VERSION ""

NS_ :

BS_:

BU_: External_Tool ADAS RDR05 RDR_Fusion_Partner RDR_Gateway

BO_ 1600 RDR_TRACKER_OBJ_049: 64 RDR05
 SG_ OBJ_ALIVE_TIME_049 : 255|16@0+ (1,0) [0|65535] "ms"  ADAS
 SG_ OBJ_ACCELERATION_LONG_ERR_049 : 215|8@0+ (0.025,0) [0|6.375] "m/s^2"  ADAS
 SG_ OBJ_ACCELERATION_LAT_ERR_049 : 223|8@0+ (0.025,0) [0|6.375] "m/s^2"  ADAS
 SG_ OBJ_VELOCITY_LONG_ERR_049 : 143|8@0+ (0.05,0) [0|12.75] "m/s"  ADAS
 SG_ OBJ_VELOCITY_LAT_ERR_049 : 151|8@0+ (0.05,0) [0|12.75] "m/s"  ADAS
 SG_ OBJ_POS_LONG_ERR_049 : 95|8@0+ (0.025,0) [0|6.375] "m"  ADAS
 SG_ OBJ_POS_LAT_ERR_049 : 103|8@0+ (0.025,0) [0|6.375] "m"  ADAS
 SG_ OBJ_TRACK_MOTION_MODEL_049 : 9|2@0+ (1,0) [0|3] "NA"  ADAS
 SG_ OBJ_DIMENSION_WIDTH_049 : 17|10@0+ (0.01,0) [0|10.23] "m"  ADAS
 SG_ OBJ_DIMENSION_LENGTH_049 : 37|12@0+ (0.01,0) [0|40.95] "m"  ADAS
 SG_ OBJ_EXISTENCE_PROB_049 : 229|14@0+ (0.0001,0) [0|1] "NA"  ADAS
 SG_ OBJ_YAW_ANGLE_049 : 155|12@0+ (0.005,-10) [-10|10.475] "rad"  ADAS
 SG_ OBJ_YAW_ANGLE_ERR_049 : 175|7@0+ (0.01,0) [0|1.27] "rad"  ADAS
 SG_ OBJ_ID_049 : 7|8@0+ (1,0) [0|255] "NA"  ADAS
 SG_ OBJ_MOVEMENT_STATUS_049 : 196|3@0+ (1,0) [0|3] "NA"  ADAS
 SG_ OBJ_MEASUREMENT_STATUS_049 : 14|3@0+ (1,0) [0|7] "NA"  ADAS
 SG_ OBJ_POS_LONG_049 : 63|16@0+ (0.01,-327) [-327|327] "m"  ADAS
 SG_ OBJ_POS_LAT_049 : 79|16@0+ (0.01,-327) [-327|327] "m"  ADAS
 SG_ OBJ_VELOCITY_LONG_049 : 110|15@0+ (0.01,-163) [-163|163] "m/s"  ADAS
 SG_ OBJ_VELOCITY_LAT_049 : 126|15@0+ (0.01,-163) [-163|163] "m/s"  ADAS
 SG_ OBJ_ACCELERATION_LONG_049 : 193|10@0+ (0.05,-20) [-20|20] "m/s^2"  ADAS
 SG_ OBJ_ACCELERATION_LAT_049 : 177|10@0+ (0.05,-20) [-20|20] "m/s^2"  ADAS
 SG_ OBJ_VEH_TRACK_FLAG_049 : 10|1@0+ (1,0) [0|1] "NA"  ADAS
 SG_ OBJ_MH_CYCLE_COUNTER_049 : 487|8@0+ (1,0) [0|255] "NA"  ADAS
 SG_ OBJ_MH_CRC16_049 : 495|16@0+ (1,0) [0|65535] "NA"  ADAS
 SG_ OBJ_TIMESTAMP_OFFSET_049 : 247|8@0+ (1,-127) [-127|128] "ms"  ADAS
 SG_ OBJ_DIMENSION_WIDTH_ERR_049 : 23|6@0+ (0.01,0) [0|0.63] "m"  ADAS
 SG_ OBJ_DIMENSION_LENGTH_ERR_049 : 41|10@0+ (0.01,0) [0|10.23] "m"  ADAS
 SG_ OBJ_CLS_TYPE1_049 : 271|4@0+ (1,0) [0|15] "NA"  ADAS
 SG_ OBJ_CLS_TYPE1_PROB_049 : 303|8@0+ (0.004,0) [0|1] "NA"  ADAS
 SG_ OBJ_CLS_TYPE2_049 : 267|4@0+ (1,0) [0|15] "NA"  ADAS
 SG_ OBJ_CLS_TYPE2_PROB_049 : 311|8@0+ (0.004,0) [0|1] "NA"  ADAS
 SG_ OBJ_CLS_TYPE3_049 : 279|4@0+ (1,0) [0|15] "NA"  ADAS
 SG_ OBJ_CLS_TYPE3_PROB_049 : 319|8@0+ (0.004,0) [0|1] "NA"  ADAS
 SG_ OBJ_CLS_TYPE4_049 : 275|4@0+ (1,0) [0|15] "NA"  ADAS
 SG_ OBJ_CLS_TYPE4_PROB_049 : 327|8@0+ (0.004,0) [0|1] "NA"  ADAS
 SG_ OBJ_CLS_TYPE5_049 : 287|4@0+ (1,0) [0|15] "NA"  ADAS
 SG_ OBJ_CLS_TYPE5_PROB_049 : 335|8@0+ (0.004,0) [0|1] "NA"  ADAS
 SG_ OBJ_CLS_TYPE6_049 : 282|4@0+ (1,0) [0|15] "NA"  ADAS
 SG_ OBJ_CLS_TYPE6_PROB_049 : 343|8@0+ (0.004,0) [0|1] "NA"  ADAS
 SG_ OBJ_RCS_049 : 351|7@0+ (1,-64) [-64|63] "dBsm"  ADAS
 SG_ OBJ_REF_PT_LONG_OFFSET_049 : 357|14@0+ (0.0001,0) [0|1] "NA"  ADAS
 SG_ OBJ_REF_PT_LAT_OFFSET_049 : 370|14@0+ (0.0001,0) [0|1] "NA"  ADAS
 SG_ OBJ_YAW_RATE_049 : 399|10@0+ (0.005,-2.24) [-2.24|2.24] "rad/s"  ADAS
 SG_ OBJ_YAW_RATE_ERR_049 : 388|5@0+ (0.025,0) [0|0.775] "rad/s"  ADAS
 SG_ OBJ_GROUP_ID_049 : 405|6@0+ (1,0) [0|63] "NA"  ADAS
 SG_ OBJ_POS_ERR_CRR_COEF_049 : 415|8@0+ (0.01,-1.2) [-1.2|1] "NA"  ADAS
 SG_ OBJ_VELOCITY_ERR_CRR_COEF_049 : 423|8@0+ (0.01,-1.2) [-1.2|1] "NA"  ADAS
 SG_ OBJ_ACCEL_ERR_CRR_COEF_049 : 431|8@0+ (0.01,-1.2) [-1.2|1] "NA"  ADAS

BO_ 1601 RDR_TRACKER_OBJ_050: 64 RDR05
 SG_ OBJ_ALIVE_TIME_050 : 255|16@0+ (1,0) [0|65535] "ms"  ADAS
 SG_ OBJ_ACCELERATION_LONG_ERR_050 : 215|8@0+ (0.025,0) [0|6.375] "m/s^2"  ADAS
 SG_ OBJ_ACCELERATION_LAT_ERR_050 : 223|8@0+ (0.025,0) [0|6.375] "m/s^2"  ADAS
 SG_ OBJ_VELOCITY_LONG_ERR_050 : 143|8@0+ (0.05,0) [0|12.75] "m/s"  ADAS
 SG_ OBJ_VELOCITY_LAT_ERR_050 : 151|8@0+ (0.05,0) [0|12.75] "m/s"  ADAS
 SG_ OBJ_POS_LONG_ERR_050 : 95|8@0+ (0.025,0) [0|6.375] "m"  ADAS
 SG_ OBJ_POS_LAT_ERR_050 : 103|8@0+ (0.025,0) [0|6.375] "m"  ADAS
 SG_ OBJ_TRACK_MOTION_MODEL_050 : 9|2@0+ (1,0) [0|3] "NA"  ADAS
 SG_ OBJ_DIMENSION_WIDTH_050 : 17|10@0+ (0.01,0) [0|10.23] "m"  ADAS
 SG_ OBJ_DIMENSION_LENGTH_050 : 37|12@0+ (0.01,0) [0|40.95] "m"  ADAS
 SG_ OBJ_EXISTENCE_PROB_050 : 229|14@0+ (0.0001,0) [0|1] "NA"  ADAS
 SG_ OBJ_YAW_ANGLE_050 : 155|12@0+ (0.005,-10) [-10|10.475] "rad"  ADAS
 SG_ OBJ_YAW_ANGLE_ERR_050 : 175|7@0+ (0.01,0) [0|1.27] "rad"  ADAS
 SG_ OBJ_ID_050 : 7|8@0+ (1,0) [0|255] "NA"  ADAS
 SG_ OBJ_MOVEMENT_STATUS_050 : 196|3@0+ (1,0) [0|3] "NA"  ADAS
 SG_ OBJ_MEASUREMENT_STATUS_050 : 14|3@0+ (1,0) [0|7] "NA"  ADAS
 SG_ OBJ_POS_LONG_050 : 63|16@0+ (0.01,-327) [-327|327] "m"  ADAS
 SG_ OBJ_POS_LAT_050 : 79|16@0+ (0.01,-327) [-327|327] "m"  ADAS
 SG_ OBJ_VELOCITY_LONG_050 : 110|15@0+ (0.01,-163) [-163|163] "m/s"  ADAS
 SG_ OBJ_VELOCITY_LAT_050 : 126|15@0+ (0.01,-163) [-163|163] "m/s"  ADAS
 SG_ OBJ_ACCELERATION_LONG_050 : 193|10@0+ (0.05,-20) [-20|20] "m/s^2"  ADAS
 SG_ OBJ_ACCELERATION_LAT_050 : 177|10@0+ (0.05,-20) [-20|20] "m/s^2"  ADAS
 SG_ OBJ_VEH_TRACK_FLAG_050 : 10|1@0+ (1,0) [0|1] "NA"  ADAS
 SG_ OBJ_MH_CYCLE_COUNTER_050 : 487|8@0+ (1,0) [0|255] "NA"  ADAS
 SG_ OBJ_MH_CRC16_050 : 495|16@0+ (1,0) [0|65535] "NA"  ADAS
 SG_ OBJ_TIMESTAMP_OFFSET_050 : 247|8@0+ (1,-127) [-127|128] "ms"  ADAS
 SG_ OBJ_DIMENSION_WIDTH_ERR_050 : 23|6@0+ (0.01,0) [0|0.63] "m"  ADAS
 SG_ OBJ_DIMENSION_LENGTH_ERR_050 : 41|10@0+ (0.01,0) [0|10.23] "m"  ADAS
 SG_ OBJ_CLS_TYPE1_050 : 271|4@0+ (1,0) [0|15] "NA"  ADAS
 SG_ OBJ_CLS_TYPE1_PROB_050 : 303|8@0+ (0.004,0) [0|1] "NA"  ADAS
 SG_ OBJ_CLS_TYPE2_050 : 267|4@0+ (1,0) [0|15] "NA"  ADAS
 SG_ OBJ_CLS_TYPE2_PROB_050 : 311|8@0+ (0.004,0) [0|1] "NA"  ADAS
 SG_ OBJ_CLS_TYPE3_050 : 279|4@0+ (1,0) [0|15] "NA"  ADAS
 SG_ OBJ_CLS_TYPE3_PROB_050 : 319|8@0+ (0.004,0) [0|1] "NA"  ADAS
 SG_ OBJ_CLS_TYPE4_050 : 275|4@0+ (1,0) [0|15] "NA"  ADAS
 SG_ OBJ_CLS_TYPE4_PROB_050 : 327|8@0+ (0.004,0) [0|1] "NA"  ADAS
 SG_ OBJ_CLS_TYPE5_050 : 287|4@0+ (1,0) [0|15] "NA"  ADAS
 SG_ OBJ_CLS_TYPE5_PROB_050 : 335|8@0+ (0.004,0) [0|1] "NA"  ADAS
 SG_ OBJ_CLS_TYPE6_050 : 282|4@0+ (1,0) [0|15] "NA"  ADAS
 SG_ OBJ_CLS_TYPE6_PROB_050 : 343|8@0+ (0.004,0) [0|1] "NA"  ADAS
 SG_ OBJ_RCS_050 : 351|7@0+ (1,-64) [-64|63] "dBsm"  ADAS
 SG_ OBJ_REF_PT_LONG_OFFSET_050 : 357|14@0+ (0.0001,0) [0|1] "NA"  ADAS
 SG_ OBJ_REF_PT_LAT_OFFSET_050 : 370|14@0+ (0.0001,0) [0|1] "NA"  ADAS
 SG_ OBJ_YAW_RATE_050 : 399|10@0+ (0.005,-2.24) [-2.24|2.24] "rad/s"  ADAS
 SG_ OBJ_YAW_RATE_ERR_050 : 388|5@0+ (0.025,0) [0|0.775] "rad/s"  ADAS
 SG_ OBJ_GROUP_ID_050 : 405|6@0+ (1,0) [0|63] "NA"  ADAS
 SG_ OBJ_POS_ERR_CRR_COEF_050 : 415|8@0+ (0.01,-1.2) [-1.2|1] "NA"  ADAS
 SG_ OBJ_VELOCITY_ERR_CRR_COEF_050 : 423|8@0+ (0.01,-1.2) [-1.2|1] "NA"  ADAS
 SG_ OBJ_ACCEL_ERR_CRR_COEF_050 : 431|8@0+ (0.01,-1.2) [-1.2|1] "NA"  ADAS

BO_ 1602 RDR_TRACKER_OBJ_051: 64 RDR05
 SG_ OBJ_ALIVE_TIME_051 : 255|16@0+ (1,0) [0|65535] "ms"  ADAS
 SG_ OBJ_ACCELERATION_LONG_ERR_051 : 215|8@0+ (0.025,0) [0|6.375] "m/s^2"  ADAS
 SG_ OBJ_ACCELERATION_LAT_ERR_051 : 223|8@0+ (0.025,0) [0|6.375] "m/s^2"  ADAS
 SG_ OBJ_VELOCITY_LONG_ERR_051 : 143|8@0+ (0.05,0) [0|12.75] "m/s"  ADAS
 SG_ OBJ_VELOCITY_LAT_ERR_051 : 151|8@0+ (0.05,0) [0|12.75] "m/s"  ADAS
 SG_ OBJ_POS_LONG_ERR_051 : 95|8@0+ (0.025,0) [0|6.375] "m"  ADAS
 SG_ OBJ_POS_LAT_ERR_051 : 103|8@0+ (0.025,0) [0|6.375] "m"  ADAS
 SG_ OBJ_TRACK_MOTION_MODEL_051 : 9|2@0+ (1,0) [0|3] "NA"  ADAS
 SG_ OBJ_DIMENSION_WIDTH_051 : 17|10@0+ (0.01,0) [0|10.23] "m"  ADAS
 SG_ OBJ_DIMENSION_LENGTH_051 : 37|12@0+ (0.01,0) [0|40.95] "m"  ADAS
 SG_ OBJ_EXISTENCE_PROB_051 : 229|14@0+ (0.0001,0) [0|1] "NA"  ADAS
 SG_ OBJ_YAW_ANGLE_051 : 155|12@0+ (0.005,-10) [-10|10.475] "rad"  ADAS
 SG_ OBJ_YAW_ANGLE_ERR_051 : 175|7@0+ (0.01,0) [0|1.27] "rad"  ADAS
 SG_ OBJ_ID_051 : 7|8@0+ (1,0) [0|255] "NA"  ADAS
 SG_ OBJ_MOVEMENT_STATUS_051 : 196|3@0+ (1,0) [0|3] "NA"  ADAS
 SG_ OBJ_MEASUREMENT_STATUS_051 : 14|3@0+ (1,0) [0|7] "NA"  ADAS
 SG_ OBJ_POS_LONG_051 : 63|16@0+ (0.01,-327) [-327|327] "m"  ADAS
 SG_ OBJ_POS_LAT_051 : 79|16@0+ (0.01,-327) [-327|327] "m"  ADAS
 SG_ OBJ_VELOCITY_LONG_051 : 110|15@0+ (0.01,-163) [-163|163] "m/s"  ADAS
 SG_ OBJ_VELOCITY_LAT_051 : 126|15@0+ (0.01,-163) [-163|163] "m/s"  ADAS
 SG_ OBJ_ACCELERATION_LONG_051 : 193|10@0+ (0.05,-20) [-20|20] "m/s^2"  ADAS
 SG_ OBJ_ACCELERATION_LAT_051 : 177|10@0+ (0.05,-20) [-20|20] "m/s^2"  ADAS
 SG_ OBJ_VEH_TRACK_FLAG_051 : 10|1@0+ (1,0) [0|1] "NA"  ADAS
 SG_ OBJ_MH_CYCLE_COUNTER_051 : 487|8@0+ (1,0) [0|255] "NA"  ADAS
 SG_ OBJ_MH_CRC16_051 : 495|16@0+ (1,0) [0|65535] "NA"  ADAS
 SG_ OBJ_TIMESTAMP_OFFSET_051 : 247|8@0+ (1,-127) [-127|128] "ms"  ADAS
 SG_ OBJ_DIMENSION_WIDTH_ERR_051 : 23|6@0+ (0.01,0) [0|0.63] "m"  ADAS
 SG_ OBJ_DIMENSION_LENGTH_ERR_051 : 41|10@0+ (0.01,0) [0|10.23] "m"  ADAS
 SG_ OBJ_CLS_TYPE1_051 : 271|4@0+ (1,0) [0|15] "NA"  ADAS
 SG_ OBJ_CLS_TYPE1_PROB_051 : 303|8@0+ (0.004,0) [0|1] "NA"  ADAS
 SG_ OBJ_CLS_TYPE2_051 : 267|4@0+ (1,0) [0|15] "NA"  ADAS
 SG_ OBJ_CLS_TYPE2_PROB_051 : 311|8@0+ (0.004,0) [0|1] "NA"  ADAS
 SG_ OBJ_CLS_TYPE3_051 : 279|4@0+ (1,0) [0|15] "NA"  ADAS
 SG_ OBJ_CLS_TYPE3_PROB_051 : 319|8@0+ (0.004,0) [0|1] "NA"  ADAS
 SG_ OBJ_CLS_TYPE4_051 : 275|4@0+ (1,0) [0|15] "NA"  ADAS
 SG_ OBJ_CLS_TYPE4_PROB_051 : 327|8@0+ (0.004,0) [0|1] "NA"  ADAS
 SG_ OBJ_CLS_TYPE5_051 : 287|4@0+ (1,0) [0|15] "NA"  ADAS
 SG_ OBJ_CLS_TYPE5_PROB_051 : 335|8@0+ (0.004,0) [0|1] "NA"  ADAS
 SG_ OBJ_CLS_TYPE6_051 : 282|4@0+ (1,0) [0|15] "NA"  ADAS
 SG_ OBJ_CLS_TYPE6_PROB_051 : 343|8@0+ (0.004,0) [0|1] "NA"  ADAS
 SG_ OBJ_RCS_051 : 351|7@0+ (1,-64) [-64|63] "dBsm"  ADAS
 SG_ OBJ_REF_PT_LONG_OFFSET_051 : 357|14@0+ (0.0001,0) [0|1] "NA"  ADAS
 SG_ OBJ_REF_PT_LAT_OFFSET_051 : 370|14@0+ (0.0001,0) [0|1] "NA"  ADAS
 SG_ OBJ_YAW_RATE_051 : 399|10@0+ (0.005,-2.24) [-2.24|2.24] "rad/s"  ADAS
 SG_ OBJ_YAW_RATE_ERR_051 : 388|5@0+ (0.025,0) [0|0.775] "rad/s"  ADAS
 SG_ OBJ_GROUP_ID_051 : 405|6@0+ (1,0) [0|63] "NA"  ADAS
 SG_ OBJ_POS_ERR_CRR_COEF_051 : 415|8@0+ (0.01,-1.2) [-1.2|1] "NA"  ADAS
 SG_ OBJ_VELOCITY_ERR_CRR_COEF_051 : 423|8@0+ (0.01,-1.2) [-1.2|1] "NA"  ADAS
 SG_ OBJ_ACCEL_ERR_CRR_COEF_051 : 431|8@0+ (0.01,-1.2) [-1.2|1] "NA"  ADAS

BO_ 1603 RDR_TRACKER_OBJ_052: 64 RDR05
 SG_ OBJ_ALIVE_TIME_052 : 255|16@0+ (1,0) [0|65535] "ms"  ADAS
 SG_ OBJ_ACCELERATION_LONG_ERR_052 : 215|8@0+ (0.025,0) [0|6.375] "m/s^2"  ADAS
 SG_ OBJ_ACCELERATION_LAT_ERR_052 : 223|8@0+ (0.025,0) [0|6.375] "m/s^2"  ADAS
 SG_ OBJ_VELOCITY_LONG_ERR_052 : 143|8@0+ (0.05,0) [0|12.75] "m/s"  ADAS
 SG_ OBJ_VELOCITY_LAT_ERR_052 : 151|8@0+ (0.05,0) [0|12.75] "m/s"  ADAS
 SG_ OBJ_POS_LONG_ERR_052 : 95|8@0+ (0.025,0) [0|6.375] "m"  ADAS
 SG_ OBJ_POS_LAT_ERR_052 : 103|8@0+ (0.025,0) [0|6.375] "m"  ADAS
 SG_ OBJ_TRACK_MOTION_MODEL_052 : 9|2@0+ (1,0) [0|3] "NA"  ADAS
 SG_ OBJ_DIMENSION_WIDTH_052 : 17|10@0+ (0.01,0) [0|10.23] "m"  ADAS
 SG_ OBJ_DIMENSION_LENGTH_052 : 37|12@0+ (0.01,0) [0|40.95] "m"  ADAS
 SG_ OBJ_EXISTENCE_PROB_052 : 229|14@0+ (0.0001,0) [0|1] "NA"  ADAS
 SG_ OBJ_YAW_ANGLE_052 : 155|12@0+ (0.005,-10) [-10|10.475] "rad"  ADAS
 SG_ OBJ_YAW_ANGLE_ERR_052 : 175|7@0+ (0.01,0) [0|1.27] "rad"  ADAS
 SG_ OBJ_ID_052 : 7|8@0+ (1,0) [0|255] "NA"  ADAS
 SG_ OBJ_MOVEMENT_STATUS_052 : 196|3@0+ (1,0) [0|3] "NA"  ADAS
 SG_ OBJ_MEASUREMENT_STATUS_052 : 14|3@0+ (1,0) [0|7] "NA"  ADAS
 SG_ OBJ_POS_LONG_052 : 63|16@0+ (0.01,-327) [-327|327] "m"  ADAS
 SG_ OBJ_POS_LAT_052 : 79|16@0+ (0.01,-327) [-327|327] "m"  ADAS
 SG_ OBJ_VELOCITY_LONG_052 : 110|15@0+ (0.01,-163) [-163|163] "m/s"  ADAS
 SG_ OBJ_VELOCITY_LAT_052 : 126|15@0+ (0.01,-163) [-163|163] "m/s"  ADAS
 SG_ OBJ_ACCELERATION_LONG_052 : 193|10@0+ (0.05,-20) [-20|20] "m/s^2"  ADAS
 SG_ OBJ_ACCELERATION_LAT_052 : 177|10@0+ (0.05,-20) [-20|20] "m/s^2"  ADAS
 SG_ OBJ_VEH_TRACK_FLAG_052 : 10|1@0+ (1,0) [0|1] "NA"  ADAS
 SG_ OBJ_MH_CYCLE_COUNTER_052 : 487|8@0+ (1,0) [0|255] "NA"  ADAS
 SG_ OBJ_MH_CRC16_052 : 495|16@0+ (1,0) [0|65535] "NA"  ADAS
 SG_ OBJ_TIMESTAMP_OFFSET_052 : 247|8@0+ (1,-127) [-127|128] "ms"  ADAS
 SG_ OBJ_DIMENSION_WIDTH_ERR_052 : 23|6@0+ (0.01,0) [0|0.63] "m"  ADAS
 SG_ OBJ_DIMENSION_LENGTH_ERR_052 : 41|10@0+ (0.01,0) [0|10.23] "m"  ADAS
 SG_ OBJ_CLS_TYPE1_052 : 271|4@0+ (1,0) [0|15] "NA"  ADAS
 SG_ OBJ_CLS_TYPE1_PROB_052 : 303|8@0+ (0.004,0) [0|1] "NA"  ADAS
 SG_ OBJ_CLS_TYPE2_052 : 267|4@0+ (1,0) [0|15] "NA"  ADAS
 SG_ OBJ_CLS_TYPE2_PROB_052 : 311|8@0+ (0.004,0) [0|1] "NA"  ADAS
 SG_ OBJ_CLS_TYPE3_052 : 279|4@0+ (1,0) [0|15] "NA"  ADAS
 SG_ OBJ_CLS_TYPE3_PROB_052 : 319|8@0+ (0.004,0) [0|1] "NA"  ADAS
 SG_ OBJ_CLS_TYPE4_052 : 275|4@0+ (1,0) [0|15] "NA"  ADAS
 SG_ OBJ_CLS_TYPE4_PROB_052 : 327|8@0+ (0.004,0) [0|1] "NA"  ADAS
 SG_ OBJ_CLS_TYPE5_052 : 287|4@0+ (1,0) [0|15] "NA"  ADAS
 SG_ OBJ_CLS_TYPE5_PROB_052 : 335|8@0+ (0.004,0) [0|1] "NA"  ADAS
 SG_ OBJ_CLS_TYPE6_052 : 282|4@0+ (1,0) [0|15] "NA"  ADAS
 SG_ OBJ_CLS_TYPE6_PROB_052 : 343|8@0+ (0.004,0) [0|1] "NA"  ADAS
 SG_ OBJ_RCS_052 : 351|7@0+ (1,-64) [-64|63] "dBsm"  ADAS
 SG_ OBJ_REF_PT_LONG_OFFSET_052 : 357|14@0+ (0.0001,0) [0|1] "NA"  ADAS
 SG_ OBJ_REF_PT_LAT_OFFSET_052 : 370|14@0+ (0.0001,0) [0|1] "NA"  ADAS
 SG_ OBJ_YAW_RATE_052 : 399|10@0+ (0.005,-2.24) [-2.24|2.24] "rad/s"  ADAS
 SG_ OBJ_YAW_RATE_ERR_052 : 388|5@0+ (0.025,0) [0|0.775] "rad/s"  ADAS
 SG_ OBJ_GROUP_ID_052 : 405|6@0+ (1,0) [0|63] "NA"  ADAS
 SG_ OBJ_POS_ERR_CRR_COEF_052 : 415|8@0+ (0.01,-1.2) [-1.2|1] "NA"  ADAS
 SG_ OBJ_VELOCITY_ERR_CRR_COEF_052 : 423|8@0+ (0.01,-1.2) [-1.2|1] "NA"  ADAS
 SG_ OBJ_ACCEL_ERR_CRR_COEF_052 : 431|8@0+ (0.01,-1.2) [-1.2|1] "NA"  ADAS

BO_ 1604 RDR_TRACKER_OBJ_053: 64 RDR05
 SG_ OBJ_ALIVE_TIME_053 : 255|16@0+ (1,0) [0|65535] "ms"  ADAS
 SG_ OBJ_ACCELERATION_LONG_ERR_053 : 215|8@0+ (0.025,0) [0|6.375] "m/s^2"  ADAS
 SG_ OBJ_ACCELERATION_LAT_ERR_053 : 223|8@0+ (0.025,0) [0|6.375] "m/s^2"  ADAS
 SG_ OBJ_VELOCITY_LONG_ERR_053 : 143|8@0+ (0.05,0) [0|12.75] "m/s"  ADAS
 SG_ OBJ_VELOCITY_LAT_ERR_053 : 151|8@0+ (0.05,0) [0|12.75] "m/s"  ADAS
 SG_ OBJ_POS_LONG_ERR_053 : 95|8@0+ (0.025,0) [0|6.375] "m"  ADAS
 SG_ OBJ_POS_LAT_ERR_053 : 103|8@0+ (0.025,0) [0|6.375] "m"  ADAS
 SG_ OBJ_TRACK_MOTION_MODEL_053 : 9|2@0+ (1,0) [0|3] "NA"  ADAS
 SG_ OBJ_DIMENSION_WIDTH_053 : 17|10@0+ (0.01,0) [0|10.23] "m"  ADAS
 SG_ OBJ_DIMENSION_LENGTH_053 : 37|12@0+ (0.01,0) [0|40.95] "m"  ADAS
 SG_ OBJ_EXISTENCE_PROB_053 : 229|14@0+ (0.0001,0) [0|1] "NA"  ADAS
 SG_ OBJ_YAW_ANGLE_053 : 155|12@0+ (0.005,-10) [-10|10.475] "rad"  ADAS
 SG_ OBJ_YAW_ANGLE_ERR_053 : 175|7@0+ (0.01,0) [0|1.27] "rad"  ADAS
 SG_ OBJ_ID_053 : 7|8@0+ (1,0) [0|255] "NA"  ADAS
 SG_ OBJ_MOVEMENT_STATUS_053 : 196|3@0+ (1,0) [0|3] "NA"  ADAS
 SG_ OBJ_MEASUREMENT_STATUS_053 : 14|3@0+ (1,0) [0|7] "NA"  ADAS
 SG_ OBJ_POS_LONG_053 : 63|16@0+ (0.01,-327) [-327|327] "m"  ADAS
 SG_ OBJ_POS_LAT_053 : 79|16@0+ (0.01,-327) [-327|327] "m"  ADAS
 SG_ OBJ_VELOCITY_LONG_053 : 110|15@0+ (0.01,-163) [-163|163] "m/s"  ADAS
 SG_ OBJ_VELOCITY_LAT_053 : 126|15@0+ (0.01,-163) [-163|163] "m/s"  ADAS
 SG_ OBJ_ACCELERATION_LONG_053 : 193|10@0+ (0.05,-20) [-20|20] "m/s^2"  ADAS
 SG_ OBJ_ACCELERATION_LAT_053 : 177|10@0+ (0.05,-20) [-20|20] "m/s^2"  ADAS
 SG_ OBJ_VEH_TRACK_FLAG_053 : 10|1@0+ (1,0) [0|1] "NA"  ADAS
 SG_ OBJ_MH_CYCLE_COUNTER_053 : 487|8@0+ (1,0) [0|255] "NA"  ADAS
 SG_ OBJ_MH_CRC16_053 : 495|16@0+ (1,0) [0|65535] "NA"  ADAS
 SG_ OBJ_TIMESTAMP_OFFSET_053 : 247|8@0+ (1,-127) [-127|128] "ms"  ADAS
 SG_ OBJ_DIMENSION_WIDTH_ERR_053 : 23|6@0+ (0.01,0) [0|0.63] "m"  ADAS
 SG_ OBJ_DIMENSION_LENGTH_ERR_053 : 41|10@0+ (0.01,0) [0|10.23] "m"  ADAS
 SG_ OBJ_CLS_TYPE1_053 : 271|4@0+ (1,0) [0|15] "NA"  ADAS
 SG_ OBJ_CLS_TYPE1_PROB_053 : 303|8@0+ (0.004,0) [0|1] "NA"  ADAS
 SG_ OBJ_CLS_TYPE2_053 : 267|4@0+ (1,0) [0|15] "NA"  ADAS
 SG_ OBJ_CLS_TYPE2_PROB_053 : 311|8@0+ (0.004,0) [0|1] "NA"  ADAS
 SG_ OBJ_CLS_TYPE3_053 : 279|4@0+ (1,0) [0|15] "NA"  ADAS
 SG_ OBJ_CLS_TYPE3_PROB_053 : 319|8@0+ (0.004,0) [0|1] "NA"  ADAS
 SG_ OBJ_CLS_TYPE4_053 : 275|4@0+ (1,0) [0|15] "NA"  ADAS
 SG_ OBJ_CLS_TYPE4_PROB_053 : 327|8@0+ (0.004,0) [0|1] "NA"  ADAS
 SG_ OBJ_CLS_TYPE5_053 : 287|4@0+ (1,0) [0|15] "NA"  ADAS
 SG_ OBJ_CLS_TYPE5_PROB_053 : 335|8@0+ (0.004,0) [0|1] "NA"  ADAS
 SG_ OBJ_CLS_TYPE6_053 : 282|4@0+ (1,0) [0|15] "NA"  ADAS
 SG_ OBJ_CLS_TYPE6_PROB_053 : 343|8@0+ (0.004,0) [0|1] "NA"  ADAS
 SG_ OBJ_RCS_053 : 351|7@0+ (1,-64) [-64|63] "dBsm"  ADAS
 SG_ OBJ_REF_PT_LONG_OFFSET_053 : 357|14@0+ (0.0001,0) [0|1] "NA"  ADAS
 SG_ OBJ_REF_PT_LAT_OFFSET_053 : 370|14@0+ (0.0001,0) [0|1] "NA"  ADAS
 SG_ OBJ_YAW_RATE_053 : 399|10@0+ (0.005,-2.24) [-2.24|2.24] "rad/s"  ADAS
 SG_ OBJ_YAW_RATE_ERR_053 : 388|5@0+ (0.025,0) [0|0.775] "rad/s"  ADAS
 SG_ OBJ_GROUP_ID_053 : 405|6@0+ (1,0) [0|63] "NA"  ADAS
 SG_ OBJ_POS_ERR_CRR_COEF_053 : 415|8@0+ (0.01,-1.2) [-1.2|1] "NA"  ADAS
 SG_ OBJ_VELOCITY_ERR_CRR_COEF_053 : 423|8@0+ (0.01,-1.2) [-1.2|1] "NA"  ADAS
 SG_ OBJ_ACCEL_ERR_CRR_COEF_053 : 431|8@0+ (0.01,-1.2) [-1.2|1] "NA"  ADAS

BO_ 1605 RDR_TRACKER_OBJ_054: 64 RDR05
 SG_ OBJ_ALIVE_TIME_054 : 255|16@0+ (1,0) [0|65535] "ms"  ADAS
 SG_ OBJ_ACCELERATION_LONG_ERR_054 : 215|8@0+ (0.025,0) [0|6.375] "m/s^2"  ADAS
 SG_ OBJ_ACCELERATION_LAT_ERR_054 : 223|8@0+ (0.025,0) [0|6.375] "m/s^2"  ADAS
 SG_ OBJ_VELOCITY_LONG_ERR_054 : 143|8@0+ (0.05,0) [0|12.75] "m/s"  ADAS
 SG_ OBJ_VELOCITY_LAT_ERR_054 : 151|8@0+ (0.05,0) [0|12.75] "m/s"  ADAS
 SG_ OBJ_POS_LONG_ERR_054 : 95|8@0+ (0.025,0) [0|6.375] "m"  ADAS
 SG_ OBJ_POS_LAT_ERR_054 : 103|8@0+ (0.025,0) [0|6.375] "m"  ADAS
 SG_ OBJ_TRACK_MOTION_MODEL_054 : 9|2@0+ (1,0) [0|3] "NA"  ADAS
 SG_ OBJ_DIMENSION_WIDTH_054 : 17|10@0+ (0.01,0) [0|10.23] "m"  ADAS
 SG_ OBJ_DIMENSION_LENGTH_054 : 37|12@0+ (0.01,0) [0|40.95] "m"  ADAS
 SG_ OBJ_EXISTENCE_PROB_054 : 229|14@0+ (0.0001,0) [0|1] "NA"  ADAS
 SG_ OBJ_YAW_ANGLE_054 : 155|12@0+ (0.005,-10) [-10|10.475] "rad"  ADAS
 SG_ OBJ_YAW_ANGLE_ERR_054 : 175|7@0+ (0.01,0) [0|1.27] "rad"  ADAS
 SG_ OBJ_ID_054 : 7|8@0+ (1,0) [0|255] "NA"  ADAS
 SG_ OBJ_MOVEMENT_STATUS_054 : 196|3@0+ (1,0) [0|3] "NA"  ADAS
 SG_ OBJ_MEASUREMENT_STATUS_054 : 14|3@0+ (1,0) [0|7] "NA"  ADAS
 SG_ OBJ_POS_LONG_054 : 63|16@0+ (0.01,-327) [-327|327] "m"  ADAS
 SG_ OBJ_POS_LAT_054 : 79|16@0+ (0.01,-327) [-327|327] "m"  ADAS
 SG_ OBJ_VELOCITY_LONG_054 : 110|15@0+ (0.01,-163) [-163|163] "m/s"  ADAS
 SG_ OBJ_VELOCITY_LAT_054 : 126|15@0+ (0.01,-163) [-163|163] "m/s"  ADAS
 SG_ OBJ_ACCELERATION_LONG_054 : 193|10@0+ (0.05,-20) [-20|20] "m/s^2"  ADAS
 SG_ OBJ_ACCELERATION_LAT_054 : 177|10@0+ (0.05,-20) [-20|20] "m/s^2"  ADAS
 SG_ OBJ_VEH_TRACK_FLAG_054 : 10|1@0+ (1,0) [0|1] "NA"  ADAS
 SG_ OBJ_MH_CYCLE_COUNTER_054 : 487|8@0+ (1,0) [0|255] "NA"  ADAS
 SG_ OBJ_MH_CRC16_054 : 495|16@0+ (1,0) [0|65535] "NA"  ADAS
 SG_ OBJ_TIMESTAMP_OFFSET_054 : 247|8@0+ (1,-127) [-127|128] "ms"  ADAS
 SG_ OBJ_DIMENSION_WIDTH_ERR_054 : 23|6@0+ (0.01,0) [0|0.63] "m"  ADAS
 SG_ OBJ_DIMENSION_LENGTH_ERR_054 : 41|10@0+ (0.01,0) [0|10.23] "m"  ADAS
 SG_ OBJ_CLS_TYPE1_054 : 271|4@0+ (1,0) [0|15] "NA"  ADAS
 SG_ OBJ_CLS_TYPE1_PROB_054 : 303|8@0+ (0.004,0) [0|1] "NA"  ADAS
 SG_ OBJ_CLS_TYPE2_054 : 267|4@0+ (1,0) [0|15] "NA"  ADAS
 SG_ OBJ_CLS_TYPE2_PROB_054 : 311|8@0+ (0.004,0) [0|1] "NA"  ADAS
 SG_ OBJ_CLS_TYPE3_054 : 279|4@0+ (1,0) [0|15] "NA"  ADAS
 SG_ OBJ_CLS_TYPE3_PROB_054 : 319|8@0+ (0.004,0) [0|1] "NA"  ADAS
 SG_ OBJ_CLS_TYPE4_054 : 275|4@0+ (1,0) [0|15] "NA"  ADAS
 SG_ OBJ_CLS_TYPE4_PROB_054 : 327|8@0+ (0.004,0) [0|1] "NA"  ADAS
 SG_ OBJ_CLS_TYPE5_054 : 287|4@0+ (1,0) [0|15] "NA"  ADAS
 SG_ OBJ_CLS_TYPE5_PROB_054 : 335|8@0+ (0.004,0) [0|1] "NA"  ADAS
 SG_ OBJ_CLS_TYPE6_054 : 282|4@0+ (1,0) [0|15] "NA"  ADAS
 SG_ OBJ_CLS_TYPE6_PROB_054 : 343|8@0+ (0.004,0) [0|1] "NA"  ADAS
 SG_ OBJ_RCS_054 : 351|7@0+ (1,-64) [-64|63] "dBsm"  ADAS
 SG_ OBJ_REF_PT_LONG_OFFSET_054 : 357|14@0+ (0.0001,0) [0|1] "NA"  ADAS
 SG_ OBJ_REF_PT_LAT_OFFSET_054 : 370|14@0+ (0.0001,0) [0|1] "NA"  ADAS
 SG_ OBJ_YAW_RATE_054 : 399|10@0+ (0.005,-2.24) [-2.24|2.24] "rad/s"  ADAS
 SG_ OBJ_YAW_RATE_ERR_054 : 388|5@0+ (0.025,0) [0|0.775] "rad/s"  ADAS
 SG_ OBJ_GROUP_ID_054 : 405|6@0+ (1,0) [0|63] "NA"  ADAS
 SG_ OBJ_POS_ERR_CRR_COEF_054 : 415|8@0+ (0.01,-1.2) [-1.2|1] "NA"  ADAS
 SG_ OBJ_VELOCITY_ERR_CRR_COEF_054 : 423|8@0+ (0.01,-1.2) [-1.2|1] "NA"  ADAS
 SG_ OBJ_ACCEL_ERR_CRR_COEF_054 : 431|8@0+ (0.01,-1.2) [-1.2|1] "NA"  ADAS

BO_ 1606 RDR_TRACKER_OBJ_055: 64 RDR05
 SG_ OBJ_ALIVE_TIME_055 : 255|16@0+ (1,0) [0|65535] "ms"  ADAS
 SG_ OBJ_ACCELERATION_LONG_ERR_055 : 215|8@0+ (0.025,0) [0|6.375] "m/s^2"  ADAS
 SG_ OBJ_ACCELERATION_LAT_ERR_055 : 223|8@0+ (0.025,0) [0|6.375] "m/s^2"  ADAS
 SG_ OBJ_VELOCITY_LONG_ERR_055 : 143|8@0+ (0.05,0) [0|12.75] "m/s"  ADAS
 SG_ OBJ_VELOCITY_LAT_ERR_055 : 151|8@0+ (0.05,0) [0|12.75] "m/s"  ADAS
 SG_ OBJ_POS_LONG_ERR_055 : 95|8@0+ (0.025,0) [0|6.375] "m"  ADAS
 SG_ OBJ_POS_LAT_ERR_055 : 103|8@0+ (0.025,0) [0|6.375] "m"  ADAS
 SG_ OBJ_TRACK_MOTION_MODEL_055 : 9|2@0+ (1,0) [0|3] "NA"  ADAS
 SG_ OBJ_DIMENSION_WIDTH_055 : 17|10@0+ (0.01,0) [0|10.23] "m"  ADAS
 SG_ OBJ_DIMENSION_LENGTH_055 : 37|12@0+ (0.01,0) [0|40.95] "m"  ADAS
 SG_ OBJ_EXISTENCE_PROB_055 : 229|14@0+ (0.0001,0) [0|1] "NA"  ADAS
 SG_ OBJ_YAW_ANGLE_055 : 155|12@0+ (0.005,-10) [-10|10.475] "rad"  ADAS
 SG_ OBJ_YAW_ANGLE_ERR_055 : 175|7@0+ (0.01,0) [0|1.27] "rad"  ADAS
 SG_ OBJ_ID_055 : 7|8@0+ (1,0) [0|255] "NA"  ADAS
 SG_ OBJ_MOVEMENT_STATUS_055 : 196|3@0+ (1,0) [0|3] "NA"  ADAS
 SG_ OBJ_MEASUREMENT_STATUS_055 : 14|3@0+ (1,0) [0|7] "NA"  ADAS
 SG_ OBJ_POS_LONG_055 : 63|16@0+ (0.01,-327) [-327|327] "m"  ADAS
 SG_ OBJ_POS_LAT_055 : 79|16@0+ (0.01,-327) [-327|327] "m"  ADAS
 SG_ OBJ_VELOCITY_LONG_055 : 110|15@0+ (0.01,-163) [-163|163] "m/s"  ADAS
 SG_ OBJ_VELOCITY_LAT_055 : 126|15@0+ (0.01,-163) [-163|163] "m/s"  ADAS
 SG_ OBJ_ACCELERATION_LONG_055 : 193|10@0+ (0.05,-20) [-20|20] "m/s^2"  ADAS
 SG_ OBJ_ACCELERATION_LAT_055 : 177|10@0+ (0.05,-20) [-20|20] "m/s^2"  ADAS
 SG_ OBJ_VEH_TRACK_FLAG_055 : 10|1@0+ (1,0) [0|1] "NA"  ADAS
 SG_ OBJ_MH_CYCLE_COUNTER_055 : 487|8@0+ (1,0) [0|255] "NA"  ADAS
 SG_ OBJ_MH_CRC16_055 : 495|16@0+ (1,0) [0|65535] "NA"  ADAS
 SG_ OBJ_TIMESTAMP_OFFSET_055 : 247|8@0+ (1,-127) [-127|128] "ms"  ADAS
 SG_ OBJ_DIMENSION_WIDTH_ERR_055 : 23|6@0+ (0.01,0) [0|0.63] "m"  ADAS
 SG_ OBJ_DIMENSION_LENGTH_ERR_055 : 41|10@0+ (0.01,0) [0|10.23] "m"  ADAS
 SG_ OBJ_CLS_TYPE1_055 : 271|4@0+ (1,0) [0|15] "NA"  ADAS
 SG_ OBJ_CLS_TYPE1_PROB_055 : 303|8@0+ (0.004,0) [0|1] "NA"  ADAS
 SG_ OBJ_CLS_TYPE2_055 : 267|4@0+ (1,0) [0|15] "NA"  ADAS
 SG_ OBJ_CLS_TYPE2_PROB_055 : 311|8@0+ (0.004,0) [0|1] "NA"  ADAS
 SG_ OBJ_CLS_TYPE3_055 : 279|4@0+ (1,0) [0|15] "NA"  ADAS
 SG_ OBJ_CLS_TYPE3_PROB_055 : 319|8@0+ (0.004,0) [0|1] "NA"  ADAS
 SG_ OBJ_CLS_TYPE4_055 : 275|4@0+ (1,0) [0|15] "NA"  ADAS
 SG_ OBJ_CLS_TYPE4_PROB_055 : 327|8@0+ (0.004,0) [0|1] "NA"  ADAS
 SG_ OBJ_CLS_TYPE5_055 : 287|4@0+ (1,0) [0|15] "NA"  ADAS
 SG_ OBJ_CLS_TYPE5_PROB_055 : 335|8@0+ (0.004,0) [0|1] "NA"  ADAS
 SG_ OBJ_CLS_TYPE6_055 : 282|4@0+ (1,0) [0|15] "NA"  ADAS
 SG_ OBJ_CLS_TYPE6_PROB_055 : 343|8@0+ (0.004,0) [0|1] "NA"  ADAS
 SG_ OBJ_RCS_055 : 351|7@0+ (1,-64) [-64|63] "dBsm"  ADAS
 SG_ OBJ_REF_PT_LONG_OFFSET_055 : 357|14@0+ (0.0001,0) [0|1] "NA"  ADAS
 SG_ OBJ_REF_PT_LAT_OFFSET_055 : 370|14@0+ (0.0001,0) [0|1] "NA"  ADAS
 SG_ OBJ_YAW_RATE_055 : 399|10@0+ (0.005,-2.24) [-2.24|2.24] "rad/s"  ADAS
 SG_ OBJ_YAW_RATE_ERR_055 : 388|5@0+ (0.025,0) [0|0.775] "rad/s"  ADAS
 SG_ OBJ_GROUP_ID_055 : 405|6@0+ (1,0) [0|63] "NA"  ADAS
 SG_ OBJ_POS_ERR_CRR_COEF_055 : 415|8@0+ (0.01,-1.2) [-1.2|1] "NA"  ADAS
 SG_ OBJ_VELOCITY_ERR_CRR_COEF_055 : 423|8@0+ (0.01,-1.2) [-1.2|1] "NA"  ADAS
 SG_ OBJ_ACCEL_ERR_CRR_COEF_055 : 431|8@0+ (0.01,-1.2) [-1.2|1] "NA"  ADAS

BO_ 1607 RDR_TRACKER_OBJ_056: 64 RDR05
 SG_ OBJ_ALIVE_TIME_056 : 255|16@0+ (1,0) [0|65535] "ms"  ADAS
 SG_ OBJ_ACCELERATION_LONG_ERR_056 : 215|8@0+ (0.025,0) [0|6.375] "m/s^2"  ADAS
 SG_ OBJ_ACCELERATION_LAT_ERR_056 : 223|8@0+ (0.025,0) [0|6.375] "m/s^2"  ADAS
 SG_ OBJ_VELOCITY_LONG_ERR_056 : 143|8@0+ (0.05,0) [0|12.75] "m/s"  ADAS
 SG_ OBJ_VELOCITY_LAT_ERR_056 : 151|8@0+ (0.05,0) [0|12.75] "m/s"  ADAS
 SG_ OBJ_POS_LONG_ERR_056 : 95|8@0+ (0.025,0) [0|6.375] "m"  ADAS
 SG_ OBJ_POS_LAT_ERR_056 : 103|8@0+ (0.025,0) [0|6.375] "m"  ADAS
 SG_ OBJ_TRACK_MOTION_MODEL_056 : 9|2@0+ (1,0) [0|3] "NA"  ADAS
 SG_ OBJ_DIMENSION_WIDTH_056 : 17|10@0+ (0.01,0) [0|10.23] "m"  ADAS
 SG_ OBJ_DIMENSION_LENGTH_056 : 37|12@0+ (0.01,0) [0|40.95] "m"  ADAS
 SG_ OBJ_EXISTENCE_PROB_056 : 229|14@0+ (0.0001,0) [0|1] "NA"  ADAS
 SG_ OBJ_YAW_ANGLE_056 : 155|12@0+ (0.005,-10) [-10|10.475] "rad"  ADAS
 SG_ OBJ_YAW_ANGLE_ERR_056 : 175|7@0+ (0.01,0) [0|1.27] "rad"  ADAS
 SG_ OBJ_ID_056 : 7|8@0+ (1,0) [0|255] "NA"  ADAS
 SG_ OBJ_MOVEMENT_STATUS_056 : 196|3@0+ (1,0) [0|3] "NA"  ADAS
 SG_ OBJ_MEASUREMENT_STATUS_056 : 14|3@0+ (1,0) [0|7] "NA"  ADAS
 SG_ OBJ_POS_LONG_056 : 63|16@0+ (0.01,-327) [-327|327] "m"  ADAS
 SG_ OBJ_POS_LAT_056 : 79|16@0+ (0.01,-327) [-327|327] "m"  ADAS
 SG_ OBJ_VELOCITY_LONG_056 : 110|15@0+ (0.01,-163) [-163|163] "m/s"  ADAS
 SG_ OBJ_VELOCITY_LAT_056 : 126|15@0+ (0.01,-163) [-163|163] "m/s"  ADAS
 SG_ OBJ_ACCELERATION_LONG_056 : 193|10@0+ (0.05,-20) [-20|20] "m/s^2"  ADAS
 SG_ OBJ_ACCELERATION_LAT_056 : 177|10@0+ (0.05,-20) [-20|20] "m/s^2"  ADAS
 SG_ OBJ_VEH_TRACK_FLAG_056 : 10|1@0+ (1,0) [0|1] "NA"  ADAS
 SG_ OBJ_MH_CYCLE_COUNTER_056 : 487|8@0+ (1,0) [0|255] "NA"  ADAS
 SG_ OBJ_MH_CRC16_056 : 495|16@0+ (1,0) [0|65535] "NA"  ADAS
 SG_ OBJ_TIMESTAMP_OFFSET_056 : 247|8@0+ (1,-127) [-127|128] "ms"  ADAS
 SG_ OBJ_DIMENSION_WIDTH_ERR_056 : 23|6@0+ (0.01,0) [0|0.63] "m"  ADAS
 SG_ OBJ_DIMENSION_LENGTH_ERR_056 : 41|10@0+ (0.01,0) [0|10.23] "m"  ADAS
 SG_ OBJ_CLS_TYPE1_056 : 271|4@0+ (1,0) [0|15] "NA"  ADAS
 SG_ OBJ_CLS_TYPE1_PROB_056 : 303|8@0+ (0.004,0) [0|1] "NA"  ADAS
 SG_ OBJ_CLS_TYPE2_056 : 267|4@0+ (1,0) [0|15] "NA"  ADAS
 SG_ OBJ_CLS_TYPE2_PROB_056 : 311|8@0+ (0.004,0) [0|1] "NA"  ADAS
 SG_ OBJ_CLS_TYPE3_056 : 279|4@0+ (1,0) [0|15] "NA"  ADAS
 SG_ OBJ_CLS_TYPE3_PROB_056 : 319|8@0+ (0.004,0) [0|1] "NA"  ADAS
 SG_ OBJ_CLS_TYPE4_056 : 275|4@0+ (1,0) [0|15] "NA"  ADAS
 SG_ OBJ_CLS_TYPE4_PROB_056 : 327|8@0+ (0.004,0) [0|1] "NA"  ADAS
 SG_ OBJ_CLS_TYPE5_056 : 287|4@0+ (1,0) [0|15] "NA"  ADAS
 SG_ OBJ_CLS_TYPE5_PROB_056 : 335|8@0+ (0.004,0) [0|1] "NA"  ADAS
 SG_ OBJ_CLS_TYPE6_056 : 282|4@0+ (1,0) [0|15] "NA"  ADAS
 SG_ OBJ_CLS_TYPE6_PROB_056 : 343|8@0+ (0.004,0) [0|1] "NA"  ADAS
 SG_ OBJ_RCS_056 : 351|7@0+ (1,-64) [-64|63] "dBsm"  ADAS
 SG_ OBJ_REF_PT_LONG_OFFSET_056 : 357|14@0+ (0.0001,0) [0|1] "NA"  ADAS
 SG_ OBJ_REF_PT_LAT_OFFSET_056 : 370|14@0+ (0.0001,0) [0|1] "NA"  ADAS
 SG_ OBJ_YAW_RATE_056 : 399|10@0+ (0.005,-2.24) [-2.24|2.24] "rad/s"  ADAS
 SG_ OBJ_YAW_RATE_ERR_056 : 388|5@0+ (0.025,0) [0|0.775] "rad/s"  ADAS
 SG_ OBJ_GROUP_ID_056 : 405|6@0+ (1,0) [0|63] "NA"  ADAS
 SG_ OBJ_POS_ERR_CRR_COEF_056 : 415|8@0+ (0.01,-1.2) [-1.2|1] "NA"  ADAS
 SG_ OBJ_VELOCITY_ERR_CRR_COEF_056 : 423|8@0+ (0.01,-1.2) [-1.2|1] "NA"  ADAS
 SG_ OBJ_ACCEL_ERR_CRR_COEF_056 : 431|8@0+ (0.01,-1.2) [-1.2|1] "NA"  ADAS

BO_ 1608 RDR_TRACKER_OBJ_057: 64 RDR05
 SG_ OBJ_ALIVE_TIME_057 : 255|16@0+ (1,0) [0|65535] "ms"  ADAS
 SG_ OBJ_ACCELERATION_LONG_ERR_057 : 215|8@0+ (0.025,0) [0|6.375] "m/s^2"  ADAS
 SG_ OBJ_ACCELERATION_LAT_ERR_057 : 223|8@0+ (0.025,0) [0|6.375] "m/s^2"  ADAS
 SG_ OBJ_VELOCITY_LONG_ERR_057 : 143|8@0+ (0.05,0) [0|12.75] "m/s"  ADAS
 SG_ OBJ_VELOCITY_LAT_ERR_057 : 151|8@0+ (0.05,0) [0|12.75] "m/s"  ADAS
 SG_ OBJ_POS_LONG_ERR_057 : 95|8@0+ (0.025,0) [0|6.375] "m"  ADAS
 SG_ OBJ_POS_LAT_ERR_057 : 103|8@0+ (0.025,0) [0|6.375] "m"  ADAS
 SG_ OBJ_TRACK_MOTION_MODEL_057 : 9|2@0+ (1,0) [0|3] "NA"  ADAS
 SG_ OBJ_DIMENSION_WIDTH_057 : 17|10@0+ (0.01,0) [0|10.23] "m"  ADAS
 SG_ OBJ_DIMENSION_LENGTH_057 : 37|12@0+ (0.01,0) [0|40.95] "m"  ADAS
 SG_ OBJ_EXISTENCE_PROB_057 : 229|14@0+ (0.0001,0) [0|1] "NA"  ADAS
 SG_ OBJ_YAW_ANGLE_057 : 155|12@0+ (0.005,-10) [-10|10.475] "rad"  ADAS
 SG_ OBJ_YAW_ANGLE_ERR_057 : 175|7@0+ (0.01,0) [0|1.27] "rad"  ADAS
 SG_ OBJ_ID_057 : 7|8@0+ (1,0) [0|255] "NA"  ADAS
 SG_ OBJ_MOVEMENT_STATUS_057 : 196|3@0+ (1,0) [0|3] "NA"  ADAS
 SG_ OBJ_MEASUREMENT_STATUS_057 : 14|3@0+ (1,0) [0|7] "NA"  ADAS
 SG_ OBJ_POS_LONG_057 : 63|16@0+ (0.01,-327) [-327|327] "m"  ADAS
 SG_ OBJ_POS_LAT_057 : 79|16@0+ (0.01,-327) [-327|327] "m"  ADAS
 SG_ OBJ_VELOCITY_LONG_057 : 110|15@0+ (0.01,-163) [-163|163] "m/s"  ADAS
 SG_ OBJ_VELOCITY_LAT_057 : 126|15@0+ (0.01,-163) [-163|163] "m/s"  ADAS
 SG_ OBJ_ACCELERATION_LONG_057 : 193|10@0+ (0.05,-20) [-20|20] "m/s^2"  ADAS
 SG_ OBJ_ACCELERATION_LAT_057 : 177|10@0+ (0.05,-20) [-20|20] "m/s^2"  ADAS
 SG_ OBJ_VEH_TRACK_FLAG_057 : 10|1@0+ (1,0) [0|1] "NA"  ADAS
 SG_ OBJ_MH_CYCLE_COUNTER_057 : 487|8@0+ (1,0) [0|255] "NA"  ADAS
 SG_ OBJ_MH_CRC16_057 : 495|16@0+ (1,0) [0|65535] "NA"  ADAS
 SG_ OBJ_TIMESTAMP_OFFSET_057 : 247|8@0+ (1,-127) [-127|128] "ms"  ADAS
 SG_ OBJ_DIMENSION_WIDTH_ERR_057 : 23|6@0+ (0.01,0) [0|0.63] "m"  ADAS
 SG_ OBJ_DIMENSION_LENGTH_ERR_057 : 41|10@0+ (0.01,0) [0|10.23] "m"  ADAS
 SG_ OBJ_CLS_TYPE1_057 : 271|4@0+ (1,0) [0|15] "NA"  ADAS
 SG_ OBJ_CLS_TYPE1_PROB_057 : 303|8@0+ (0.004,0) [0|1] "NA"  ADAS
 SG_ OBJ_CLS_TYPE2_057 : 267|4@0+ (1,0) [0|15] "NA"  ADAS
 SG_ OBJ_CLS_TYPE2_PROB_057 : 311|8@0+ (0.004,0) [0|1] "NA"  ADAS
 SG_ OBJ_CLS_TYPE3_057 : 279|4@0+ (1,0) [0|15] "NA"  ADAS
 SG_ OBJ_CLS_TYPE3_PROB_057 : 319|8@0+ (0.004,0) [0|1] "NA"  ADAS
 SG_ OBJ_CLS_TYPE4_057 : 275|4@0+ (1,0) [0|15] "NA"  ADAS
 SG_ OBJ_CLS_TYPE4_PROB_057 : 327|8@0+ (0.004,0) [0|1] "NA"  ADAS
 SG_ OBJ_CLS_TYPE5_057 : 287|4@0+ (1,0) [0|15] "NA"  ADAS
 SG_ OBJ_CLS_TYPE5_PROB_057 : 335|8@0+ (0.004,0) [0|1] "NA"  ADAS
 SG_ OBJ_CLS_TYPE6_057 : 282|4@0+ (1,0) [0|15] "NA"  ADAS
 SG_ OBJ_CLS_TYPE6_PROB_057 : 343|8@0+ (0.004,0) [0|1] "NA"  ADAS
 SG_ OBJ_RCS_057 : 351|7@0+ (1,-64) [-64|63] "dBsm"  ADAS
 SG_ OBJ_REF_PT_LONG_OFFSET_057 : 357|14@0+ (0.0001,0) [0|1] "NA"  ADAS
 SG_ OBJ_REF_PT_LAT_OFFSET_057 : 370|14@0+ (0.0001,0) [0|1] "NA"  ADAS
 SG_ OBJ_YAW_RATE_057 : 399|10@0+ (0.005,-2.24) [-2.24|2.24] "rad/s"  ADAS
 SG_ OBJ_YAW_RATE_ERR_057 : 388|5@0+ (0.025,0) [0|0.775] "rad/s"  ADAS
 SG_ OBJ_GROUP_ID_057 : 405|6@0+ (1,0) [0|63] "NA"  ADAS
 SG_ OBJ_POS_ERR_CRR_COEF_057 : 415|8@0+ (0.01,-1.2) [-1.2|1] "NA"  ADAS
 SG_ OBJ_VELOCITY_ERR_CRR_COEF_057 : 423|8@0+ (0.01,-1.2) [-1.2|1] "NA"  ADAS
 SG_ OBJ_ACCEL_ERR_CRR_COEF_057 : 431|8@0+ (0.01,-1.2) [-1.2|1] "NA"  ADAS

BO_ 1609 RDR_TRACKER_OBJ_058: 64 RDR05
 SG_ OBJ_ALIVE_TIME_058 : 255|16@0+ (1,0) [0|65535] "ms"  ADAS
 SG_ OBJ_ACCELERATION_LONG_ERR_058 : 215|8@0+ (0.025,0) [0|6.375] "m/s^2"  ADAS
 SG_ OBJ_ACCELERATION_LAT_ERR_058 : 223|8@0+ (0.025,0) [0|6.375] "m/s^2"  ADAS
 SG_ OBJ_VELOCITY_LONG_ERR_058 : 143|8@0+ (0.05,0) [0|12.75] "m/s"  ADAS
 SG_ OBJ_VELOCITY_LAT_ERR_058 : 151|8@0+ (0.05,0) [0|12.75] "m/s"  ADAS
 SG_ OBJ_POS_LONG_ERR_058 : 95|8@0+ (0.025,0) [0|6.375] "m"  ADAS
 SG_ OBJ_POS_LAT_ERR_058 : 103|8@0+ (0.025,0) [0|6.375] "m"  ADAS
 SG_ OBJ_TRACK_MOTION_MODEL_058 : 9|2@0+ (1,0) [0|3] "NA"  ADAS
 SG_ OBJ_DIMENSION_WIDTH_058 : 17|10@0+ (0.01,0) [0|10.23] "m"  ADAS
 SG_ OBJ_DIMENSION_LENGTH_058 : 37|12@0+ (0.01,0) [0|40.95] "m"  ADAS
 SG_ OBJ_EXISTENCE_PROB_058 : 229|14@0+ (0.0001,0) [0|1] "NA"  ADAS
 SG_ OBJ_YAW_ANGLE_058 : 155|12@0+ (0.005,-10) [-10|10.475] "rad"  ADAS
 SG_ OBJ_YAW_ANGLE_ERR_058 : 175|7@0+ (0.01,0) [0|1.27] "rad"  ADAS
 SG_ OBJ_ID_058 : 7|8@0+ (1,0) [0|255] "NA"  ADAS
 SG_ OBJ_MOVEMENT_STATUS_058 : 196|3@0+ (1,0) [0|3] "NA"  ADAS
 SG_ OBJ_MEASUREMENT_STATUS_058 : 14|3@0+ (1,0) [0|7] "NA"  ADAS
 SG_ OBJ_POS_LONG_058 : 63|16@0+ (0.01,-327) [-327|327] "m"  ADAS
 SG_ OBJ_POS_LAT_058 : 79|16@0+ (0.01,-327) [-327|327] "m"  ADAS
 SG_ OBJ_VELOCITY_LONG_058 : 110|15@0+ (0.01,-163) [-163|163] "m/s"  ADAS
 SG_ OBJ_VELOCITY_LAT_058 : 126|15@0+ (0.01,-163) [-163|163] "m/s"  ADAS
 SG_ OBJ_ACCELERATION_LONG_058 : 193|10@0+ (0.05,-20) [-20|20] "m/s^2"  ADAS
 SG_ OBJ_ACCELERATION_LAT_058 : 177|10@0+ (0.05,-20) [-20|20] "m/s^2"  ADAS
 SG_ OBJ_VEH_TRACK_FLAG_058 : 10|1@0+ (1,0) [0|1] "NA"  ADAS
 SG_ OBJ_MH_CYCLE_COUNTER_058 : 487|8@0+ (1,0) [0|255] "NA"  ADAS
 SG_ OBJ_MH_CRC16_058 : 495|16@0+ (1,0) [0|65535] "NA"  ADAS
 SG_ OBJ_TIMESTAMP_OFFSET_058 : 247|8@0+ (1,-127) [-127|128] "ms"  ADAS
 SG_ OBJ_DIMENSION_WIDTH_ERR_058 : 23|6@0+ (0.01,0) [0|0.63] "m"  ADAS
 SG_ OBJ_DIMENSION_LENGTH_ERR_058 : 41|10@0+ (0.01,0) [0|10.23] "m"  ADAS
 SG_ OBJ_CLS_TYPE1_058 : 271|4@0+ (1,0) [0|15] "NA"  ADAS
 SG_ OBJ_CLS_TYPE1_PROB_058 : 303|8@0+ (0.004,0) [0|1] "NA"  ADAS
 SG_ OBJ_CLS_TYPE2_058 : 267|4@0+ (1,0) [0|15] "NA"  ADAS
 SG_ OBJ_CLS_TYPE2_PROB_058 : 311|8@0+ (0.004,0) [0|1] "NA"  ADAS
 SG_ OBJ_CLS_TYPE3_058 : 279|4@0+ (1,0) [0|15] "NA"  ADAS
 SG_ OBJ_CLS_TYPE3_PROB_058 : 319|8@0+ (0.004,0) [0|1] "NA"  ADAS
 SG_ OBJ_CLS_TYPE4_058 : 275|4@0+ (1,0) [0|15] "NA"  ADAS
 SG_ OBJ_CLS_TYPE4_PROB_058 : 327|8@0+ (0.004,0) [0|1] "NA"  ADAS
 SG_ OBJ_CLS_TYPE5_058 : 287|4@0+ (1,0) [0|15] "NA"  ADAS
 SG_ OBJ_CLS_TYPE5_PROB_058 : 335|8@0+ (0.004,0) [0|1] "NA"  ADAS
 SG_ OBJ_CLS_TYPE6_058 : 282|4@0+ (1,0) [0|15] "NA"  ADAS
 SG_ OBJ_CLS_TYPE6_PROB_058 : 343|8@0+ (0.004,0) [0|1] "NA"  ADAS
 SG_ OBJ_RCS_058 : 351|7@0+ (1,-64) [-64|63] "dBsm"  ADAS
 SG_ OBJ_REF_PT_LONG_OFFSET_058 : 357|14@0+ (0.0001,0) [0|1] "NA"  ADAS
 SG_ OBJ_REF_PT_LAT_OFFSET_058 : 370|14@0+ (0.0001,0) [0|1] "NA"  ADAS
 SG_ OBJ_YAW_RATE_058 : 399|10@0+ (0.005,-2.24) [-2.24|2.24] "rad/s"  ADAS
 SG_ OBJ_YAW_RATE_ERR_058 : 388|5@0+ (0.025,0) [0|0.775] "rad/s"  ADAS
 SG_ OBJ_GROUP_ID_058 : 405|6@0+ (1,0) [0|63] "NA"  ADAS
 SG_ OBJ_POS_ERR_CRR_COEF_058 : 415|8@0+ (0.01,-1.2) [-1.2|1] "NA"  ADAS
 SG_ OBJ_VELOCITY_ERR_CRR_COEF_058 : 423|8@0+ (0.01,-1.2) [-1.2|1] "NA"  ADAS
 SG_ OBJ_ACCEL_ERR_CRR_COEF_058 : 431|8@0+ (0.01,-1.2) [-1.2|1] "NA"  ADAS

BO_ 1610 RDR_TRACKER_OBJ_059: 64 RDR05
 SG_ OBJ_ALIVE_TIME_059 : 255|16@0+ (1,0) [0|65535] "ms"  ADAS
 SG_ OBJ_ACCELERATION_LONG_ERR_059 : 215|8@0+ (0.025,0) [0|6.375] "m/s^2"  ADAS
 SG_ OBJ_ACCELERATION_LAT_ERR_059 : 223|8@0+ (0.025,0) [0|6.375] "m/s^2"  ADAS
 SG_ OBJ_VELOCITY_LONG_ERR_059 : 143|8@0+ (0.05,0) [0|12.75] "m/s"  ADAS
 SG_ OBJ_VELOCITY_LAT_ERR_059 : 151|8@0+ (0.05,0) [0|12.75] "m/s"  ADAS
 SG_ OBJ_POS_LONG_ERR_059 : 95|8@0+ (0.025,0) [0|6.375] "m"  ADAS
 SG_ OBJ_POS_LAT_ERR_059 : 103|8@0+ (0.025,0) [0|6.375] "m"  ADAS
 SG_ OBJ_TRACK_MOTION_MODEL_059 : 9|2@0+ (1,0) [0|3] "NA"  ADAS
 SG_ OBJ_DIMENSION_WIDTH_059 : 17|10@0+ (0.01,0) [0|10.23] "m"  ADAS
 SG_ OBJ_DIMENSION_LENGTH_059 : 37|12@0+ (0.01,0) [0|40.95] "m"  ADAS
 SG_ OBJ_EXISTENCE_PROB_059 : 229|14@0+ (0.0001,0) [0|1] "NA"  ADAS
 SG_ OBJ_YAW_ANGLE_059 : 155|12@0+ (0.005,-10) [-10|10.475] "rad"  ADAS
 SG_ OBJ_YAW_ANGLE_ERR_059 : 175|7@0+ (0.01,0) [0|1.27] "rad"  ADAS
 SG_ OBJ_ID_059 : 7|8@0+ (1,0) [0|255] "NA"  ADAS
 SG_ OBJ_MOVEMENT_STATUS_059 : 196|3@0+ (1,0) [0|3] "NA"  ADAS
 SG_ OBJ_MEASUREMENT_STATUS_059 : 14|3@0+ (1,0) [0|7] "NA"  ADAS
 SG_ OBJ_POS_LONG_059 : 63|16@0+ (0.01,-327) [-327|327] "m"  ADAS
 SG_ OBJ_POS_LAT_059 : 79|16@0+ (0.01,-327) [-327|327] "m"  ADAS
 SG_ OBJ_VELOCITY_LONG_059 : 110|15@0+ (0.01,-163) [-163|163] "m/s"  ADAS
 SG_ OBJ_VELOCITY_LAT_059 : 126|15@0+ (0.01,-163) [-163|163] "m/s"  ADAS
 SG_ OBJ_ACCELERATION_LONG_059 : 193|10@0+ (0.05,-20) [-20|20] "m/s^2"  ADAS
 SG_ OBJ_ACCELERATION_LAT_059 : 177|10@0+ (0.05,-20) [-20|20] "m/s^2"  ADAS
 SG_ OBJ_VEH_TRACK_FLAG_059 : 10|1@0+ (1,0) [0|1] "NA"  ADAS
 SG_ OBJ_MH_CYCLE_COUNTER_059 : 487|8@0+ (1,0) [0|255] "NA"  ADAS
 SG_ OBJ_MH_CRC16_059 : 495|16@0+ (1,0) [0|65535] "NA"  ADAS
 SG_ OBJ_TIMESTAMP_OFFSET_059 : 247|8@0+ (1,-127) [-127|128] "ms"  ADAS
 SG_ OBJ_DIMENSION_WIDTH_ERR_059 : 23|6@0+ (0.01,0) [0|0.63] "m"  ADAS
 SG_ OBJ_DIMENSION_LENGTH_ERR_059 : 41|10@0+ (0.01,0) [0|10.23] "m"  ADAS
 SG_ OBJ_CLS_TYPE1_059 : 271|4@0+ (1,0) [0|15] "NA"  ADAS
 SG_ OBJ_CLS_TYPE1_PROB_059 : 303|8@0+ (0.004,0) [0|1] "NA"  ADAS
 SG_ OBJ_CLS_TYPE2_059 : 267|4@0+ (1,0) [0|15] "NA"  ADAS
 SG_ OBJ_CLS_TYPE2_PROB_059 : 311|8@0+ (0.004,0) [0|1] "NA"  ADAS
 SG_ OBJ_CLS_TYPE3_059 : 279|4@0+ (1,0) [0|15] "NA"  ADAS
 SG_ OBJ_CLS_TYPE3_PROB_059 : 319|8@0+ (0.004,0) [0|1] "NA"  ADAS
 SG_ OBJ_CLS_TYPE4_059 : 275|4@0+ (1,0) [0|15] "NA"  ADAS
 SG_ OBJ_CLS_TYPE4_PROB_059 : 327|8@0+ (0.004,0) [0|1] "NA"  ADAS
 SG_ OBJ_CLS_TYPE5_059 : 287|4@0+ (1,0) [0|15] "NA"  ADAS
 SG_ OBJ_CLS_TYPE5_PROB_059 : 335|8@0+ (0.004,0) [0|1] "NA"  ADAS
 SG_ OBJ_CLS_TYPE6_059 : 282|4@0+ (1,0) [0|15] "NA"  ADAS
 SG_ OBJ_CLS_TYPE6_PROB_059 : 343|8@0+ (0.004,0) [0|1] "NA"  ADAS
 SG_ OBJ_RCS_059 : 351|7@0+ (1,-64) [-64|63] "dBsm"  ADAS
 SG_ OBJ_REF_PT_LONG_OFFSET_059 : 357|14@0+ (0.0001,0) [0|1] "NA"  ADAS
 SG_ OBJ_REF_PT_LAT_OFFSET_059 : 370|14@0+ (0.0001,0) [0|1] "NA"  ADAS
 SG_ OBJ_YAW_RATE_059 : 399|10@0+ (0.005,-2.24) [-2.24|2.24] "rad/s"  ADAS
 SG_ OBJ_YAW_RATE_ERR_059 : 388|5@0+ (0.025,0) [0|0.775] "rad/s"  ADAS
 SG_ OBJ_GROUP_ID_059 : 405|6@0+ (1,0) [0|63] "NA"  ADAS
 SG_ OBJ_POS_ERR_CRR_COEF_059 : 415|8@0+ (0.01,-1.2) [-1.2|1] "NA"  ADAS
 SG_ OBJ_VELOCITY_ERR_CRR_COEF_059 : 423|8@0+ (0.01,-1.2) [-1.2|1] "NA"  ADAS
 SG_ OBJ_ACCEL_ERR_CRR_COEF_059 : 431|8@0+ (0.01,-1.2) [-1.2|1] "NA"  ADAS

BO_ 1611 RDR_TRACKER_OBJ_060: 64 RDR05
 SG_ OBJ_ALIVE_TIME_060 : 255|16@0+ (1,0) [0|65535] "ms"  ADAS
 SG_ OBJ_ACCELERATION_LONG_ERR_060 : 215|8@0+ (0.025,0) [0|6.375] "m/s^2"  ADAS
 SG_ OBJ_ACCELERATION_LAT_ERR_060 : 223|8@0+ (0.025,0) [0|6.375] "m/s^2"  ADAS
 SG_ OBJ_VELOCITY_LONG_ERR_060 : 143|8@0+ (0.05,0) [0|12.75] "m/s"  ADAS
 SG_ OBJ_VELOCITY_LAT_ERR_060 : 151|8@0+ (0.05,0) [0|12.75] "m/s"  ADAS
 SG_ OBJ_POS_LONG_ERR_060 : 95|8@0+ (0.025,0) [0|6.375] "m"  ADAS
 SG_ OBJ_POS_LAT_ERR_060 : 103|8@0+ (0.025,0) [0|6.375] "m"  ADAS
 SG_ OBJ_TRACK_MOTION_MODEL_060 : 9|2@0+ (1,0) [0|3] "NA"  ADAS
 SG_ OBJ_DIMENSION_WIDTH_060 : 17|10@0+ (0.01,0) [0|10.23] "m"  ADAS
 SG_ OBJ_DIMENSION_LENGTH_060 : 37|12@0+ (0.01,0) [0|40.95] "m"  ADAS
 SG_ OBJ_EXISTENCE_PROB_060 : 229|14@0+ (0.0001,0) [0|1] "NA"  ADAS
 SG_ OBJ_YAW_ANGLE_060 : 155|12@0+ (0.005,-10) [-10|10.475] "rad"  ADAS
 SG_ OBJ_YAW_ANGLE_ERR_060 : 175|7@0+ (0.01,0) [0|1.27] "rad"  ADAS
 SG_ OBJ_ID_060 : 7|8@0+ (1,0) [0|255] "NA"  ADAS
 SG_ OBJ_MOVEMENT_STATUS_060 : 196|3@0+ (1,0) [0|3] "NA"  ADAS
 SG_ OBJ_MEASUREMENT_STATUS_060 : 14|3@0+ (1,0) [0|7] "NA"  ADAS
 SG_ OBJ_POS_LONG_060 : 63|16@0+ (0.01,-327) [-327|327] "m"  ADAS
 SG_ OBJ_POS_LAT_060 : 79|16@0+ (0.01,-327) [-327|327] "m"  ADAS
 SG_ OBJ_VELOCITY_LONG_060 : 110|15@0+ (0.01,-163) [-163|163] "m/s"  ADAS
 SG_ OBJ_VELOCITY_LAT_060 : 126|15@0+ (0.01,-163) [-163|163] "m/s"  ADAS
 SG_ OBJ_ACCELERATION_LONG_060 : 193|10@0+ (0.05,-20) [-20|20] "m/s^2"  ADAS
 SG_ OBJ_ACCELERATION_LAT_060 : 177|10@0+ (0.05,-20) [-20|20] "m/s^2"  ADAS
 SG_ OBJ_VEH_TRACK_FLAG_060 : 10|1@0+ (1,0) [0|1] "NA"  ADAS
 SG_ OBJ_MH_CYCLE_COUNTER_060 : 487|8@0+ (1,0) [0|255] "NA"  ADAS
 SG_ OBJ_MH_CRC16_060 : 495|16@0+ (1,0) [0|65535] "NA"  ADAS
 SG_ OBJ_TIMESTAMP_OFFSET_060 : 247|8@0+ (1,-127) [-127|128] "ms"  ADAS
 SG_ OBJ_DIMENSION_WIDTH_ERR_060 : 23|6@0+ (0.01,0) [0|0.63] "m"  ADAS
 SG_ OBJ_DIMENSION_LENGTH_ERR_060 : 41|10@0+ (0.01,0) [0|10.23] "m"  ADAS
 SG_ OBJ_CLS_TYPE1_060 : 271|4@0+ (1,0) [0|15] "NA"  ADAS
 SG_ OBJ_CLS_TYPE1_PROB_060 : 303|8@0+ (0.004,0) [0|1] "NA"  ADAS
 SG_ OBJ_CLS_TYPE2_060 : 267|4@0+ (1,0) [0|15] "NA"  ADAS
 SG_ OBJ_CLS_TYPE2_PROB_060 : 311|8@0+ (0.004,0) [0|1] "NA"  ADAS
 SG_ OBJ_CLS_TYPE3_060 : 279|4@0+ (1,0) [0|15] "NA"  ADAS
 SG_ OBJ_CLS_TYPE3_PROB_060 : 319|8@0+ (0.004,0) [0|1] "NA"  ADAS
 SG_ OBJ_CLS_TYPE4_060 : 275|4@0+ (1,0) [0|15] "NA"  ADAS
 SG_ OBJ_CLS_TYPE4_PROB_060 : 327|8@0+ (0.004,0) [0|1] "NA"  ADAS
 SG_ OBJ_CLS_TYPE5_060 : 287|4@0+ (1,0) [0|15] "NA"  ADAS
 SG_ OBJ_CLS_TYPE5_PROB_060 : 335|8@0+ (0.004,0) [0|1] "NA"  ADAS
 SG_ OBJ_CLS_TYPE6_060 : 282|4@0+ (1,0) [0|15] "NA"  ADAS
 SG_ OBJ_CLS_TYPE6_PROB_060 : 343|8@0+ (0.004,0) [0|1] "NA"  ADAS
 SG_ OBJ_RCS_060 : 351|7@0+ (1,-64) [-64|63] "dBsm"  ADAS
 SG_ OBJ_REF_PT_LONG_OFFSET_060 : 357|14@0+ (0.0001,0) [0|1] "NA"  ADAS
 SG_ OBJ_REF_PT_LAT_OFFSET_060 : 370|14@0+ (0.0001,0) [0|1] "NA"  ADAS
 SG_ OBJ_YAW_RATE_060 : 399|10@0+ (0.005,-2.24) [-2.24|2.24] "rad/s"  ADAS
 SG_ OBJ_YAW_RATE_ERR_060 : 388|5@0+ (0.025,0) [0|0.775] "rad/s"  ADAS
 SG_ OBJ_GROUP_ID_060 : 405|6@0+ (1,0) [0|63] "NA"  ADAS
 SG_ OBJ_POS_ERR_CRR_COEF_060 : 415|8@0+ (0.01,-1.2) [-1.2|1] "NA"  ADAS
 SG_ OBJ_VELOCITY_ERR_CRR_COEF_060 : 423|8@0+ (0.01,-1.2) [-1.2|1] "NA"  ADAS
 SG_ OBJ_ACCEL_ERR_CRR_COEF_060 : 431|8@0+ (0.01,-1.2) [-1.2|1] "NA"  ADAS

BO_ 1612 RDR_TRACKER_OBJ_061: 64 RDR05
 SG_ OBJ_ALIVE_TIME_061 : 255|16@0+ (1,0) [0|65535] "ms"  ADAS
 SG_ OBJ_ACCELERATION_LONG_ERR_061 : 215|8@0+ (0.025,0) [0|6.375] "m/s^2"  ADAS
 SG_ OBJ_ACCELERATION_LAT_ERR_061 : 223|8@0+ (0.025,0) [0|6.375] "m/s^2"  ADAS
 SG_ OBJ_VELOCITY_LONG_ERR_061 : 143|8@0+ (0.05,0) [0|12.75] "m/s"  ADAS
 SG_ OBJ_VELOCITY_LAT_ERR_061 : 151|8@0+ (0.05,0) [0|12.75] "m/s"  ADAS
 SG_ OBJ_POS_LONG_ERR_061 : 95|8@0+ (0.025,0) [0|6.375] "m"  ADAS
 SG_ OBJ_POS_LAT_ERR_061 : 103|8@0+ (0.025,0) [0|6.375] "m"  ADAS
 SG_ OBJ_TRACK_MOTION_MODEL_061 : 9|2@0+ (1,0) [0|3] "NA"  ADAS
 SG_ OBJ_DIMENSION_WIDTH_061 : 17|10@0+ (0.01,0) [0|10.23] "m"  ADAS
 SG_ OBJ_DIMENSION_LENGTH_061 : 37|12@0+ (0.01,0) [0|40.95] "m"  ADAS
 SG_ OBJ_EXISTENCE_PROB_061 : 229|14@0+ (0.0001,0) [0|1] "NA"  ADAS
 SG_ OBJ_YAW_ANGLE_061 : 155|12@0+ (0.005,-10) [-10|10.475] "rad"  ADAS
 SG_ OBJ_YAW_ANGLE_ERR_061 : 175|7@0+ (0.01,0) [0|1.27] "rad"  ADAS
 SG_ OBJ_ID_061 : 7|8@0+ (1,0) [0|255] "NA"  ADAS
 SG_ OBJ_MOVEMENT_STATUS_061 : 196|3@0+ (1,0) [0|3] "NA"  ADAS
 SG_ OBJ_MEASUREMENT_STATUS_061 : 14|3@0+ (1,0) [0|7] "NA"  ADAS
 SG_ OBJ_POS_LONG_061 : 63|16@0+ (0.01,-327) [-327|327] "m"  ADAS
 SG_ OBJ_POS_LAT_061 : 79|16@0+ (0.01,-327) [-327|327] "m"  ADAS
 SG_ OBJ_VELOCITY_LONG_061 : 110|15@0+ (0.01,-163) [-163|163] "m/s"  ADAS
 SG_ OBJ_VELOCITY_LAT_061 : 126|15@0+ (0.01,-163) [-163|163] "m/s"  ADAS
 SG_ OBJ_ACCELERATION_LONG_061 : 193|10@0+ (0.05,-20) [-20|20] "m/s^2"  ADAS
 SG_ OBJ_ACCELERATION_LAT_061 : 177|10@0+ (0.05,-20) [-20|20] "m/s^2"  ADAS
 SG_ OBJ_VEH_TRACK_FLAG_061 : 10|1@0+ (1,0) [0|1] "NA"  ADAS
 SG_ OBJ_MH_CYCLE_COUNTER_061 : 487|8@0+ (1,0) [0|255] "NA"  ADAS
 SG_ OBJ_MH_CRC16_061 : 495|16@0+ (1,0) [0|65535] "NA"  ADAS
 SG_ OBJ_TIMESTAMP_OFFSET_061 : 247|8@0+ (1,-127) [-127|128] "ms"  ADAS
 SG_ OBJ_DIMENSION_WIDTH_ERR_061 : 23|6@0+ (0.01,0) [0|0.63] "m"  ADAS
 SG_ OBJ_DIMENSION_LENGTH_ERR_061 : 41|10@0+ (0.01,0) [0|10.23] "m"  ADAS
 SG_ OBJ_CLS_TYPE1_061 : 271|4@0+ (1,0) [0|15] "NA"  ADAS
 SG_ OBJ_CLS_TYPE1_PROB_061 : 303|8@0+ (0.004,0) [0|1] "NA"  ADAS
 SG_ OBJ_CLS_TYPE2_061 : 267|4@0+ (1,0) [0|15] "NA"  ADAS
 SG_ OBJ_CLS_TYPE2_PROB_061 : 311|8@0+ (0.004,0) [0|1] "NA"  ADAS
 SG_ OBJ_CLS_TYPE3_061 : 279|4@0+ (1,0) [0|15] "NA"  ADAS
 SG_ OBJ_CLS_TYPE3_PROB_061 : 319|8@0+ (0.004,0) [0|1] "NA"  ADAS
 SG_ OBJ_CLS_TYPE4_061 : 275|4@0+ (1,0) [0|15] "NA"  ADAS
 SG_ OBJ_CLS_TYPE4_PROB_061 : 327|8@0+ (0.004,0) [0|1] "NA"  ADAS
 SG_ OBJ_CLS_TYPE5_061 : 287|4@0+ (1,0) [0|15] "NA"  ADAS
 SG_ OBJ_CLS_TYPE5_PROB_061 : 335|8@0+ (0.004,0) [0|1] "NA"  ADAS
 SG_ OBJ_CLS_TYPE6_061 : 282|4@0+ (1,0) [0|15] "NA"  ADAS
 SG_ OBJ_CLS_TYPE6_PROB_061 : 343|8@0+ (0.004,0) [0|1] "NA"  ADAS
 SG_ OBJ_RCS_061 : 351|7@0+ (1,-64) [-64|63] "dBsm"  ADAS
 SG_ OBJ_REF_PT_LONG_OFFSET_061 : 357|14@0+ (0.0001,0) [0|1] "NA"  ADAS
 SG_ OBJ_REF_PT_LAT_OFFSET_061 : 370|14@0+ (0.0001,0) [0|1] "NA"  ADAS
 SG_ OBJ_YAW_RATE_061 : 399|10@0+ (0.005,-2.24) [-2.24|2.24] "rad/s"  ADAS
 SG_ OBJ_YAW_RATE_ERR_061 : 388|5@0+ (0.025,0) [0|0.775] "rad/s"  ADAS
 SG_ OBJ_GROUP_ID_061 : 405|6@0+ (1,0) [0|63] "NA"  ADAS
 SG_ OBJ_POS_ERR_CRR_COEF_061 : 415|8@0+ (0.01,-1.2) [-1.2|1] "NA"  ADAS
 SG_ OBJ_VELOCITY_ERR_CRR_COEF_061 : 423|8@0+ (0.01,-1.2) [-1.2|1] "NA"  ADAS
 SG_ OBJ_ACCEL_ERR_CRR_COEF_061 : 431|8@0+ (0.01,-1.2) [-1.2|1] "NA"  ADAS

BO_ 1613 RDR_TRACKER_OBJ_062: 64 RDR05
 SG_ OBJ_ALIVE_TIME_062 : 255|16@0+ (1,0) [0|65535] "ms"  ADAS
 SG_ OBJ_ACCELERATION_LONG_ERR_062 : 215|8@0+ (0.025,0) [0|6.375] "m/s^2"  ADAS
 SG_ OBJ_ACCELERATION_LAT_ERR_062 : 223|8@0+ (0.025,0) [0|6.375] "m/s^2"  ADAS
 SG_ OBJ_VELOCITY_LONG_ERR_062 : 143|8@0+ (0.05,0) [0|12.75] "m/s"  ADAS
 SG_ OBJ_VELOCITY_LAT_ERR_062 : 151|8@0+ (0.05,0) [0|12.75] "m/s"  ADAS
 SG_ OBJ_POS_LONG_ERR_062 : 95|8@0+ (0.025,0) [0|6.375] "m"  ADAS
 SG_ OBJ_POS_LAT_ERR_062 : 103|8@0+ (0.025,0) [0|6.375] "m"  ADAS
 SG_ OBJ_TRACK_MOTION_MODEL_062 : 9|2@0+ (1,0) [0|3] "NA"  ADAS
 SG_ OBJ_DIMENSION_WIDTH_062 : 17|10@0+ (0.01,0) [0|10.23] "m"  ADAS
 SG_ OBJ_DIMENSION_LENGTH_062 : 37|12@0+ (0.01,0) [0|40.95] "m"  ADAS
 SG_ OBJ_EXISTENCE_PROB_062 : 229|14@0+ (0.0001,0) [0|1] "NA"  ADAS
 SG_ OBJ_YAW_ANGLE_062 : 155|12@0+ (0.005,-10) [-10|10.475] "rad"  ADAS
 SG_ OBJ_YAW_ANGLE_ERR_062 : 175|7@0+ (0.01,0) [0|1.27] "rad"  ADAS
 SG_ OBJ_ID_062 : 7|8@0+ (1,0) [0|255] "NA"  ADAS
 SG_ OBJ_MOVEMENT_STATUS_062 : 196|3@0+ (1,0) [0|3] "NA"  ADAS
 SG_ OBJ_MEASUREMENT_STATUS_062 : 14|3@0+ (1,0) [0|7] "NA"  ADAS
 SG_ OBJ_POS_LONG_062 : 63|16@0+ (0.01,-327) [-327|327] "m"  ADAS
 SG_ OBJ_POS_LAT_062 : 79|16@0+ (0.01,-327) [-327|327] "m"  ADAS
 SG_ OBJ_VELOCITY_LONG_062 : 110|15@0+ (0.01,-163) [-163|163] "m/s"  ADAS
 SG_ OBJ_VELOCITY_LAT_062 : 126|15@0+ (0.01,-163) [-163|163] "m/s"  ADAS
 SG_ OBJ_ACCELERATION_LONG_062 : 193|10@0+ (0.05,-20) [-20|20] "m/s^2"  ADAS
 SG_ OBJ_ACCELERATION_LAT_062 : 177|10@0+ (0.05,-20) [-20|20] "m/s^2"  ADAS
 SG_ OBJ_VEH_TRACK_FLAG_062 : 10|1@0+ (1,0) [0|1] "NA"  ADAS
 SG_ OBJ_MH_CYCLE_COUNTER_062 : 487|8@0+ (1,0) [0|255] "NA"  ADAS
 SG_ OBJ_MH_CRC16_062 : 495|16@0+ (1,0) [0|65535] "NA"  ADAS
 SG_ OBJ_TIMESTAMP_OFFSET_062 : 247|8@0+ (1,-127) [-127|128] "ms"  ADAS
 SG_ OBJ_DIMENSION_WIDTH_ERR_062 : 23|6@0+ (0.01,0) [0|0.63] "m"  ADAS
 SG_ OBJ_DIMENSION_LENGTH_ERR_062 : 41|10@0+ (0.01,0) [0|10.23] "m"  ADAS
 SG_ OBJ_CLS_TYPE1_062 : 271|4@0+ (1,0) [0|15] "NA"  ADAS
 SG_ OBJ_CLS_TYPE1_PROB_062 : 303|8@0+ (0.004,0) [0|1] "NA"  ADAS
 SG_ OBJ_CLS_TYPE2_062 : 267|4@0+ (1,0) [0|15] "NA"  ADAS
 SG_ OBJ_CLS_TYPE2_PROB_062 : 311|8@0+ (0.004,0) [0|1] "NA"  ADAS
 SG_ OBJ_CLS_TYPE3_062 : 279|4@0+ (1,0) [0|15] "NA"  ADAS
 SG_ OBJ_CLS_TYPE3_PROB_062 : 319|8@0+ (0.004,0) [0|1] "NA"  ADAS
 SG_ OBJ_CLS_TYPE4_062 : 275|4@0+ (1,0) [0|15] "NA"  ADAS
 SG_ OBJ_CLS_TYPE4_PROB_062 : 327|8@0+ (0.004,0) [0|1] "NA"  ADAS
 SG_ OBJ_CLS_TYPE5_062 : 287|4@0+ (1,0) [0|15] "NA"  ADAS
 SG_ OBJ_CLS_TYPE5_PROB_062 : 335|8@0+ (0.004,0) [0|1] "NA"  ADAS
 SG_ OBJ_CLS_TYPE6_062 : 282|4@0+ (1,0) [0|15] "NA"  ADAS
 SG_ OBJ_CLS_TYPE6_PROB_062 : 343|8@0+ (0.004,0) [0|1] "NA"  ADAS
 SG_ OBJ_RCS_062 : 351|7@0+ (1,-64) [-64|63] "dBsm"  ADAS
 SG_ OBJ_REF_PT_LONG_OFFSET_062 : 357|14@0+ (0.0001,0) [0|1] "NA"  ADAS
 SG_ OBJ_REF_PT_LAT_OFFSET_062 : 370|14@0+ (0.0001,0) [0|1] "NA"  ADAS
 SG_ OBJ_YAW_RATE_062 : 399|10@0+ (0.005,-2.24) [-2.24|2.24] "rad/s"  ADAS
 SG_ OBJ_YAW_RATE_ERR_062 : 388|5@0+ (0.025,0) [0|0.775] "rad/s"  ADAS
 SG_ OBJ_GROUP_ID_062 : 405|6@0+ (1,0) [0|63] "NA"  ADAS
 SG_ OBJ_POS_ERR_CRR_COEF_062 : 415|8@0+ (0.01,-1.2) [-1.2|1] "NA"  ADAS
 SG_ OBJ_VELOCITY_ERR_CRR_COEF_062 : 423|8@0+ (0.01,-1.2) [-1.2|1] "NA"  ADAS
 SG_ OBJ_ACCEL_ERR_CRR_COEF_062 : 431|8@0+ (0.01,-1.2) [-1.2|1] "NA"  ADAS

BO_ 1614 RDR_TRACKER_OBJ_063: 64 RDR05
 SG_ OBJ_ALIVE_TIME_063 : 255|16@0+ (1,0) [0|65535] "ms"  ADAS
 SG_ OBJ_ACCELERATION_LONG_ERR_063 : 215|8@0+ (0.025,0) [0|6.375] "m/s^2"  ADAS
 SG_ OBJ_ACCELERATION_LAT_ERR_063 : 223|8@0+ (0.025,0) [0|6.375] "m/s^2"  ADAS
 SG_ OBJ_VELOCITY_LONG_ERR_063 : 143|8@0+ (0.05,0) [0|12.75] "m/s"  ADAS
 SG_ OBJ_VELOCITY_LAT_ERR_063 : 151|8@0+ (0.05,0) [0|12.75] "m/s"  ADAS
 SG_ OBJ_POS_LONG_ERR_063 : 95|8@0+ (0.025,0) [0|6.375] "m"  ADAS
 SG_ OBJ_POS_LAT_ERR_063 : 103|8@0+ (0.025,0) [0|6.375] "m"  ADAS
 SG_ OBJ_TRACK_MOTION_MODEL_063 : 9|2@0+ (1,0) [0|3] "NA"  ADAS
 SG_ OBJ_DIMENSION_WIDTH_063 : 17|10@0+ (0.01,0) [0|10.23] "m"  ADAS
 SG_ OBJ_DIMENSION_LENGTH_063 : 37|12@0+ (0.01,0) [0|40.95] "m"  ADAS
 SG_ OBJ_EXISTENCE_PROB_063 : 229|14@0+ (0.0001,0) [0|1] "NA"  ADAS
 SG_ OBJ_YAW_ANGLE_063 : 155|12@0+ (0.005,-10) [-10|10.475] "rad"  ADAS
 SG_ OBJ_YAW_ANGLE_ERR_063 : 175|7@0+ (0.01,0) [0|1.27] "rad"  ADAS
 SG_ OBJ_ID_063 : 7|8@0+ (1,0) [0|255] "NA"  ADAS
 SG_ OBJ_MOVEMENT_STATUS_063 : 196|3@0+ (1,0) [0|3] "NA"  ADAS
 SG_ OBJ_MEASUREMENT_STATUS_063 : 14|3@0+ (1,0) [0|7] "NA"  ADAS
 SG_ OBJ_POS_LONG_063 : 63|16@0+ (0.01,-327) [-327|327] "m"  ADAS
 SG_ OBJ_POS_LAT_063 : 79|16@0+ (0.01,-327) [-327|327] "m"  ADAS
 SG_ OBJ_VELOCITY_LONG_063 : 110|15@0+ (0.01,-163) [-163|163] "m/s"  ADAS
 SG_ OBJ_VELOCITY_LAT_063 : 126|15@0+ (0.01,-163) [-163|163] "m/s"  ADAS
 SG_ OBJ_ACCELERATION_LONG_063 : 193|10@0+ (0.05,-20) [-20|20] "m/s^2"  ADAS
 SG_ OBJ_ACCELERATION_LAT_063 : 177|10@0+ (0.05,-20) [-20|20] "m/s^2"  ADAS
 SG_ OBJ_VEH_TRACK_FLAG_063 : 10|1@0+ (1,0) [0|1] "NA"  ADAS
 SG_ OBJ_MH_CYCLE_COUNTER_063 : 487|8@0+ (1,0) [0|255] "NA"  ADAS
 SG_ OBJ_MH_CRC16_063 : 495|16@0+ (1,0) [0|65535] "NA"  ADAS
 SG_ OBJ_TIMESTAMP_OFFSET_063 : 247|8@0+ (1,-127) [-127|128] "ms"  ADAS
 SG_ OBJ_DIMENSION_WIDTH_ERR_063 : 23|6@0+ (0.01,0) [0|0.63] "m"  ADAS
 SG_ OBJ_DIMENSION_LENGTH_ERR_063 : 41|10@0+ (0.01,0) [0|10.23] "m"  ADAS
 SG_ OBJ_CLS_TYPE1_063 : 271|4@0+ (1,0) [0|15] "NA"  ADAS
 SG_ OBJ_CLS_TYPE1_PROB_063 : 303|8@0+ (0.004,0) [0|1] "NA"  ADAS
 SG_ OBJ_CLS_TYPE2_063 : 267|4@0+ (1,0) [0|15] "NA"  ADAS
 SG_ OBJ_CLS_TYPE2_PROB_063 : 311|8@0+ (0.004,0) [0|1] "NA"  ADAS
 SG_ OBJ_CLS_TYPE3_063 : 279|4@0+ (1,0) [0|15] "NA"  ADAS
 SG_ OBJ_CLS_TYPE3_PROB_063 : 319|8@0+ (0.004,0) [0|1] "NA"  ADAS
 SG_ OBJ_CLS_TYPE4_063 : 275|4@0+ (1,0) [0|15] "NA"  ADAS
 SG_ OBJ_CLS_TYPE4_PROB_063 : 327|8@0+ (0.004,0) [0|1] "NA"  ADAS
 SG_ OBJ_CLS_TYPE5_063 : 287|4@0+ (1,0) [0|15] "NA"  ADAS
 SG_ OBJ_CLS_TYPE5_PROB_063 : 335|8@0+ (0.004,0) [0|1] "NA"  ADAS
 SG_ OBJ_CLS_TYPE6_063 : 282|4@0+ (1,0) [0|15] "NA"  ADAS
 SG_ OBJ_CLS_TYPE6_PROB_063 : 343|8@0+ (0.004,0) [0|1] "NA"  ADAS
 SG_ OBJ_RCS_063 : 351|7@0+ (1,-64) [-64|63] "dBsm"  ADAS
 SG_ OBJ_REF_PT_LONG_OFFSET_063 : 357|14@0+ (0.0001,0) [0|1] "NA"  ADAS
 SG_ OBJ_REF_PT_LAT_OFFSET_063 : 370|14@0+ (0.0001,0) [0|1] "NA"  ADAS
 SG_ OBJ_YAW_RATE_063 : 399|10@0+ (0.005,-2.24) [-2.24|2.24] "rad/s"  ADAS
 SG_ OBJ_YAW_RATE_ERR_063 : 388|5@0+ (0.025,0) [0|0.775] "rad/s"  ADAS
 SG_ OBJ_GROUP_ID_063 : 405|6@0+ (1,0) [0|63] "NA"  ADAS
 SG_ OBJ_POS_ERR_CRR_COEF_063 : 415|8@0+ (0.01,-1.2) [-1.2|1] "NA"  ADAS
 SG_ OBJ_VELOCITY_ERR_CRR_COEF_063 : 423|8@0+ (0.01,-1.2) [-1.2|1] "NA"  ADAS
 SG_ OBJ_ACCEL_ERR_CRR_COEF_063 : 431|8@0+ (0.01,-1.2) [-1.2|1] "NA"  ADAS

BO_ 1615 RDR_TRACKER_OBJ_064: 64 RDR05
 SG_ OBJ_ALIVE_TIME_064 : 255|16@0+ (1,0) [0|65535] "ms"  ADAS
 SG_ OBJ_ACCELERATION_LONG_ERR_064 : 215|8@0+ (0.025,0) [0|6.375] "m/s^2"  ADAS
 SG_ OBJ_ACCELERATION_LAT_ERR_064 : 223|8@0+ (0.025,0) [0|6.375] "m/s^2"  ADAS
 SG_ OBJ_VELOCITY_LONG_ERR_064 : 143|8@0+ (0.05,0) [0|12.75] "m/s"  ADAS
 SG_ OBJ_VELOCITY_LAT_ERR_064 : 151|8@0+ (0.05,0) [0|12.75] "m/s"  ADAS
 SG_ OBJ_POS_LONG_ERR_064 : 95|8@0+ (0.025,0) [0|6.375] "m"  ADAS
 SG_ OBJ_POS_LAT_ERR_064 : 103|8@0+ (0.025,0) [0|6.375] "m"  ADAS
 SG_ OBJ_TRACK_MOTION_MODEL_064 : 9|2@0+ (1,0) [0|3] "NA"  ADAS
 SG_ OBJ_DIMENSION_WIDTH_064 : 17|10@0+ (0.01,0) [0|10.23] "m"  ADAS
 SG_ OBJ_DIMENSION_LENGTH_064 : 37|12@0+ (0.01,0) [0|40.95] "m"  ADAS
 SG_ OBJ_EXISTENCE_PROB_064 : 229|14@0+ (0.0001,0) [0|1] "NA"  ADAS
 SG_ OBJ_YAW_ANGLE_064 : 155|12@0+ (0.005,-10) [-10|10.475] "rad"  ADAS
 SG_ OBJ_YAW_ANGLE_ERR_064 : 175|7@0+ (0.01,0) [0|1.27] "rad"  ADAS
 SG_ OBJ_ID_064 : 7|8@0+ (1,0) [0|255] "NA"  ADAS
 SG_ OBJ_MOVEMENT_STATUS_064 : 196|3@0+ (1,0) [0|3] "NA"  ADAS
 SG_ OBJ_MEASUREMENT_STATUS_064 : 14|3@0+ (1,0) [0|7] "NA"  ADAS
 SG_ OBJ_POS_LONG_064 : 63|16@0+ (0.01,-327) [-327|327] "m"  ADAS
 SG_ OBJ_POS_LAT_064 : 79|16@0+ (0.01,-327) [-327|327] "m"  ADAS
 SG_ OBJ_VELOCITY_LONG_064 : 110|15@0+ (0.01,-163) [-163|163] "m/s"  ADAS
 SG_ OBJ_VELOCITY_LAT_064 : 126|15@0+ (0.01,-163) [-163|163] "m/s"  ADAS
 SG_ OBJ_ACCELERATION_LONG_064 : 193|10@0+ (0.05,-20) [-20|20] "m/s^2"  ADAS
 SG_ OBJ_ACCELERATION_LAT_064 : 177|10@0+ (0.05,-20) [-20|20] "m/s^2"  ADAS
 SG_ OBJ_VEH_TRACK_FLAG_064 : 10|1@0+ (1,0) [0|1] "NA"  ADAS
 SG_ OBJ_MH_CYCLE_COUNTER_064 : 487|8@0+ (1,0) [0|255] "NA"  ADAS
 SG_ OBJ_MH_CRC16_064 : 495|16@0+ (1,0) [0|65535] "NA"  ADAS
 SG_ OBJ_TIMESTAMP_OFFSET_064 : 247|8@0+ (1,-127) [-127|128] "ms"  ADAS
 SG_ OBJ_DIMENSION_WIDTH_ERR_064 : 23|6@0+ (0.01,0) [0|0.63] "m"  ADAS
 SG_ OBJ_DIMENSION_LENGTH_ERR_064 : 41|10@0+ (0.01,0) [0|10.23] "m"  ADAS
 SG_ OBJ_CLS_TYPE1_064 : 271|4@0+ (1,0) [0|15] "NA"  ADAS
 SG_ OBJ_CLS_TYPE1_PROB_064 : 303|8@0+ (0.004,0) [0|1] "NA"  ADAS
 SG_ OBJ_CLS_TYPE2_064 : 267|4@0+ (1,0) [0|15] "NA"  ADAS
 SG_ OBJ_CLS_TYPE2_PROB_064 : 311|8@0+ (0.004,0) [0|1] "NA"  ADAS
 SG_ OBJ_CLS_TYPE3_064 : 279|4@0+ (1,0) [0|15] "NA"  ADAS
 SG_ OBJ_CLS_TYPE3_PROB_064 : 319|8@0+ (0.004,0) [0|1] "NA"  ADAS
 SG_ OBJ_CLS_TYPE4_064 : 275|4@0+ (1,0) [0|15] "NA"  ADAS
 SG_ OBJ_CLS_TYPE4_PROB_064 : 327|8@0+ (0.004,0) [0|1] "NA"  ADAS
 SG_ OBJ_CLS_TYPE5_064 : 287|4@0+ (1,0) [0|15] "NA"  ADAS
 SG_ OBJ_CLS_TYPE5_PROB_064 : 335|8@0+ (0.004,0) [0|1] "NA"  ADAS
 SG_ OBJ_CLS_TYPE6_064 : 282|4@0+ (1,0) [0|15] "NA"  ADAS
 SG_ OBJ_CLS_TYPE6_PROB_064 : 343|8@0+ (0.004,0) [0|1] "NA"  ADAS
 SG_ OBJ_RCS_064 : 351|7@0+ (1,-64) [-64|63] "dBsm"  ADAS
 SG_ OBJ_REF_PT_LONG_OFFSET_064 : 357|14@0+ (0.0001,0) [0|1] "NA"  ADAS
 SG_ OBJ_REF_PT_LAT_OFFSET_064 : 370|14@0+ (0.0001,0) [0|1] "NA"  ADAS
 SG_ OBJ_YAW_RATE_064 : 399|10@0+ (0.005,-2.24) [-2.24|2.24] "rad/s"  ADAS
 SG_ OBJ_YAW_RATE_ERR_064 : 388|5@0+ (0.025,0) [0|0.775] "rad/s"  ADAS
 SG_ OBJ_GROUP_ID_064 : 405|6@0+ (1,0) [0|63] "NA"  ADAS
 SG_ OBJ_POS_ERR_CRR_COEF_064 : 415|8@0+ (0.01,-1.2) [-1.2|1] "NA"  ADAS
 SG_ OBJ_VELOCITY_ERR_CRR_COEF_064 : 423|8@0+ (0.01,-1.2) [-1.2|1] "NA"  ADAS
 SG_ OBJ_ACCEL_ERR_CRR_COEF_064 : 431|8@0+ (0.01,-1.2) [-1.2|1] "NA"  ADAS

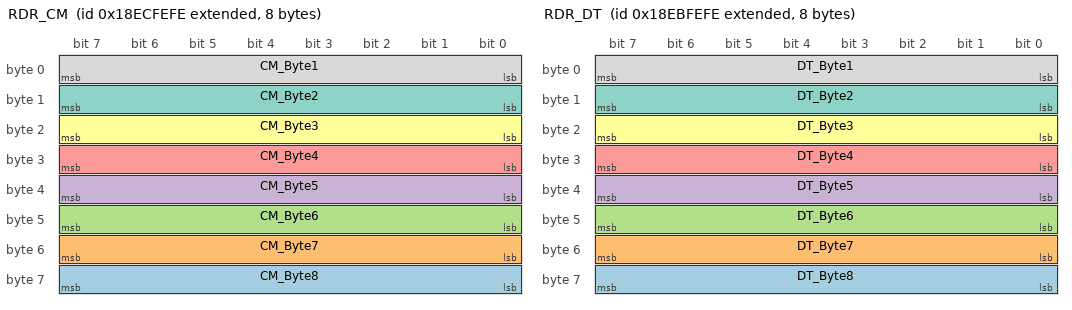
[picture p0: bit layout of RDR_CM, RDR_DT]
BO_ 2565668606 RDR_CM: 8 Vector__XXX
 SG_ CM_Byte8 : 56|8@1+ (1,0) [0|255] "" Vector__XXX
 SG_ CM_Byte7 : 48|8@1+ (1,0) [0|255] "" Vector__XXX
 SG_ CM_Byte6 : 40|8@1+ (1,0) [0|255] "" Vector__XXX
 SG_ CM_Byte5 : 32|8@1+ (1,0) [0|255] "" Vector__XXX
 SG_ CM_Byte4 : 24|8@1+ (1,0) [0|255] "" Vector__XXX
 SG_ CM_Byte3 : 16|8@1+ (1,0) [0|255] "" Vector__XXX
 SG_ CM_Byte2 : 8|8@1+ (1,0) [0|255] "" Vector__XXX
 SG_ CM_Byte1 : 0|8@1+ (1,0) [0|255] "" Vector__XXX

BO_ 2565603070 RDR_DT: 8 Vector__XXX
 SG_ DT_Byte8 : 56|8@1+ (1,0) [0|255] "" Vector__XXX
 SG_ DT_Byte7 : 48|8@1+ (1,0) [0|255] "" Vector__XXX
 SG_ DT_Byte6 : 40|8@1+ (1,0) [0|255] "" Vector__XXX
 SG_ DT_Byte5 : 32|8@1+ (1,0) [0|255] "" Vector__XXX
 SG_ DT_Byte4 : 24|8@1+ (1,0) [0|255] "" Vector__XXX
 SG_ DT_Byte3 : 16|8@1+ (1,0) [0|255] "" Vector__XXX
 SG_ DT_Byte2 : 8|8@1+ (1,0) [0|255] "" Vector__XXX
 SG_ DT_Byte1 : 0|8@1+ (1,0) [0|255] "" Vector__XXX

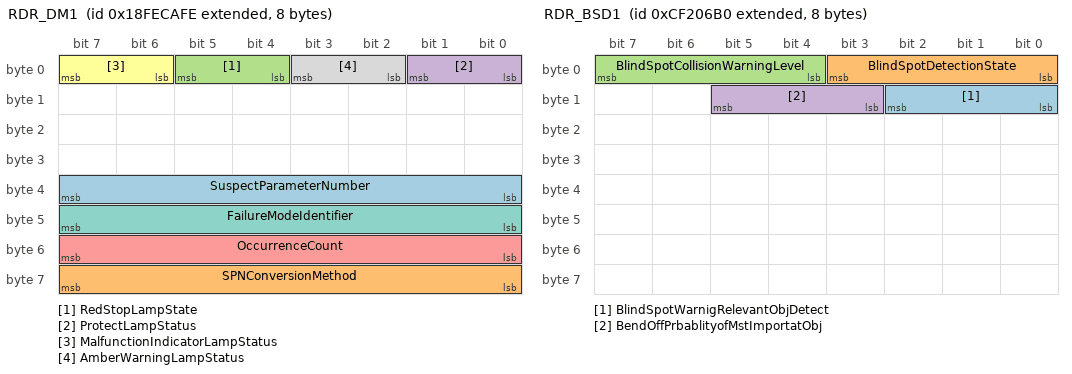
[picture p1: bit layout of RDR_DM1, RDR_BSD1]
BO_ 2566834942 RDR_DM1: 8 Vector__XXX
 SG_ SuspectParameterNumber : 32|8@1+ (1,0) [-128|127] "" Vector__XXX
 SG_ SPNConversionMethod : 56|8@1+ (1,0) [0|255] "" Vector__XXX
 SG_ RedStopLampState : 4|2@1+ (1,0) [0|3] "" Vector__XXX
 SG_ ProtectLampStatus : 0|2@1+ (1,0) [0|3] "" Vector__XXX
 SG_ OccurrenceCount : 48|8@1+ (1,0) [0|0] "" Vector__XXX
 SG_ MalfunctionIndicatorLampStatus : 6|2@1+ (1,0) [0|3] "" Vector__XXX
 SG_ FailureModeIdentifier : 40|8@1+ (1,0) [0|255] "" Vector__XXX
 SG_ AmberWarningLampStatus : 2|2@1+ (1,0) [0|3] "" Vector__XXX

BO_ 2564486577 RDR_DIAG_RESP_PHYS_PLANT: 64 Vector__XXX
 SG_ Diag_Resp_Phys : 7|64@0+ (1,0) [0|0] ""  External_Tool

BO_ 2564486321 RDR_DIAG_RESP_PHYS_OTA: 64 Vector__XXX
 SG_ Diag_Resp_Phys : 7|64@0+ (1,0) [0|0] ""  External_Tool

BO_ 2564485553 RDR_DIAG_RESP_PHYS_OBD: 64 Vector__XXX
 SG_ Diag_Resp_Phys : 7|64@0+ (1,0) [0|0] ""  External_Tool

BO_ 2364671664 RDR_BSD1: 8 Vector__XXX
 SG_ BlindSpotWarnigRelevantObjDetect : 8|3@1+ (1,0) [0|7] ""  RDR05
 SG_ BlindSpotDetectionState : 0|4@1+ (1,0) [0|15] ""  RDR05
 SG_ BlindSpotCollisionWarningLevel : 4|4@1+ (1,0) [0|15] ""  RDR05
 SG_ BendOffPrbablityofMstImportatObj : 11|3@1+ (1,0) [0|7] ""  RDR05

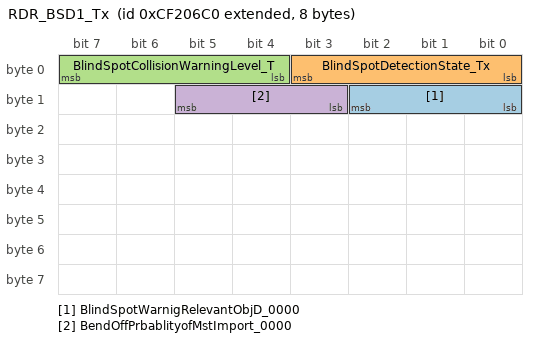
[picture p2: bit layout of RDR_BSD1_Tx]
BO_ 2364671680 RDR_BSD1_Tx: 8 RDR05
 SG_ BlindSpotWarnigRelevantObjD_0000 : 8|3@1+ (1,0) [0|7] ""  RDR_Gateway
 SG_ BlindSpotDetectionState_Tx : 0|4@1+ (1,0) [0|15] ""  RDR_Gateway
 SG_ BlindSpotCollisionWarningLevel_T : 4|4@1+ (1,0) [0|15] ""  RDR_Gateway
 SG_ BendOffPrbablityofMstImport_0000 : 11|3@1+ (1,0) [0|7] ""  RDR_Gateway

BO_ 161 RDR_OBJ_HEADER_002: 64 RDR05
 SG_ HED_TRKR_VEHICLE_IDX : 23|16@0+ (1,0) [0|65535] ""  ADAS
 SG_ HED_MH_002_CYCLE_COUNTER : 159|8@0+ (1,0) [0|255] ""  ADAS
 SG_ HED_MH_002_CRC16 : 143|16@0+ (1,0) [0|65535] ""  ADAS
 SG_ HED_TRKR_IDX : 7|16@0+ (1,0) [0|65535] ""  ADAS
 SG_ HED_TRKR_TIME_PEAK : 71|8@0+ (0.5,0) [0|127.5] "ms"  ADAS
 SG_ HED_TRKR_TIME_INST : 63|8@0+ (0.5,0) [0|127.5] "ms"  ADAS
 SG_ HED_TRKR_OBJLST_TIME_STAMP_NS : 111|32@0+ (1,0) [0|4294967295] "ns"  ADAS
 SG_ HED_TRKR_OBJLST_TIME_STAMP_SC : 79|32@0+ (1,0) [0|4294967295] "s"  ADAS
 SG_ HED_TRKR_VEH_COORD_TYPE : 32|1@0+ (1,0) [0|1] ""  ADAS
 SG_ HED_TRKR_NUM_OF_ACTIV_OBJS : 55|8@0+ (1,0) [0|255] ""  ADAS
 SG_ HED_TRKR_DATA_QUALIFIER : 42|3@0+ (1,0) [0|7] ""  ADAS

BO_ 162 RDR_OBJ_STATUS_003: 64 RDR05
 SG_ STS_TRKR_PATCH_VERSION : 23|8@0+ (1,0) [0|255] ""  ADAS
 SG_ STS_TRKR_MINOR_VERSION : 15|8@0+ (1,0) [0|255] ""  ADAS
 SG_ STS_TRKR_MAJOR_VERSION : 7|8@0+ (1,0) [0|255] ""  ADAS
 SG_ STS_PERCEPTION_MODULE_ID : 31|16@0+ (1,0) [0|65535] ""  ADAS
 SG_ STS_OBJ_DBC_BASE_VER_MINOR : 79|8@0+ (1,0) [0|255] ""  ADAS
 SG_ STS_OBJ_DBC_BASE_VER_MAJOR : 71|8@0+ (1,0) [0|255] ""  ADAS
 SG_ STS_MH_003_CRC16 : 87|16@0+ (1,0) [0|65535] ""  ADAS
 SG_ STS_MH_003_CYCLE_COUNTER : 103|8@0+ (1,0) [0|255] ""  ADAS

BO_ 128 RDR_FUSION_HEADER_001: 64 RDR_Fusion_Partner
 SG_ HED_RDR_HEADER_CMAC_Rx : 472|40@1+ (1,0) [0|1099511627800] ""  RDR05
 SG_ HED_RDR_HEADER_FV_Rx : 416|56@1+ (1,0) [0|7.2057594038E+16] ""  RDR05
 SG_ HED_Rain_Level_Rx : 318|2@1+ (1,0) [0|2] ""  RDR05
 SG_ HED_V_WRAPPING_Rx : 197|11@1+ (0.01,-40) [-40|-19.53] "mps"  RDR05
 SG_ HED_R_WRAPPING_Rx : 368|8@1+ (0.01,-0.9) [-0.9|1.65] "m"  RDR05
 SG_ HED_Auth_CRC32_Rx : 376|32@1+ (1,0) [0|4294967295] ""  RDR05
 SG_ HED_SLOPE_CORR_EXECUTIONFLAG_Rx : 172|2@1+ (1,0) [0|3] ""  RDR05
 SG_ HED_PROCESSED_RANGE_Rx : 160|9@1+ (1,0) [0|500] ""  RDR05
 SG_ HED_LOOK_INDEX_Rx : 208|16@1+ (1,0) [0|65535] ""  RDR05
 SG_ HED_OPERATION_MODE_Rx : 315|3@1+ (1,0) [0|5] ""  RDR05
 SG_ HED_MAX_NUM_OF_DETECTIONS_Rx : 352|9@1+ (1,0) [0|400] ""  RDR05
 SG_ HED_NUM_OF_RESTBINS_USED_Rx : 24|9@1+ (1,0) [0|511] ""  RDR05
 SG_ HED_NUM_OF_VALID_DETECTIONS_Rx : 33|9@1+ (1,0) [0|500] ""  RDR05
 SG_ HED_LOOK_ID_Rx : 42|2@1+ (1,0) [0|3] ""  RDR05
 SG_ HED_SCAN_INDEX_Rx : 48|16@1+ (1,0) [0|65535] ""  RDR05
 SG_ HED_MH_CYCLE_COUNTER_Rx : 16|8@1+ (1,0) [0|255] ""  RDR05
 SG_ HED_DATA_QUALIFIER_Rx : 44|3@1+ (1,0) [0|7] ""  RDR05
 SG_ HED_DET_RANGE_MAX_Rx : 64|16@1+ (0.01,0) [0|500] "m"  RDR05
 SG_ HED_DET_SPEED_RANGE_MAX_Rx : 96|16@1+ (0.00390625,-128) [-128|127.99609375] "m/s"  RDR05
 SG_ HED_FOV_HOR_MAX_Rx : 136|8@1+ (0.0174533,0) [0|3.14159] "rad"  RDR05
 SG_ HED_FOV_VER_MAX_Rx : 152|8@1+ (0.0174533,0) [0|3.14159] "rad"  RDR05
 SG_ HED_DET_RANGE_MIN_Rx : 80|16@1+ (0.01,0) [0|500] "m"  RDR05
 SG_ HED_DET_SPEED_RANGE_MIN_Rx : 112|16@1+ (0.00390625,-128) [-128|127.99609375] "m/s"  RDR05
 SG_ HED_FOV_HOR_MIN_Rx : 128|8@1- (0.0174533,0) [-2.2340224|2.2165691] "rad"  RDR05
 SG_ HED_FOV_VER_MIN_Rx : 144|8@1- (0.0174533,0) [-2.2340224|2.2165691] "rad"  RDR05
 SG_ HED_ALIGN_VER_REF_Rx : 174|10@1+ (0.0005,-0.1745) [-0.1745|0.337] "rad"  RDR05
 SG_ HED_ALIGN_HOR_REF_Rx : 184|13@1+ (0.0005,-0.1745) [-0.1745|3.921] "rad"  RDR05
 SG_ HED_SENSOR_TIME_STAMP_NS_Rx : 224|32@1+ (1,0) [0|4294967295] "ns"  RDR05
 SG_ HED_SENSOR_TIME_STAMP_SEC_Rx : 256|32@1+ (1,0) [0|4294967295] "s"  RDR05
 SG_ HED_TIME_SYNC_SRC_MASTER_Rx : 169|1@1+ (1,0) [0|1] ""  RDR05
 SG_ HED_TIME_SYNC_VALIDITY_FLAG_Rx : 170|2@1+ (1,0) [0|2] ""  RDR05
 SG_ HED_MH_CRC16_Rx : 0|16@1+ (1,0) [0|65535] ""  RDR05
 SG_ HED_DET_NUM_OF_1PASS_Rx : 296|10@1+ (1,0) [0|1023] ""  RDR05
 SG_ HED_DET_NUM_OF_2PASS_Rx : 306|9@1+ (1,0) [0|511] ""  RDR05
 SG_ HED_TRIGGER_TIME_Rx : 320|32@1+ (1,0) [0|4294967295] "ns"  RDR05
 SG_ HED_DET_BI_STATIC_COUNT_Rx : 288|8@1+ (1,0) [0|255] ""  RDR05

BO_ 131 RDR_FUSION_STATUS_001: 64 RDR_Fusion_Partner
 SG_ STS_VIN_Status_Rx : 118|2@1+ (1,0) [0|3] ""  RDR05
 SG_ STS_DIST_FRNT_BMPR_TO_RR_AXL_Rx : 248|13@1+ (0.001,0) [0|8.191] "m"  RDR05
 SG_ STS_SENSOR_POLARITY_Rx : 246|1@1+ (1,0) [0|1] ""  RDR05
 SG_ STS_SP_CORE_TIME_PEAK_Rx : 472|8@1+ (0.5,0) [0|127.5] "ms"  RDR05
 SG_ STS_SP_CORE_TIME_INST_Rx : 480|8@1+ (0.5,0) [0|127.5] "ms"  RDR05
 SG_ STS_RDD_CORE_TIME_PEAK_Rx : 464|8@1+ (0.5,0) [0|127.5] "ms"  RDR05
 SG_ STS_RDD_CORE_TIME_INST_Rx : 456|8@1+ (0.5,0) [0|127.5] "ms"  RDR05
 SG_ STS_MAIN_CORE_TIME_PEAK_Rx : 448|8@1+ (0.5,0) [0|127.5] "ms"  RDR05
 SG_ STS_MAIN_CORE_TIME_INST_Rx : 440|8@1+ (0.5,0) [0|127.5] "ms"  RDR05
 SG_ STS_AF_TIME_PEAK_Rx : 432|8@1+ (0.5,0) [0|127.5] "ms"  RDR05
 SG_ STS_AF_TIME_INST_Rx : 424|8@1+ (0.5,0) [0|127.5] "ms"  RDR05
 SG_ STS_PCAN_PROTOCOL_VER_MINOR_Rx : 128|8@1+ (1,0) [0|255] ""  RDR05
 SG_ STS_PCAN_PROTOCOL_VER_MAJOR_Rx : 120|8@1+ (1,0) [0|255] ""  RDR05
 SG_ STS_PLATFORM_VARIANT_Rx : 162|5@1+ (1,0) [0|16] ""  RDR05
 SG_ STS_HARDWARE_VERSION_Rx : 112|3@1+ (1,0) [0|5] ""  RDR05
 SG_ STS_SERIAL_NUMBER_SEQUENCE_Rx : 148|14@1+ (1,0) [0|9999] ""  RDR05
 SG_ STS_SERIAL_NUM_JULIAN_YEAR_Rx : 145|3@1+ (1,2020) [2020|2027] "years"  RDR05
 SG_ STS_SERIAL_NUM_JULIAN_DAY_Rx : 136|9@1+ (1,0) [0|366] ""  RDR05
 SG_ STS_SW_VERSION_FIELD1_Rx : 168|8@1+ (1,0) [0|255] ""  RDR05
 SG_ STS_SW_VERSION_FIELD2_Rx : 176|8@1+ (1,0) [0|255] ""  RDR05
 SG_ STS_SW_VERSION_FIELD3_Rx : 184|8@1+ (1,0) [0|255] ""  RDR05
 SG_ STS_SW_VERSION_FIELD4_Rx : 192|8@1+ (1,0) [0|255] ""  RDR05
 SG_ STS_PBL_VERSION_FIELD1_Rx : 200|8@1+ (1,0) [0|255] ""  RDR05
 SG_ STS_PBL_VERSION_FIELD2_Rx : 208|8@1+ (1,0) [0|255] ""  RDR05
 SG_ STS_PBL_VERSION_FIELD3_Rx : 216|8@1+ (1,0) [0|255] ""  RDR05
 SG_ STS_PBL_VERSION_FIELD4_Rx : 224|8@1+ (1,0) [0|255] ""  RDR05
 SG_ STS_USC_CAL_VER_MAJOR_Rx : 24|16@1+ (1,0) [0|65535] ""  RDR05
 SG_ STS_USC_CAL_VER_MINOR_Rx : 40|16@1+ (1,0) [0|65535] ""  RDR05
 SG_ STS_USC_SECTION_COMPTBLITY_Rx : 56|16@1+ (1,0) [0|255] ""  RDR05
 SG_ STS_SMC_CAL_VER_MAJOR_Rx : 72|16@1+ (1,0) [0|65535] ""  RDR05
 SG_ STS_SMC_CAL_VER_MINOR_Rx : 88|16@1+ (1,0) [0|65535] ""  RDR05
 SG_ STS_SMC_SECTION_COMPTBLITY_Rx : 488|16@1+ (1,0) [0|65535] ""  RDR05
 SG_ STS_SMC_PLATFROM_VERSION_Rx : 104|8@1+ (1,0) [0|12] ""  RDR05
 SG_ STS_SENSOR_MOUNT_POS_X_Rx : 296|14@1- (0.001,0) [-8.192|8.191] "m"  RDR05
 SG_ STS_SENSOR_MOUNT_POS_Y_Rx : 312|16@1- (0.0001,0) [-3.2768|3.2767] "m"  RDR05
 SG_ STS_SENSOR_MOUNT_POS_Z_Rx : 328|16@1- (0.0001,0) [-3.2768|3.2767] "m"  RDR05
 SG_ STS_SENSOR_MOUNT_ORNT_YAW_Rx : 232|14@1- (0.0004,0) [-3.14|3.14] "rad"  RDR05
 SG_ STS_SENSOR_MOUNT_ORNT_PITCH_Rx : 264|14@1- (0.0004,0) [-3.14|3.14] "rad"  RDR05
 SG_ STS_SENSOR_MOUNT_ORNT_ROLL_Rx : 280|14@1- (0.0004,0) [-3.14159|3.14159] "rad"  RDR05
 SG_ STS_SENSOR_HEIGHT_Rx : 344|32@1+ (0.01,0) [0|42949672.95] "m"  RDR05
 SG_ STS_DET_DBC_BASE_VER_MINOR_Rx : 384|8@1+ (1,0) [0|255] ""  RDR05
 SG_ STS_DET_DBC_BASE_VER_MAJOR_Rx : 376|8@1+ (1,0) [0|255] ""  RDR05
 SG_ STS_TIME_SINCE_POWER_ON_Rx : 392|32@1+ (1,0) [0|4294967295] "s"  RDR05
 SG_ STS_SENSOR_POSITION_Rx : 115|3@1+ (1,0) [0|7] ""  RDR05
 SG_ STS_MH_001_CRC16_Rx : 0|16@1+ (1,0) [0|65535] ""  RDR05
 SG_ STS_MH_001_CYCLE_COUNTER_Rx : 16|8@1+ (1,0) [0|255] ""  RDR05

BO_ 256 RDR_FUSION_DET_001_004: 64 RDR_Fusion_Partner
 SG_ DET_RANGE_001_Rx : 24|15@1+ (0.015625,0) [0|500] "m"  RDR05
 SG_ DET_RANGE_ERR_001_Rx : 40|7@1+ (0.0075,0) [0|0.9525] "m"  RDR05
 SG_ DET_RANGE_VELOCITY_001_Rx : 48|15@1+ (0.0078125,-128) [-128|127.9921875] "m/s"  RDR05
 SG_ DET_RANGE_VELOCITY_ERR_001_Rx : 64|8@1+ (0.003,0) [0|0.765] "m/s"  RDR05
 SG_ DET_AZIMUTH_001_Rx : 88|13@1+ (0.0004,-1.5708) [-1.5708|1.5708] "rad"  RDR05
 SG_ DET_AZIMUTH_ERR_001_Rx : 105|7@1+ (0.00087267,0) [0|0.11082909] "rad"  RDR05
 SG_ DET_ELEVATION_001_Rx : 72|8@1+ (0.00275,-0.34925) [-0.34925|0.34925] "rad"  RDR05
 SG_ DET_ELEVATION_ERR_001_Rx : 80|6@1+ (0.00174533,0) [0|0.10995579] "rad"  RDR05
 SG_ DET_RCS_001_Rx : 128|8@1+ (0.5,-64) [-64|63.5] "dBsm"  RDR05
 SG_ DET_BI_STATIC_FLAG_001_Rx : 104|1@1+ (1,0) [0|1] ""  RDR05
 SG_ DET_SUPER_RES_TARGET_001_Rx : 87|1@1+ (1,0) [0|1] ""  RDR05
 SG_ DET_SNR_001_Rx : 120|8@1+ (0.35156,0) [0|89.6478] "dB"  RDR05
 SG_ DET_EXISTENCE_PROB_001_Rx : 112|6@1+ (1.588,0) [0|100] "%"  RDR05
 SG_ DET_HVC_FLAG_001_Rx : 86|1@1+ (1,0) [0|1] ""  RDR05
 SG_ DET_CONFD_AZIMUTH_001_Rx : 118|2@1+ (1,0) [0|3] ""  RDR05
 SG_ DET_CONFD_ELEVATION_001_Rx : 101|2@1+ (1,0) [0|3] ""  RDR05
 SG_ DET_PROB_1STAZHYPO_001_Rx : 103|1@1+ (1,0) [0|1] ""  RDR05
 SG_ DET_IDM_001_Rx : 63|1@1+ (1,0) [0|1] ""  RDR05
 SG_ DET_MTD_001_Rx : 47|1@1+ (1,0) [0|1] ""  RDR05
 SG_ DET_BELOW_RAIN_THOLD_001_Rx : 39|1@1+ (1,0) [0|1] ""  RDR05
 SG_ DET_RANGE_002_Rx : 136|15@1+ (0.015625,0) [0|500] "m"  RDR05
 SG_ DET_RANGE_ERR_002_Rx : 152|7@1+ (0.0075,0) [0|0.9525] "m"  RDR05
 SG_ DET_RANGE_VELOCITY_002_Rx : 160|15@1+ (0.0078125,-128) [-128|127.9921875] "m/s"  RDR05
 SG_ DET_RANGE_VELOCITY_ERR_002_Rx : 176|8@1+ (0.003,0) [0|0.765] "m/s"  RDR05
 SG_ DET_AZIMUTH_002_Rx : 200|13@1+ (0.0004,-1.5708) [-1.5708|1.5708] "rad"  RDR05
 SG_ DET_AZIMUTH_ERR_002_Rx : 217|7@1+ (0.00087267,0) [0|0.11082909] "rad"  RDR05
 SG_ DET_ELEVATION_002_Rx : 184|8@1+ (0.00275,-0.34925) [-0.34925|0.34925] "rad"  RDR05
 SG_ DET_ELEVATION_ERR_002_Rx : 192|6@1+ (0.00174533,0) [0|0.10995579] "rad"  RDR05
 SG_ DET_RCS_002_Rx : 240|8@1+ (0.5,-64) [-64|63.5] "dBsm"  RDR05
 SG_ DET_BI_STATIC_FLAG_002_Rx : 216|1@1+ (1,0) [0|1] ""  RDR05
 SG_ DET_SUPER_RES_TARGET_002_Rx : 199|1@1+ (1,0) [0|1] ""  RDR05
 SG_ DET_SNR_002_Rx : 232|8@1+ (0.35156,0) [0|89.6478] "dB"  RDR05
 SG_ DET_EXISTENCE_PROB_002_Rx : 224|6@1+ (1.588,0) [0|100] "%"  RDR05
 SG_ DET_HVC_FLAG_002_Rx : 198|1@1+ (1,0) [0|1] ""  RDR05
 SG_ DET_CONFD_AZIMUTH_002_Rx : 230|2@1+ (1,0) [0|3] ""  RDR05
 SG_ DET_CONFD_ELEVATION_002_Rx : 213|2@1+ (1,0) [0|3] ""  RDR05
 SG_ DET_PROB_1STAZHYPO_002_Rx : 215|1@1+ (1,0) [0|1] ""  RDR05
 SG_ DET_IDM_002_Rx : 175|1@1+ (1,0) [0|1] ""  RDR05
 SG_ DET_MTD_002_Rx : 159|1@1+ (1,0) [0|1] ""  RDR05
 SG_ DET_BELOW_RAIN_THOLD_002_Rx : 151|1@1+ (1,0) [0|1] ""  RDR05
 SG_ DET_RANGE_003_Rx : 248|15@1+ (0.015625,0) [0|500] "m"  RDR05
 SG_ DET_RANGE_ERR_003_Rx : 264|7@1+ (0.0075,0) [0|0.9525] "m"  RDR05
 SG_ DET_RANGE_VELOCITY_003_Rx : 272|15@1+ (0.0078125,-128) [-128|127.9921875] "m/s"  RDR05
 SG_ DET_RANGE_VELOCITY_ERR_003_Rx : 288|8@1+ (0.003,0) [0|0.765] "m/s"  RDR05
 SG_ DET_AZIMUTH_003_Rx : 312|13@1+ (0.0004,-1.5708) [-1.5708|1.5708] "rad"  RDR05
 SG_ DET_AZIMUTH_ERR_003_Rx : 329|7@1+ (0.00087267,0) [0|0.11082909] "rad"  RDR05
 SG_ DET_ELEVATION_003_Rx : 296|8@1+ (0.00275,-0.34925) [-0.34925|0.34925] "rad"  RDR05
 SG_ DET_ELEVATION_ERR_003_Rx : 304|6@1+ (0.00174533,0) [0|0.10995579] "rad"  RDR05
 SG_ DET_RCS_003_Rx : 352|8@1+ (0.5,-64) [-64|63.5] "dBsm"  RDR05
 SG_ DET_BI_STATIC_FLAG_003_Rx : 328|1@1+ (1,0) [0|1] ""  RDR05
 SG_ DET_SUPER_RES_TARGET_003_Rx : 311|1@1+ (1,0) [0|1] ""  RDR05
 SG_ DET_SNR_003_Rx : 344|8@1+ (0.35156,0) [0|89.6478] "dB"  RDR05
 SG_ DET_EXISTENCE_PROB_003_Rx : 336|6@1+ (1.588,0) [0|100] "%"  RDR05
 SG_ DET_HVC_FLAG_003_Rx : 310|1@1+ (1,0) [0|1] ""  RDR05
 SG_ DET_CONFD_AZIMUTH_003_Rx : 342|2@1+ (1,0) [0|3] ""  RDR05
 SG_ DET_CONFD_ELEVATION_003_Rx : 325|2@1+ (1,0) [0|3] ""  RDR05
 SG_ DET_PROB_1STAZHYPO_003_Rx : 327|1@1+ (1,0) [0|1] ""  RDR05
 SG_ DET_IDM_003_Rx : 287|1@1+ (1,0) [0|1] ""  RDR05
 SG_ DET_MTD_003_Rx : 271|1@1+ (1,0) [0|1] ""  RDR05
 SG_ DET_BELOW_RAIN_THOLD_003_Rx : 263|1@1+ (1,0) [0|1] ""  RDR05
 SG_ DET_RANGE_004_Rx : 360|15@1+ (0.015625,0) [0|500] "m"  RDR05
 SG_ DET_RANGE_ERR_004_Rx : 376|7@1+ (0.0075,0) [0|0.9525] "m"  RDR05
 SG_ DET_RANGE_VELOCITY_004_Rx : 384|15@1+ (0.0078125,-128) [-128|127.9921875] "m/s"  RDR05
 SG_ DET_RANGE_VELOCITY_ERR_004_Rx : 400|8@1+ (0.003,0) [0|0.765] "m/s"  RDR05
 SG_ DET_AZIMUTH_004_Rx : 424|13@1+ (0.0004,-1.5708) [-1.5708|1.5708] "rad"  RDR05
 SG_ DET_AZIMUTH_ERR_004_Rx : 441|7@1+ (0.00087267,0) [0|0.11082909] "rad"  RDR05
 SG_ DET_ELEVATION_004_Rx : 408|8@1+ (0.00275,-0.34925) [-0.34925|0.34925] "rad"  RDR05
 SG_ DET_ELEVATION_ERR_004_Rx : 416|6@1+ (0.00174533,0) [0|0.10995579] "rad"  RDR05
 SG_ DET_RCS_004_Rx : 464|8@1+ (0.5,-64) [-64|63.5] "dBsm"  RDR05
 SG_ DET_BI_STATIC_FLAG_004_Rx : 440|1@1+ (1,0) [0|1] ""  RDR05
 SG_ DET_SUPER_RES_TARGET_004_Rx : 423|1@1+ (1,0) [0|1] ""  RDR05
 SG_ DET_SNR_004_Rx : 456|8@1+ (0.35156,0) [0|89.6478] "dB"  RDR05
 SG_ DET_EXISTENCE_PROB_004_Rx : 448|6@1+ (1.588,0) [0|100] "%"  RDR05
 SG_ DET_HVC_FLAG_004_Rx : 422|1@1+ (1,0) [0|1] ""  RDR05
 SG_ DET_CONFD_AZIMUTH_004_Rx : 454|2@1+ (1,0) [0|3] ""  RDR05
 SG_ DET_CONFD_ELEVATION_004_Rx : 437|2@1+ (1,0) [0|3] ""  RDR05
 SG_ DET_MH_SCAN_INDEX_4LSB_001_004_R : 476|4@1+ (1,0) [0|15] ""  RDR05
 SG_ DET_MH_CYCLE_COUNTER_001_004_Rx : 16|8@1+ (1,0) [0|255] ""  RDR05
 SG_ DET_MH_CRC16_001_004_Rx : 0|16@1+ (1,0) [0|65535] ""  RDR05
 SG_ DET_PROB_1STAZHYPO_004_Rx : 439|1@1+ (1,0) [0|1] ""  RDR05
 SG_ DET_IDM_004_Rx : 399|1@1+ (1,0) [0|1] ""  RDR05
 SG_ DET_MTD_004_Rx : 383|1@1+ (1,0) [0|1] ""  RDR05
 SG_ DET_BELOW_RAIN_THOLD_004_Rx : 375|1@1+ (1,0) [0|1] ""  RDR05

BO_ 257 RDR_FUSION_DET_005_008: 64 RDR_Fusion_Partner
 SG_ DET_RANGE_005_Rx : 24|15@1+ (0.015625,0) [0|500] "m"  RDR05
 SG_ DET_RANGE_ERR_005_Rx : 40|7@1+ (0.0075,0) [0|0.9525] "m"  RDR05
 SG_ DET_RANGE_VELOCITY_005_Rx : 48|15@1+ (0.0078125,-128) [-128|127.9921875] "m/s"  RDR05
 SG_ DET_RANGE_VELOCITY_ERR_005_Rx : 64|8@1+ (0.003,0) [0|0.765] "m/s"  RDR05
 SG_ DET_AZIMUTH_005_Rx : 88|13@1+ (0.0004,-1.5708) [-1.5708|1.5708] "rad"  RDR05
 SG_ DET_AZIMUTH_ERR_005_Rx : 105|7@1+ (0.00087267,0) [0|0.11082909] "rad"  RDR05
 SG_ DET_ELEVATION_005_Rx : 72|8@1+ (0.00275,-0.34925) [-0.34925|0.34925] "rad"  RDR05
 SG_ DET_ELEVATION_ERR_005_Rx : 80|6@1+ (0.00174533,0) [0|0.10995579] "rad"  RDR05
 SG_ DET_RCS_005_Rx : 128|8@1+ (0.5,-64) [-64|63.5] "dBsm"  RDR05
 SG_ DET_BI_STATIC_FLAG_005_Rx : 104|1@1+ (1,0) [0|1] ""  RDR05
 SG_ DET_SUPER_RES_TARGET_005_Rx : 87|1@1+ (1,0) [0|1] ""  RDR05
 SG_ DET_SNR_005_Rx : 120|8@1+ (0.35156,0) [0|89.6478] "dB"  RDR05
 SG_ DET_EXISTENCE_PROB_005_Rx : 112|6@1+ (1.588,0) [0|100] "%"  RDR05
 SG_ DET_HVC_FLAG_005_Rx : 86|1@1+ (1,0) [0|1] ""  RDR05
 SG_ DET_CONFD_AZIMUTH_005_Rx : 118|2@1+ (1,0) [0|3] ""  RDR05
 SG_ DET_CONFD_ELEVATION_005_Rx : 101|2@1+ (1,0) [0|3] ""  RDR05
 SG_ DET_PROB_1STAZHYPO_005_Rx : 103|1@1+ (1,0) [0|1] ""  RDR05
 SG_ DET_IDM_005_Rx : 63|1@1+ (1,0) [0|1] ""  RDR05
 SG_ DET_MTD_005_Rx : 47|1@1+ (1,0) [0|1] ""  RDR05
 SG_ DET_BELOW_RAIN_THOLD_005_Rx : 39|1@1+ (1,0) [0|1] ""  RDR05
 SG_ DET_RANGE_006_Rx : 136|15@1+ (0.015625,0) [0|500] "m"  RDR05
 SG_ DET_RANGE_ERR_006_Rx : 152|7@1+ (0.0075,0) [0|0.9525] "m"  RDR05
 SG_ DET_RANGE_VELOCITY_006_Rx : 160|15@1+ (0.0078125,-128) [-128|127.9921875] "m/s"  RDR05
 SG_ DET_RANGE_VELOCITY_ERR_006_Rx : 176|8@1+ (0.003,0) [0|0.765] "m/s"  RDR05
 SG_ DET_AZIMUTH_006_Rx : 200|13@1+ (0.0004,-1.5708) [-1.5708|1.5708] "rad"  RDR05
 SG_ DET_AZIMUTH_ERR_006_Rx : 217|7@1+ (0.00087267,0) [0|0.11082909] "rad"  RDR05
 SG_ DET_ELEVATION_006_Rx : 184|8@1+ (0.00275,-0.34925) [-0.34925|0.34925] "rad"  RDR05
 SG_ DET_ELEVATION_ERR_006_Rx : 192|6@1+ (0.00174533,0) [0|0.10995579] "rad"  RDR05
 SG_ DET_RCS_006_Rx : 240|8@1+ (0.5,-64) [-64|63.5] "dBsm"  RDR05
 SG_ DET_BI_STATIC_FLAG_006_Rx : 216|1@1+ (1,0) [0|1] ""  RDR05
 SG_ DET_SUPER_RES_TARGET_006_Rx : 199|1@1+ (1,0) [0|1] ""  RDR05
 SG_ DET_SNR_006_Rx : 232|8@1+ (0.35156,0) [0|89.6478] "dB"  RDR05
 SG_ DET_EXISTENCE_PROB_006_Rx : 224|6@1+ (1.588,0) [0|100] "%"  RDR05
 SG_ DET_HVC_FLAG_006_Rx : 198|1@1+ (1,0) [0|1] ""  RDR05
 SG_ DET_CONFD_AZIMUTH_006_Rx : 230|2@1+ (1,0) [0|3] ""  RDR05
 SG_ DET_CONFD_ELEVATION_006_Rx : 213|2@1+ (1,0) [0|3] ""  RDR05
 SG_ DET_PROB_1STAZHYPO_006_Rx : 215|1@1+ (1,0) [0|1] ""  RDR05
 SG_ DET_IDM_006_Rx : 175|1@1+ (1,0) [0|1] ""  RDR05
 SG_ DET_MTD_006_Rx : 159|1@1+ (1,0) [0|1] ""  RDR05
 SG_ DET_BELOW_RAIN_THOLD_006_Rx : 151|1@1+ (1,0) [0|1] ""  RDR05
 SG_ DET_RANGE_007_Rx : 248|15@1+ (0.015625,0) [0|500] "m"  RDR05
 SG_ DET_RANGE_ERR_007_Rx : 264|7@1+ (0.0075,0) [0|0.9525] "m"  RDR05
 SG_ DET_RANGE_VELOCITY_007_Rx : 272|15@1+ (0.0078125,-128) [-128|127.9921875] "m/s"  RDR05
 SG_ DET_RANGE_VELOCITY_ERR_007_Rx : 288|8@1+ (0.003,0) [0|0.765] "m/s"  RDR05
 SG_ DET_AZIMUTH_007_Rx : 312|13@1+ (0.0004,-1.5708) [-1.5708|1.5708] "rad"  RDR05
 SG_ DET_AZIMUTH_ERR_007_Rx : 329|7@1+ (0.00087267,0) [0|0.11082909] "rad"  RDR05
 SG_ DET_ELEVATION_007_Rx : 296|8@1+ (0.00275,-0.34925) [-0.34925|0.34925] "rad"  RDR05
 SG_ DET_ELEVATION_ERR_007_Rx : 304|6@1+ (0.00174533,0) [0|0.10995579] "rad"  RDR05
 SG_ DET_RCS_007_Rx : 352|8@1+ (0.5,-64) [-64|63.5] "dBsm"  RDR05
 SG_ DET_BI_STATIC_FLAG_007_Rx : 328|1@1+ (1,0) [0|1] ""  RDR05
 SG_ DET_SUPER_RES_TARGET_007_Rx : 311|1@1+ (1,0) [0|1] ""  RDR05
 SG_ DET_SNR_007_Rx : 344|8@1+ (0.35156,0) [0|89.6478] "dB"  RDR05
 SG_ DET_EXISTENCE_PROB_007_Rx : 336|6@1+ (1.588,0) [0|100] "%"  RDR05
 SG_ DET_HVC_FLAG_007_Rx : 310|1@1+ (1,0) [0|1] ""  RDR05
 SG_ DET_CONFD_AZIMUTH_007_Rx : 342|2@1+ (1,0) [0|3] ""  RDR05
 SG_ DET_CONFD_ELEVATION_007_Rx : 325|2@1+ (1,0) [0|3] ""  RDR05
 SG_ DET_PROB_1STAZHYPO_007_Rx : 327|1@1+ (1,0) [0|1] ""  RDR05
 SG_ DET_IDM_007_Rx : 287|1@1+ (1,0) [0|1] ""  RDR05
 SG_ DET_MTD_007_Rx : 271|1@1+ (1,0) [0|1] ""  RDR05
 SG_ DET_BELOW_RAIN_THOLD_007_Rx : 263|1@1+ (1,0) [0|1] ""  RDR05
 SG_ DET_RANGE_008_Rx : 360|15@1+ (0.015625,0) [0|500] "m"  RDR05
 SG_ DET_RANGE_ERR_008_Rx : 376|7@1+ (0.0075,0) [0|0.9525] "m"  RDR05
 SG_ DET_RANGE_VELOCITY_008_Rx : 384|15@1+ (0.0078125,-128) [-128|127.9921875] "m/s"  RDR05
 SG_ DET_RANGE_VELOCITY_ERR_008_Rx : 400|8@1+ (0.003,0) [0|0.765] "m/s"  RDR05
 SG_ DET_AZIMUTH_008_Rx : 424|13@1+ (0.0004,-1.5708) [-1.5708|1.5708] "rad"  RDR05
 SG_ DET_AZIMUTH_ERR_008_Rx : 441|7@1+ (0.00087267,0) [0|0.11082909] "rad"  RDR05
 SG_ DET_ELEVATION_008_Rx : 408|8@1+ (0.00275,-0.34925) [-0.34925|0.34925] "rad"  RDR05
 SG_ DET_ELEVATION_ERR_008_Rx : 416|6@1+ (0.00174533,0) [0|0.10995579] "rad"  RDR05
 SG_ DET_RCS_008_Rx : 464|8@1+ (0.5,-64) [-64|63.5] "dBsm"  RDR05
 SG_ DET_BI_STATIC_FLAG_008_Rx : 440|1@1+ (1,0) [0|1] ""  RDR05
 SG_ DET_SUPER_RES_TARGET_008_Rx : 423|1@1+ (1,0) [0|1] ""  RDR05
 SG_ DET_SNR_008_Rx : 456|8@1+ (0.35156,0) [0|89.6478] "dB"  RDR05
 SG_ DET_EXISTENCE_PROB_008_Rx : 448|6@1+ (1.588,0) [0|100] "%"  RDR05
 SG_ DET_HVC_FLAG_008_Rx : 422|1@1+ (1,0) [0|1] ""  RDR05
 SG_ DET_CONFD_AZIMUTH_008_Rx : 454|2@1+ (1,0) [0|3] ""  RDR05
 SG_ DET_CONFD_ELEVATION_008_Rx : 437|2@1+ (1,0) [0|3] ""  RDR05
 SG_ DET_MH_SCAN_INDEX_4LSB_005_008_R : 476|4@1+ (1,0) [0|15] ""  RDR05
 SG_ DET_MH_CYCLE_COUNTER_005_008_Rx : 16|8@1+ (1,0) [0|255] ""  RDR05
 SG_ DET_MH_CRC16_005_008_Rx : 0|16@1+ (1,0) [0|65535] ""  RDR05
 SG_ DET_PROB_1STAZHYPO_008_Rx : 439|1@1+ (1,0) [0|1] ""  RDR05
 SG_ DET_IDM_008_Rx : 399|1@1+ (1,0) [0|1] ""  RDR05
 SG_ DET_MTD_008_Rx : 383|1@1+ (1,0) [0|1] ""  RDR05
 SG_ DET_BELOW_RAIN_THOLD_008_Rx : 375|1@1+ (1,0) [0|1] ""  RDR05

BO_ 258 RDR_FUSION_DET_009_012: 64 RDR_Fusion_Partner
 SG_ DET_RANGE_009_Rx : 24|15@1+ (0.015625,0) [0|500] "m"  RDR05
 SG_ DET_RANGE_ERR_009_Rx : 40|7@1+ (0.0075,0) [0|0.9525] "m"  RDR05
 SG_ DET_RANGE_VELOCITY_009_Rx : 48|15@1+ (0.0078125,-128) [-128|127.9921875] "m/s"  RDR05
 SG_ DET_RANGE_VELOCITY_ERR_009_Rx : 64|8@1+ (0.003,0) [0|0.765] "m/s"  RDR05
 SG_ DET_AZIMUTH_009_Rx : 88|13@1+ (0.0004,-1.5708) [-1.5708|1.5708] "rad"  RDR05
 SG_ DET_AZIMUTH_ERR_009_Rx : 105|7@1+ (0.00087267,0) [0|0.11082909] "rad"  RDR05
 SG_ DET_ELEVATION_009_Rx : 72|8@1+ (0.00275,-0.34925) [-0.34925|0.34925] "rad"  RDR05
 SG_ DET_ELEVATION_ERR_009_Rx : 80|6@1+ (0.00174533,0) [0|0.10995579] "rad"  RDR05
 SG_ DET_RCS_009_Rx : 128|8@1+ (0.5,-64) [-64|63.5] "dBsm"  RDR05
 SG_ DET_BI_STATIC_FLAG_009_Rx : 104|1@1+ (1,0) [0|1] ""  RDR05
 SG_ DET_SUPER_RES_TARGET_009_Rx : 87|1@1+ (1,0) [0|1] ""  RDR05
 SG_ DET_SNR_009_Rx : 120|8@1+ (0.35156,0) [0|89.6478] "dB"  RDR05
 SG_ DET_EXISTENCE_PROB_009_Rx : 112|6@1+ (1.588,0) [0|100] "%"  RDR05
 SG_ DET_HVC_FLAG_009_Rx : 86|1@1+ (1,0) [0|1] ""  RDR05
 SG_ DET_CONFD_AZIMUTH_009_Rx : 118|2@1+ (1,0) [0|3] ""  RDR05
 SG_ DET_CONFD_ELEVATION_009_Rx : 101|2@1+ (1,0) [0|3] ""  RDR05
 SG_ DET_PROB_1STAZHYPO_009_Rx : 103|1@1+ (1,0) [0|1] ""  RDR05
 SG_ DET_IDM_009_Rx : 63|1@1+ (1,0) [0|1] ""  RDR05
 SG_ DET_MTD_009_Rx : 47|1@1+ (1,0) [0|1] ""  RDR05
 SG_ DET_BELOW_RAIN_THOLD_009_Rx : 39|1@1+ (1,0) [0|1] ""  RDR05
 SG_ DET_RANGE_010_Rx : 136|15@1+ (0.015625,0) [0|500] "m"  RDR05
 SG_ DET_RANGE_ERR_010_Rx : 152|7@1+ (0.0075,0) [0|0.9525] "m"  RDR05
 SG_ DET_RANGE_VELOCITY_010_Rx : 160|15@1+ (0.0078125,-128) [-128|127.9921875] "m/s"  RDR05
 SG_ DET_RANGE_VELOCITY_ERR_010_Rx : 176|8@1+ (0.003,0) [0|0.765] "m/s"  RDR05
 SG_ DET_AZIMUTH_010_Rx : 200|13@1+ (0.0004,-1.5708) [-1.5708|1.5708] "rad"  RDR05
 SG_ DET_AZIMUTH_ERR_010_Rx : 217|7@1+ (0.00087267,0) [0|0.11082909] "rad"  RDR05
 SG_ DET_ELEVATION_010_Rx : 184|8@1+ (0.00275,-0.34925) [-0.34925|0.34925] "rad"  RDR05
 SG_ DET_ELEVATION_ERR_010_Rx : 192|6@1+ (0.00174533,0) [0|0.10995579] "rad"  RDR05
 SG_ DET_RCS_010_Rx : 240|8@1+ (0.5,-64) [-64|63.5] "dBsm"  RDR05
 SG_ DET_BI_STATIC_FLAG_010_Rx : 216|1@1+ (1,0) [0|1] ""  RDR05
 SG_ DET_SUPER_RES_TARGET_010_Rx : 199|1@1+ (1,0) [0|1] ""  RDR05
 SG_ DET_SNR_010_Rx : 232|8@1+ (0.35156,0) [0|89.6478] "dB"  RDR05
 SG_ DET_EXISTENCE_PROB_010_Rx : 224|6@1+ (1.588,0) [0|100] "%"  RDR05
 SG_ DET_HVC_FLAG_010_Rx : 198|1@1+ (1,0) [0|1] ""  RDR05
 SG_ DET_CONFD_AZIMUTH_010_Rx : 230|2@1+ (1,0) [0|3] ""  RDR05
 SG_ DET_CONFD_ELEVATION_010_Rx : 213|2@1+ (1,0) [0|3] ""  RDR05
 SG_ DET_PROB_1STAZHYPO_010_Rx : 215|1@1+ (1,0) [0|1] ""  RDR05
 SG_ DET_IDM_010_Rx : 175|1@1+ (1,0) [0|1] ""  RDR05
 SG_ DET_MTD_010_Rx : 159|1@1+ (1,0) [0|1] ""  RDR05
 SG_ DET_BELOW_RAIN_THOLD_010_Rx : 151|1@1+ (1,0) [0|1] ""  RDR05
 SG_ DET_RANGE_011_Rx : 248|15@1+ (0.015625,0) [0|500] "m"  RDR05
 SG_ DET_RANGE_ERR_011_Rx : 264|7@1+ (0.0075,0) [0|0.9525] "m"  RDR05
 SG_ DET_RANGE_VELOCITY_011_Rx : 272|15@1+ (0.0078125,-128) [-128|127.9921875] "m/s"  RDR05
 SG_ DET_RANGE_VELOCITY_ERR_011_Rx : 288|8@1+ (0.003,0) [0|0.765] "m/s"  RDR05
 SG_ DET_AZIMUTH_011_Rx : 312|13@1+ (0.0004,-1.5708) [-1.5708|1.5708] "rad"  RDR05
 SG_ DET_AZIMUTH_ERR_011_Rx : 329|7@1+ (0.00087267,0) [0|0.11082909] "rad"  RDR05
 SG_ DET_ELEVATION_011_Rx : 296|8@1+ (0.00275,-0.34925) [-0.34925|0.34925] "rad"  RDR05
 SG_ DET_ELEVATION_ERR_011_Rx : 304|6@1+ (0.00174533,0) [0|0.10995579] "rad"  RDR05
 SG_ DET_RCS_011_Rx : 352|8@1+ (0.5,-64) [-64|63.5] "dBsm"  RDR05
 SG_ DET_BI_STATIC_FLAG_011_Rx : 328|1@1+ (1,0) [0|1] ""  RDR05
 SG_ DET_SUPER_RES_TARGET_011_Rx : 311|1@1+ (1,0) [0|1] ""  RDR05
 SG_ DET_SNR_011_Rx : 344|8@1+ (0.35156,0) [0|89.6478] "dB"  RDR05
 SG_ DET_EXISTENCE_PROB_011_Rx : 336|6@1+ (1.588,0) [0|100] "%"  RDR05
 SG_ DET_HVC_FLAG_011_Rx : 310|1@1+ (1,0) [0|1] ""  RDR05
 SG_ DET_CONFD_AZIMUTH_011_Rx : 342|2@1+ (1,0) [0|3] ""  RDR05
 SG_ DET_CONFD_ELEVATION_011_Rx : 325|2@1+ (1,0) [0|3] ""  RDR05
 SG_ DET_PROB_1STAZHYPO_011_Rx : 327|1@1+ (1,0) [0|1] ""  RDR05
 SG_ DET_IDM_011_Rx : 287|1@1+ (1,0) [0|1] ""  RDR05
 SG_ DET_MTD_011_Rx : 271|1@1+ (1,0) [0|1] ""  RDR05
 SG_ DET_BELOW_RAIN_THOLD_011_Rx : 263|1@1+ (1,0) [0|1] ""  RDR05
 SG_ DET_RANGE_012_Rx : 360|15@1+ (0.015625,0) [0|500] "m"  RDR05
 SG_ DET_RANGE_ERR_012_Rx : 376|7@1+ (0.0075,0) [0|0.9525] "m"  RDR05
 SG_ DET_RANGE_VELOCITY_012_Rx : 384|15@1+ (0.0078125,-128) [-128|127.9921875] "m/s"  RDR05
 SG_ DET_RANGE_VELOCITY_ERR_012_Rx : 400|8@1+ (0.003,0) [0|0.765] "m/s"  RDR05
 SG_ DET_AZIMUTH_012_Rx : 424|13@1+ (0.0004,-1.5708) [-1.5708|1.5708] "rad"  RDR05
 SG_ DET_AZIMUTH_ERR_012_Rx : 441|7@1+ (0.00087267,0) [0|0.11082909] "rad"  RDR05
 SG_ DET_ELEVATION_012_Rx : 408|8@1+ (0.00275,-0.34925) [-0.34925|0.34925] "rad"  RDR05
 SG_ DET_ELEVATION_ERR_012_Rx : 416|6@1+ (0.00174533,0) [0|0.10995579] "rad"  RDR05
 SG_ DET_RCS_012_Rx : 464|8@1+ (0.5,-64) [-64|63.5] "dBsm"  RDR05
 SG_ DET_BI_STATIC_FLAG_012_Rx : 440|1@1+ (1,0) [0|1] ""  RDR05
 SG_ DET_SUPER_RES_TARGET_012_Rx : 423|1@1+ (1,0) [0|1] ""  RDR05
 SG_ DET_SNR_012_Rx : 456|8@1+ (0.35156,0) [0|89.6478] "dB"  RDR05
 SG_ DET_EXISTENCE_PROB_012_Rx : 448|6@1+ (1.588,0) [0|100] "%"  RDR05
 SG_ DET_HVC_FLAG_012_Rx : 422|1@1+ (1,0) [0|1] ""  RDR05
 SG_ DET_CONFD_AZIMUTH_012_Rx : 454|2@1+ (1,0) [0|3] ""  RDR05
 SG_ DET_CONFD_ELEVATION_012_Rx : 437|2@1+ (1,0) [0|3] ""  RDR05
 SG_ DET_MH_SCAN_INDEX_4LSB_009_012_R : 476|4@1+ (1,0) [0|15] ""  RDR05
 SG_ DET_MH_CYCLE_COUNTER_009_012_Rx : 16|8@1+ (1,0) [0|255] ""  RDR05
 SG_ DET_MH_CRC16_009_012_Rx : 0|16@1+ (1,0) [0|65535] ""  RDR05
 SG_ DET_PROB_1STAZHYPO_012_Rx : 439|1@1+ (1,0) [0|1] ""  RDR05
 SG_ DET_IDM_012_Rx : 399|1@1+ (1,0) [0|1] ""  RDR05
 SG_ DET_MTD_012_Rx : 383|1@1+ (1,0) [0|1] ""  RDR05
 SG_ DET_BELOW_RAIN_THOLD_012_Rx : 375|1@1+ (1,0) [0|1] ""  RDR05

BO_ 259 RDR_FUSION_DET_013_016: 64 RDR_Fusion_Partner
 SG_ DET_RANGE_013_Rx : 24|15@1+ (0.015625,0) [0|500] "m"  RDR05
 SG_ DET_RANGE_ERR_013_Rx : 40|7@1+ (0.0075,0) [0|0.9525] "m"  RDR05
 SG_ DET_RANGE_VELOCITY_013_Rx : 48|15@1+ (0.0078125,-128) [-128|127.9921875] "m/s"  RDR05
 SG_ DET_RANGE_VELOCITY_ERR_013_Rx : 64|8@1+ (0.003,0) [0|0.765] "m/s"  RDR05
 SG_ DET_AZIMUTH_013_Rx : 88|13@1+ (0.0004,-1.5708) [-1.5708|1.5708] "rad"  RDR05
 SG_ DET_AZIMUTH_ERR_013_Rx : 105|7@1+ (0.00087267,0) [0|0.11082909] "rad"  RDR05
 SG_ DET_ELEVATION_013_Rx : 72|8@1+ (0.00275,-0.34925) [-0.34925|0.34925] "rad"  RDR05
 SG_ DET_ELEVATION_ERR_013_Rx : 80|6@1+ (0.00174533,0) [0|0.10995579] "rad"  RDR05
 SG_ DET_RCS_013_Rx : 128|8@1+ (0.5,-64) [-64|63.5] "dBsm"  RDR05
 SG_ DET_BI_STATIC_FLAG_013_Rx : 104|1@1+ (1,0) [0|1] ""  RDR05
 SG_ DET_SUPER_RES_TARGET_013_Rx : 87|1@1+ (1,0) [0|1] ""  RDR05
 SG_ DET_SNR_013_Rx : 120|8@1+ (0.35156,0) [0|89.6478] "dB"  RDR05
 SG_ DET_EXISTENCE_PROB_013_Rx : 112|6@1+ (1.588,0) [0|100] "%"  RDR05
 SG_ DET_HVC_FLAG_013_Rx : 86|1@1+ (1,0) [0|1] ""  RDR05
 SG_ DET_CONFD_AZIMUTH_013_Rx : 118|2@1+ (1,0) [0|3] ""  RDR05
 SG_ DET_CONFD_ELEVATION_013_Rx : 101|2@1+ (1,0) [0|3] ""  RDR05
 SG_ DET_PROB_1STAZHYPO_013_Rx : 103|1@1+ (1,0) [0|1] ""  RDR05
 SG_ DET_IDM_013_Rx : 63|1@1+ (1,0) [0|1] ""  RDR05
 SG_ DET_MTD_013_Rx : 47|1@1+ (1,0) [0|1] ""  RDR05
 SG_ DET_BELOW_RAIN_THOLD_013_Rx : 39|1@1+ (1,0) [0|1] ""  RDR05
 SG_ DET_RANGE_014_Rx : 136|15@1+ (0.015625,0) [0|500] "m"  RDR05
 SG_ DET_RANGE_ERR_014_Rx : 152|7@1+ (0.0075,0) [0|0.9525] "m"  RDR05
 SG_ DET_RANGE_VELOCITY_014_Rx : 160|15@1+ (0.0078125,-128) [-128|127.9921875] "m/s"  RDR05
 SG_ DET_RANGE_VELOCITY_ERR_014_Rx : 176|8@1+ (0.003,0) [0|0.765] "m/s"  RDR05
 SG_ DET_AZIMUTH_014_Rx : 200|13@1+ (0.0004,-1.5708) [-1.5708|1.5708] "rad"  RDR05
 SG_ DET_AZIMUTH_ERR_014_Rx : 217|7@1+ (0.00087267,0) [0|0.11082909] "rad"  RDR05
 SG_ DET_ELEVATION_014_Rx : 184|8@1+ (0.00275,-0.34925) [-0.34925|0.34925] "rad"  RDR05
 SG_ DET_ELEVATION_ERR_014_Rx : 192|6@1+ (0.00174533,0) [0|0.10995579] "rad"  RDR05
 SG_ DET_RCS_014_Rx : 240|8@1+ (0.5,-64) [-64|63.5] "dBsm"  RDR05
 SG_ DET_BI_STATIC_FLAG_014_Rx : 216|1@1+ (1,0) [0|1] ""  RDR05
 SG_ DET_SUPER_RES_TARGET_014_Rx : 199|1@1+ (1,0) [0|1] ""  RDR05
 SG_ DET_SNR_014_Rx : 232|8@1+ (0.35156,0) [0|89.6478] "dB"  RDR05
 SG_ DET_EXISTENCE_PROB_014_Rx : 224|6@1+ (1.588,0) [0|100] "%"  RDR05
 SG_ DET_HVC_FLAG_014_Rx : 198|1@1+ (1,0) [0|1] ""  RDR05
 SG_ DET_CONFD_AZIMUTH_014_Rx : 230|2@1+ (1,0) [0|3] ""  RDR05
 SG_ DET_CONFD_ELEVATION_014_Rx : 213|2@1+ (1,0) [0|3] ""  RDR05
 SG_ DET_PROB_1STAZHYPO_014_Rx : 215|1@1+ (1,0) [0|1] ""  RDR05
 SG_ DET_IDM_014_Rx : 175|1@1+ (1,0) [0|1] ""  RDR05
 SG_ DET_MTD_014_Rx : 159|1@1+ (1,0) [0|1] ""  RDR05
 SG_ DET_BELOW_RAIN_THOLD_014_Rx : 151|1@1+ (1,0) [0|1] ""  RDR05
 SG_ DET_RANGE_015_Rx : 248|15@1+ (0.015625,0) [0|500] "m"  RDR05
 SG_ DET_RANGE_ERR_015_Rx : 264|7@1+ (0.0075,0) [0|0.9525] "m"  RDR05
 SG_ DET_RANGE_VELOCITY_015_Rx : 272|15@1+ (0.0078125,-128) [-128|127.9921875] "m/s"  RDR05
 SG_ DET_RANGE_VELOCITY_ERR_015_Rx : 288|8@1+ (0.003,0) [0|0.765] "m/s"  RDR05
 SG_ DET_AZIMUTH_015_Rx : 312|13@1+ (0.0004,-1.5708) [-1.5708|1.5708] "rad"  RDR05
 SG_ DET_AZIMUTH_ERR_015_Rx : 329|7@1+ (0.00087267,0) [0|0.11082909] "rad"  RDR05
 SG_ DET_ELEVATION_015_Rx : 296|8@1+ (0.00275,-0.34925) [-0.34925|0.34925] "rad"  RDR05
 SG_ DET_ELEVATION_ERR_015_Rx : 304|6@1+ (0.00174533,0) [0|0.10995579] "rad"  RDR05
 SG_ DET_RCS_015_Rx : 352|8@1+ (0.5,-64) [-64|63.5] "dBsm"  RDR05
 SG_ DET_BI_STATIC_FLAG_015_Rx : 328|1@1+ (1,0) [0|1] ""  RDR05
 SG_ DET_SUPER_RES_TARGET_015_Rx : 311|1@1+ (1,0) [0|1] ""  RDR05
 SG_ DET_SNR_015_Rx : 344|8@1+ (0.35156,0) [0|89.6478] "dB"  RDR05
 SG_ DET_EXISTENCE_PROB_015_Rx : 336|6@1+ (1.588,0) [0|100] "%"  RDR05
 SG_ DET_HVC_FLAG_015_Rx : 310|1@1+ (1,0) [0|1] ""  RDR05
 SG_ DET_CONFD_AZIMUTH_015_Rx : 342|2@1+ (1,0) [0|3] ""  RDR05
 SG_ DET_CONFD_ELEVATION_015_Rx : 325|2@1+ (1,0) [0|3] ""  RDR05
 SG_ DET_PROB_1STAZHYPO_015_Rx : 327|1@1+ (1,0) [0|1] ""  RDR05
 SG_ DET_IDM_015_Rx : 287|1@1+ (1,0) [0|1] ""  RDR05
 SG_ DET_MTD_015_Rx : 271|1@1+ (1,0) [0|1] ""  RDR05
 SG_ DET_BELOW_RAIN_THOLD_015_Rx : 263|1@1+ (1,0) [0|1] ""  RDR05
 SG_ DET_RANGE_016_Rx : 360|15@1+ (0.015625,0) [0|500] "m"  RDR05
 SG_ DET_RANGE_ERR_016_Rx : 376|7@1+ (0.0075,0) [0|0.9525] "m"  RDR05
 SG_ DET_RANGE_VELOCITY_016_Rx : 384|15@1+ (0.0078125,-128) [-128|127.9921875] "m/s"  RDR05
 SG_ DET_RANGE_VELOCITY_ERR_016_Rx : 400|8@1+ (0.003,0) [0|0.765] "m/s"  RDR05
 SG_ DET_AZIMUTH_016_Rx : 424|13@1+ (0.0004,-1.5708) [-1.5708|1.5708] "rad"  RDR05
 SG_ DET_AZIMUTH_ERR_016_Rx : 441|7@1+ (0.00087267,0) [0|0.11082909] "rad"  RDR05
 SG_ DET_ELEVATION_016_Rx : 408|8@1+ (0.00275,-0.34925) [-0.34925|0.34925] "rad"  RDR05
 SG_ DET_ELEVATION_ERR_016_Rx : 416|6@1+ (0.00174533,0) [0|0.10995579] "rad"  RDR05
 SG_ DET_RCS_016_Rx : 464|8@1+ (0.5,-64) [-64|63.5] "dBsm"  RDR05
 SG_ DET_BI_STATIC_FLAG_016_Rx : 440|1@1+ (1,0) [0|1] ""  RDR05
 SG_ DET_SUPER_RES_TARGET_016_Rx : 423|1@1+ (1,0) [0|1] ""  RDR05
 SG_ DET_SNR_016_Rx : 456|8@1+ (0.35156,0) [0|89.6478] "dB"  RDR05
 SG_ DET_EXISTENCE_PROB_016_Rx : 448|6@1+ (1.588,0) [0|100] "%"  RDR05
 SG_ DET_HVC_FLAG_016_Rx : 422|1@1+ (1,0) [0|1] ""  RDR05
 SG_ DET_CONFD_AZIMUTH_016_Rx : 454|2@1+ (1,0) [0|3] ""  RDR05
 SG_ DET_CONFD_ELEVATION_016_Rx : 437|2@1+ (1,0) [0|3] ""  RDR05
 SG_ DET_MH_SCAN_INDEX_4LSB_013_016_R : 476|4@1+ (1,0) [0|15] ""  RDR05
 SG_ DET_MH_CYCLE_COUNTER_013_016_Rx : 16|8@1+ (1,0) [0|255] ""  RDR05
 SG_ DET_MH_CRC16_013_016_Rx : 0|16@1+ (1,0) [0|65535] ""  RDR05
 SG_ DET_PROB_1STAZHYPO_016_Rx : 439|1@1+ (1,0) [0|1] ""  RDR05
 SG_ DET_IDM_016_Rx : 399|1@1+ (1,0) [0|1] ""  RDR05
 SG_ DET_MTD_016_Rx : 383|1@1+ (1,0) [0|1] ""  RDR05
 SG_ DET_BELOW_RAIN_THOLD_016_Rx : 375|1@1+ (1,0) [0|1] ""  RDR05

BO_ 260 RDR_FUSION_DET_017_020: 64 RDR_Fusion_Partner
 SG_ DET_RANGE_017_Rx : 24|15@1+ (0.015625,0) [0|500] "m"  RDR05
 SG_ DET_RANGE_ERR_017_Rx : 40|7@1+ (0.0075,0) [0|0.9525] "m"  RDR05
 SG_ DET_RANGE_VELOCITY_017_Rx : 48|15@1+ (0.0078125,-128) [-128|127.9921875] "m/s"  RDR05
 SG_ DET_RANGE_VELOCITY_ERR_017_Rx : 64|8@1+ (0.003,0) [0|0.765] "m/s"  RDR05
 SG_ DET_AZIMUTH_017_Rx : 88|13@1+ (0.0004,-1.5708) [-1.5708|1.5708] "rad"  RDR05
 SG_ DET_AZIMUTH_ERR_017_Rx : 105|7@1+ (0.00087267,0) [0|0.11082909] "rad"  RDR05
 SG_ DET_ELEVATION_017_Rx : 72|8@1+ (0.00275,-0.34925) [-0.34925|0.34925] "rad"  RDR05
 SG_ DET_ELEVATION_ERR_017_Rx : 80|6@1+ (0.00174533,0) [0|0.10995579] "rad"  RDR05
 SG_ DET_RCS_017_Rx : 128|8@1+ (0.5,-64) [-64|63.5] "dBsm"  RDR05
 SG_ DET_BI_STATIC_FLAG_017_Rx : 104|1@1+ (1,0) [0|1] ""  RDR05
 SG_ DET_SUPER_RES_TARGET_017_Rx : 87|1@1+ (1,0) [0|1] ""  RDR05
 SG_ DET_SNR_017_Rx : 120|8@1+ (0.35156,0) [0|89.6478] "dB"  RDR05
 SG_ DET_EXISTENCE_PROB_017_Rx : 112|6@1+ (1.588,0) [0|100] "%"  RDR05
 SG_ DET_HVC_FLAG_017_Rx : 86|1@1+ (1,0) [0|1] ""  RDR05
 SG_ DET_CONFD_AZIMUTH_017_Rx : 118|2@1+ (1,0) [0|3] ""  RDR05
 SG_ DET_CONFD_ELEVATION_017_Rx : 101|2@1+ (1,0) [0|3] ""  RDR05
 SG_ DET_PROB_1STAZHYPO_017_Rx : 103|1@1+ (1,0) [0|1] ""  RDR05
 SG_ DET_IDM_017_Rx : 63|1@1+ (1,0) [0|1] ""  RDR05
 SG_ DET_MTD_017_Rx : 47|1@1+ (1,0) [0|1] ""  RDR05
 SG_ DET_BELOW_RAIN_THOLD_017_Rx : 39|1@1+ (1,0) [0|1] ""  RDR05
 SG_ DET_RANGE_018_Rx : 136|15@1+ (0.015625,0) [0|500] "m"  RDR05
 SG_ DET_RANGE_ERR_018_Rx : 152|7@1+ (0.0075,0) [0|0.9525] "m"  RDR05
 SG_ DET_RANGE_VELOCITY_018_Rx : 160|15@1+ (0.0078125,-128) [-128|127.9921875] "m/s"  RDR05
 SG_ DET_RANGE_VELOCITY_ERR_018_Rx : 176|8@1+ (0.003,0) [0|0.765] "m/s"  RDR05
 SG_ DET_AZIMUTH_018_Rx : 200|13@1+ (0.0004,-1.5708) [-1.5708|1.5708] "rad"  RDR05
 SG_ DET_AZIMUTH_ERR_018_Rx : 217|7@1+ (0.00087267,0) [0|0.11082909] "rad"  RDR05
 SG_ DET_ELEVATION_018_Rx : 184|8@1+ (0.00275,-0.34925) [-0.34925|0.34925] "rad"  RDR05
 SG_ DET_ELEVATION_ERR_018_Rx : 192|6@1+ (0.00174533,0) [0|0.10995579] "rad"  RDR05
 SG_ DET_RCS_018_Rx : 240|8@1+ (0.5,-64) [-64|63.5] "dBsm"  RDR05
 SG_ DET_BI_STATIC_FLAG_018_Rx : 216|1@1+ (1,0) [0|1] ""  RDR05
 SG_ DET_SUPER_RES_TARGET_018_Rx : 199|1@1+ (1,0) [0|1] ""  RDR05
 SG_ DET_SNR_018_Rx : 232|8@1+ (0.35156,0) [0|89.6478] "dB"  RDR05
 SG_ DET_EXISTENCE_PROB_018_Rx : 224|6@1+ (1.588,0) [0|100] "%"  RDR05
 SG_ DET_HVC_FLAG_018_Rx : 198|1@1+ (1,0) [0|1] ""  RDR05
 SG_ DET_CONFD_AZIMUTH_018_Rx : 230|2@1+ (1,0) [0|3] ""  RDR05
 SG_ DET_CONFD_ELEVATION_018_Rx : 213|2@1+ (1,0) [0|3] ""  RDR05
 SG_ DET_PROB_1STAZHYPO_018_Rx : 215|1@1+ (1,0) [0|1] ""  RDR05
 SG_ DET_IDM_018_Rx : 175|1@1+ (1,0) [0|1] ""  RDR05
 SG_ DET_MTD_018_Rx : 159|1@1+ (1,0) [0|1] ""  RDR05
 SG_ DET_BELOW_RAIN_THOLD_018_Rx : 151|1@1+ (1,0) [0|1] ""  RDR05
 SG_ DET_RANGE_019_Rx : 248|15@1+ (0.015625,0) [0|500] "m"  RDR05
 SG_ DET_RANGE_ERR_019_Rx : 264|7@1+ (0.0075,0) [0|0.9525] "m"  RDR05
 SG_ DET_RANGE_VELOCITY_019_Rx : 272|15@1+ (0.0078125,-128) [-128|127.9921875] "m/s"  RDR05
 SG_ DET_RANGE_VELOCITY_ERR_019_Rx : 288|8@1+ (0.003,0) [0|0.765] "m/s"  RDR05
 SG_ DET_AZIMUTH_019_Rx : 312|13@1+ (0.0004,-1.5708) [-1.5708|1.5708] "rad"  RDR05
 SG_ DET_AZIMUTH_ERR_019_Rx : 329|7@1+ (0.00087267,0) [0|0.11082909] "rad"  RDR05
 SG_ DET_ELEVATION_019_Rx : 296|8@1+ (0.00275,-0.34925) [-0.34925|0.34925] "rad"  RDR05
 SG_ DET_ELEVATION_ERR_019_Rx : 304|6@1+ (0.00174533,0) [0|0.10995579] "rad"  RDR05
 SG_ DET_RCS_019_Rx : 352|8@1+ (0.5,-64) [-64|63.5] "dBsm"  RDR05
 SG_ DET_BI_STATIC_FLAG_019_Rx : 328|1@1+ (1,0) [0|1] ""  RDR05
 SG_ DET_SUPER_RES_TARGET_019_Rx : 311|1@1+ (1,0) [0|1] ""  RDR05
 SG_ DET_SNR_019_Rx : 344|8@1+ (0.35156,0) [0|89.6478] "dB"  RDR05
 SG_ DET_EXISTENCE_PROB_019_Rx : 336|6@1+ (1.588,0) [0|100] "%"  RDR05
 SG_ DET_HVC_FLAG_019_Rx : 310|1@1+ (1,0) [0|1] ""  RDR05
 SG_ DET_CONFD_AZIMUTH_019_Rx : 342|2@1+ (1,0) [0|3] ""  RDR05
 SG_ DET_CONFD_ELEVATION_019_Rx : 325|2@1+ (1,0) [0|3] ""  RDR05
 SG_ DET_PROB_1STAZHYPO_019_Rx : 327|1@1+ (1,0) [0|1] ""  RDR05
 SG_ DET_IDM_019_Rx : 287|1@1+ (1,0) [0|1] ""  RDR05
 SG_ DET_MTD_019_Rx : 271|1@1+ (1,0) [0|1] ""  RDR05
 SG_ DET_BELOW_RAIN_THOLD_019_Rx : 263|1@1+ (1,0) [0|1] ""  RDR05
 SG_ DET_RANGE_020_Rx : 360|15@1+ (0.015625,0) [0|500] "m"  RDR05
 SG_ DET_RANGE_ERR_020_Rx : 376|7@1+ (0.0075,0) [0|0.9525] "m"  RDR05
 SG_ DET_RANGE_VELOCITY_020_Rx : 384|15@1+ (0.0078125,-128) [-128|127.9921875] "m/s"  RDR05
 SG_ DET_RANGE_VELOCITY_ERR_020_Rx : 400|8@1+ (0.003,0) [0|0.765] "m/s"  RDR05
 SG_ DET_AZIMUTH_020_Rx : 424|13@1+ (0.0004,-1.5708) [-1.5708|1.5708] "rad"  RDR05
 SG_ DET_AZIMUTH_ERR_020_Rx : 441|7@1+ (0.00087267,0) [0|0.11082909] "rad"  RDR05
 SG_ DET_ELEVATION_020_Rx : 408|8@1+ (0.00275,-0.34925) [-0.34925|0.34925] "rad"  RDR05
 SG_ DET_ELEVATION_ERR_020_Rx : 416|6@1+ (0.00174533,0) [0|0.10995579] "rad"  RDR05
 SG_ DET_RCS_020_Rx : 464|8@1+ (0.5,-64) [-64|63.5] "dBsm"  RDR05
 SG_ DET_BI_STATIC_FLAG_020_Rx : 440|1@1+ (1,0) [0|1] ""  RDR05
 SG_ DET_SUPER_RES_TARGET_020_Rx : 423|1@1+ (1,0) [0|1] ""  RDR05
 SG_ DET_SNR_020_Rx : 456|8@1+ (0.35156,0) [0|89.6478] "dB"  RDR05
 SG_ DET_EXISTENCE_PROB_020_Rx : 448|6@1+ (1.588,0) [0|100] "%"  RDR05
 SG_ DET_HVC_FLAG_020_Rx : 422|1@1+ (1,0) [0|1] ""  RDR05
 SG_ DET_CONFD_AZIMUTH_020_Rx : 454|2@1+ (1,0) [0|3] ""  RDR05
 SG_ DET_CONFD_ELEVATION_020_Rx : 437|2@1+ (1,0) [0|3] ""  RDR05
 SG_ DET_MH_SCAN_INDEX_4LSB_017_020_R : 476|4@1+ (1,0) [0|15] ""  RDR05
 SG_ DET_MH_CYCLE_COUNTER_017_020_Rx : 16|8@1+ (1,0) [0|255] ""  RDR05
 SG_ DET_MH_CRC16_017_020_Rx : 0|16@1+ (1,0) [0|65535] ""  RDR05
 SG_ DET_PROB_1STAZHYPO_020_Rx : 439|1@1+ (1,0) [0|1] ""  RDR05
 SG_ DET_IDM_020_Rx : 399|1@1+ (1,0) [0|1] ""  RDR05
 SG_ DET_MTD_020_Rx : 383|1@1+ (1,0) [0|1] ""  RDR05
 SG_ DET_BELOW_RAIN_THOLD_020_Rx : 375|1@1+ (1,0) [0|1] ""  RDR05

BO_ 261 RDR_FUSION_DET_021_024: 64 RDR_Fusion_Partner
 SG_ DET_RANGE_021_Rx : 24|15@1+ (0.015625,0) [0|500] "m"  RDR05
 SG_ DET_RANGE_ERR_021_Rx : 40|7@1+ (0.0075,0) [0|0.9525] "m"  RDR05
 SG_ DET_RANGE_VELOCITY_021_Rx : 48|15@1+ (0.0078125,-128) [-128|127.9921875] "m/s"  RDR05
 SG_ DET_RANGE_VELOCITY_ERR_021_Rx : 64|8@1+ (0.003,0) [0|0.765] "m/s"  RDR05
 SG_ DET_AZIMUTH_021_Rx : 88|13@1+ (0.0004,-1.5708) [-1.5708|1.5708] "rad"  RDR05
 SG_ DET_AZIMUTH_ERR_021_Rx : 105|7@1+ (0.00087267,0) [0|0.11082909] "rad"  RDR05
 SG_ DET_ELEVATION_021_Rx : 72|8@1+ (0.00275,-0.34925) [-0.34925|0.34925] "rad"  RDR05
 SG_ DET_ELEVATION_ERR_021_Rx : 80|6@1+ (0.00174533,0) [0|0.10995579] "rad"  RDR05
 SG_ DET_RCS_021_Rx : 128|8@1+ (0.5,-64) [-64|63.5] "dBsm"  RDR05
 SG_ DET_BI_STATIC_FLAG_021_Rx : 104|1@1+ (1,0) [0|1] ""  RDR05
 SG_ DET_SUPER_RES_TARGET_021_Rx : 87|1@1+ (1,0) [0|1] ""  RDR05
 SG_ DET_SNR_021_Rx : 120|8@1+ (0.35156,0) [0|89.6478] "dB"  RDR05
 SG_ DET_EXISTENCE_PROB_021_Rx : 112|6@1+ (1.588,0) [0|100] "%"  RDR05
 SG_ DET_HVC_FLAG_021_Rx : 86|1@1+ (1,0) [0|1] ""  RDR05
 SG_ DET_CONFD_AZIMUTH_021_Rx : 118|2@1+ (1,0) [0|3] ""  RDR05
 SG_ DET_CONFD_ELEVATION_021_Rx : 101|2@1+ (1,0) [0|3] ""  RDR05
 SG_ DET_PROB_1STAZHYPO_021_Rx : 103|1@1+ (1,0) [0|1] ""  RDR05
 SG_ DET_IDM_021_Rx : 63|1@1+ (1,0) [0|1] ""  RDR05
 SG_ DET_MTD_021_Rx : 47|1@1+ (1,0) [0|1] ""  RDR05
 SG_ DET_BELOW_RAIN_THOLD_021_Rx : 39|1@1+ (1,0) [0|1] ""  RDR05
 SG_ DET_RANGE_022_Rx : 136|15@1+ (0.015625,0) [0|500] "m"  RDR05
 SG_ DET_RANGE_ERR_022_Rx : 152|7@1+ (0.0075,0) [0|0.9525] "m"  RDR05
 SG_ DET_RANGE_VELOCITY_022_Rx : 160|15@1+ (0.0078125,-128) [-128|127.9921875] "m/s"  RDR05
 SG_ DET_RANGE_VELOCITY_ERR_022_Rx : 176|8@1+ (0.003,0) [0|0.765] "m/s"  RDR05
 SG_ DET_AZIMUTH_022_Rx : 200|13@1+ (0.0004,-1.5708) [-1.5708|1.5708] "rad"  RDR05
 SG_ DET_AZIMUTH_ERR_022_Rx : 217|7@1+ (0.00087267,0) [0|0.11082909] "rad"  RDR05
 SG_ DET_ELEVATION_022_Rx : 184|8@1+ (0.00275,-0.34925) [-0.34925|0.34925] "rad"  RDR05
 SG_ DET_ELEVATION_ERR_022_Rx : 192|6@1+ (0.00174533,0) [0|0.10995579] "rad"  RDR05
 SG_ DET_RCS_022_Rx : 240|8@1+ (0.5,-64) [-64|63.5] "dBsm"  RDR05
 SG_ DET_BI_STATIC_FLAG_022_Rx : 216|1@1+ (1,0) [0|1] ""  RDR05
 SG_ DET_SUPER_RES_TARGET_022_Rx : 199|1@1+ (1,0) [0|1] ""  RDR05
 SG_ DET_SNR_022_Rx : 232|8@1+ (0.35156,0) [0|89.6478] "dB"  RDR05
 SG_ DET_EXISTENCE_PROB_022_Rx : 224|6@1+ (1.588,0) [0|100] "%"  RDR05
 SG_ DET_HVC_FLAG_022_Rx : 198|1@1+ (1,0) [0|1] ""  RDR05
 SG_ DET_CONFD_AZIMUTH_022_Rx : 230|2@1+ (1,0) [0|3] ""  RDR05
 SG_ DET_CONFD_ELEVATION_022_Rx : 213|2@1+ (1,0) [0|3] ""  RDR05
 SG_ DET_PROB_1STAZHYPO_022_Rx : 215|1@1+ (1,0) [0|1] ""  RDR05
 SG_ DET_IDM_022_Rx : 175|1@1+ (1,0) [0|1] ""  RDR05
 SG_ DET_MTD_022_Rx : 159|1@1+ (1,0) [0|1] ""  RDR05
 SG_ DET_BELOW_RAIN_THOLD_022_Rx : 151|1@1+ (1,0) [0|1] ""  RDR05
 SG_ DET_RANGE_023_Rx : 248|15@1+ (0.015625,0) [0|500] "m"  RDR05
 SG_ DET_RANGE_ERR_023_Rx : 264|7@1+ (0.0075,0) [0|0.9525] "m"  RDR05
 SG_ DET_RANGE_VELOCITY_023_Rx : 272|15@1+ (0.0078125,-128) [-128|127.9921875] "m/s"  RDR05
 SG_ DET_RANGE_VELOCITY_ERR_023_Rx : 288|8@1+ (0.003,0) [0|0.765] "m/s"  RDR05
 SG_ DET_AZIMUTH_023_Rx : 312|13@1+ (0.0004,-1.5708) [-1.5708|1.5708] "rad"  RDR05
 SG_ DET_AZIMUTH_ERR_023_Rx : 329|7@1+ (0.00087267,0) [0|0.11082909] "rad"  RDR05
 SG_ DET_ELEVATION_023_Rx : 296|8@1+ (0.00275,-0.34925) [-0.34925|0.34925] "rad"  RDR05
 SG_ DET_ELEVATION_ERR_023_Rx : 304|6@1+ (0.00174533,0) [0|0.10995579] "rad"  RDR05
 SG_ DET_RCS_023_Rx : 352|8@1+ (0.5,-64) [-64|63.5] "dBsm"  RDR05
 SG_ DET_BI_STATIC_FLAG_023_Rx : 328|1@1+ (1,0) [0|1] ""  RDR05
 SG_ DET_SUPER_RES_TARGET_023_Rx : 311|1@1+ (1,0) [0|1] ""  RDR05
 SG_ DET_SNR_023_Rx : 344|8@1+ (0.35156,0) [0|89.6478] "dB"  RDR05
 SG_ DET_EXISTENCE_PROB_023_Rx : 336|6@1+ (1.588,0) [0|100] "%"  RDR05
 SG_ DET_HVC_FLAG_023_Rx : 310|1@1+ (1,0) [0|1] ""  RDR05
 SG_ DET_CONFD_AZIMUTH_023_Rx : 342|2@1+ (1,0) [0|3] ""  RDR05
 SG_ DET_CONFD_ELEVATION_023_Rx : 325|2@1+ (1,0) [0|3] ""  RDR05
 SG_ DET_PROB_1STAZHYPO_023_Rx : 327|1@1+ (1,0) [0|1] ""  RDR05
 SG_ DET_IDM_023_Rx : 287|1@1+ (1,0) [0|1] ""  RDR05
 SG_ DET_MTD_023_Rx : 271|1@1+ (1,0) [0|1] ""  RDR05
 SG_ DET_BELOW_RAIN_THOLD_023_Rx : 263|1@1+ (1,0) [0|1] ""  RDR05
 SG_ DET_RANGE_024_Rx : 360|15@1+ (0.015625,0) [0|500] "m"  RDR05
 SG_ DET_RANGE_ERR_024_Rx : 376|7@1+ (0.0075,0) [0|0.9525] "m"  RDR05
 SG_ DET_RANGE_VELOCITY_024_Rx : 384|15@1+ (0.0078125,-128) [-128|127.9921875] "m/s"  RDR05
 SG_ DET_RANGE_VELOCITY_ERR_024_Rx : 400|8@1+ (0.003,0) [0|0.765] "m/s"  RDR05
 SG_ DET_AZIMUTH_024_Rx : 424|13@1+ (0.0004,-1.5708) [-1.5708|1.5708] "rad"  RDR05
 SG_ DET_AZIMUTH_ERR_024_Rx : 441|7@1+ (0.00087267,0) [0|0.11082909] "rad"  RDR05
 SG_ DET_ELEVATION_024_Rx : 408|8@1+ (0.00275,-0.34925) [-0.34925|0.34925] "rad"  RDR05
 SG_ DET_ELEVATION_ERR_024_Rx : 416|6@1+ (0.00174533,0) [0|0.10995579] "rad"  RDR05
 SG_ DET_RCS_024_Rx : 464|8@1+ (0.5,-64) [-64|63.5] "dBsm"  RDR05
 SG_ DET_BI_STATIC_FLAG_024_Rx : 440|1@1+ (1,0) [0|1] ""  RDR05
 SG_ DET_SUPER_RES_TARGET_024_Rx : 423|1@1+ (1,0) [0|1] ""  RDR05
 SG_ DET_SNR_024_Rx : 456|8@1+ (0.35156,0) [0|89.6478] "dB"  RDR05
 SG_ DET_EXISTENCE_PROB_024_Rx : 448|6@1+ (1.588,0) [0|100] "%"  RDR05
 SG_ DET_HVC_FLAG_024_Rx : 422|1@1+ (1,0) [0|1] ""  RDR05
 SG_ DET_CONFD_AZIMUTH_024_Rx : 454|2@1+ (1,0) [0|3] ""  RDR05
 SG_ DET_CONFD_ELEVATION_024_Rx : 437|2@1+ (1,0) [0|3] ""  RDR05
 SG_ DET_MH_SCAN_INDEX_4LSB_021_024_R : 476|4@1+ (1,0) [0|15] ""  RDR05
 SG_ DET_MH_CYCLE_COUNTER_021_024_Rx : 16|8@1+ (1,0) [0|255] ""  RDR05
 SG_ DET_MH_CRC16_021_024_Rx : 0|16@1+ (1,0) [0|65535] ""  RDR05
 SG_ DET_PROB_1STAZHYPO_024_Rx : 439|1@1+ (1,0) [0|1] ""  RDR05
 SG_ DET_IDM_024_Rx : 399|1@1+ (1,0) [0|1] ""  RDR05
 SG_ DET_MTD_024_Rx : 383|1@1+ (1,0) [0|1] ""  RDR05
 SG_ DET_BELOW_RAIN_THOLD_024_Rx : 375|1@1+ (1,0) [0|1] ""  RDR05

BO_ 262 RDR_FUSION_DET_025_028: 64 RDR_Fusion_Partner
 SG_ DET_RANGE_025_Rx : 24|15@1+ (0.015625,0) [0|500] "m"  RDR05
 SG_ DET_RANGE_ERR_025_Rx : 40|7@1+ (0.0075,0) [0|0.9525] "m"  RDR05
 SG_ DET_RANGE_VELOCITY_025_Rx : 48|15@1+ (0.0078125,-128) [-128|127.9921875] "m/s"  RDR05
 SG_ DET_RANGE_VELOCITY_ERR_025_Rx : 64|8@1+ (0.003,0) [0|0.765] "m/s"  RDR05
 SG_ DET_AZIMUTH_025_Rx : 88|13@1+ (0.0004,-1.5708) [-1.5708|1.5708] "rad"  RDR05
 SG_ DET_AZIMUTH_ERR_025_Rx : 105|7@1+ (0.00087267,0) [0|0.11082909] "rad"  RDR05
 SG_ DET_ELEVATION_025_Rx : 72|8@1+ (0.00275,-0.34925) [-0.34925|0.34925] "rad"  RDR05
 SG_ DET_ELEVATION_ERR_025_Rx : 80|6@1+ (0.00174533,0) [0|0.10995579] "rad"  RDR05
 SG_ DET_RCS_025_Rx : 128|8@1+ (0.5,-64) [-64|63.5] "dBsm"  RDR05
 SG_ DET_BI_STATIC_FLAG_025_Rx : 104|1@1+ (1,0) [0|1] ""  RDR05
 SG_ DET_SUPER_RES_TARGET_025_Rx : 87|1@1+ (1,0) [0|1] ""  RDR05
 SG_ DET_SNR_025_Rx : 120|8@1+ (0.35156,0) [0|89.6478] "dB"  RDR05
 SG_ DET_EXISTENCE_PROB_025_Rx : 112|6@1+ (1.588,0) [0|100] "%"  RDR05
 SG_ DET_HVC_FLAG_025_Rx : 86|1@1+ (1,0) [0|1] ""  RDR05
 SG_ DET_CONFD_AZIMUTH_025_Rx : 118|2@1+ (1,0) [0|3] ""  RDR05
 SG_ DET_CONFD_ELEVATION_025_Rx : 101|2@1+ (1,0) [0|3] ""  RDR05
 SG_ DET_PROB_1STAZHYPO_025_Rx : 103|1@1+ (1,0) [0|1] ""  RDR05
 SG_ DET_IDM_025_Rx : 63|1@1+ (1,0) [0|1] ""  RDR05
 SG_ DET_MTD_025_Rx : 47|1@1+ (1,0) [0|1] ""  RDR05
 SG_ DET_BELOW_RAIN_THOLD_025_Rx : 39|1@1+ (1,0) [0|1] ""  RDR05
 SG_ DET_RANGE_026_Rx : 136|15@1+ (0.015625,0) [0|500] "m"  RDR05
 SG_ DET_RANGE_ERR_026_Rx : 152|7@1+ (0.0075,0) [0|0.9525] "m"  RDR05
 SG_ DET_RANGE_VELOCITY_026_Rx : 160|15@1+ (0.0078125,-128) [-128|127.9921875] "m/s"  RDR05
 SG_ DET_RANGE_VELOCITY_ERR_026_Rx : 176|8@1+ (0.003,0) [0|0.765] "m/s"  RDR05
 SG_ DET_AZIMUTH_026_Rx : 200|13@1+ (0.0004,-1.5708) [-1.5708|1.5708] "rad"  RDR05
 SG_ DET_AZIMUTH_ERR_026_Rx : 217|7@1+ (0.00087267,0) [0|0.11082909] "rad"  RDR05
 SG_ DET_ELEVATION_026_Rx : 184|8@1+ (0.00275,-0.34925) [-0.34925|0.34925] "rad"  RDR05
 SG_ DET_ELEVATION_ERR_026_Rx : 192|6@1+ (0.00174533,0) [0|0.10995579] "rad"  RDR05
 SG_ DET_RCS_026_Rx : 240|8@1+ (0.5,-64) [-64|63.5] "dBsm"  RDR05
 SG_ DET_BI_STATIC_FLAG_026_Rx : 216|1@1+ (1,0) [0|1] ""  RDR05
 SG_ DET_SUPER_RES_TARGET_026_Rx : 199|1@1+ (1,0) [0|1] ""  RDR05
 SG_ DET_SNR_026_Rx : 232|8@1+ (0.35156,0) [0|89.6478] "dB"  RDR05
 SG_ DET_EXISTENCE_PROB_026_Rx : 224|6@1+ (1.588,0) [0|100] "%"  RDR05
 SG_ DET_HVC_FLAG_026_Rx : 198|1@1+ (1,0) [0|1] ""  RDR05
 SG_ DET_CONFD_AZIMUTH_026_Rx : 230|2@1+ (1,0) [0|3] ""  RDR05
 SG_ DET_CONFD_ELEVATION_026_Rx : 213|2@1+ (1,0) [0|3] ""  RDR05
 SG_ DET_PROB_1STAZHYPO_026_Rx : 215|1@1+ (1,0) [0|1] ""  RDR05
 SG_ DET_IDM_026_Rx : 175|1@1+ (1,0) [0|1] ""  RDR05
 SG_ DET_MTD_026_Rx : 159|1@1+ (1,0) [0|1] ""  RDR05
 SG_ DET_BELOW_RAIN_THOLD_026_Rx : 151|1@1+ (1,0) [0|1] ""  RDR05
 SG_ DET_RANGE_027_Rx : 248|15@1+ (0.015625,0) [0|500] "m"  RDR05
 SG_ DET_RANGE_ERR_027_Rx : 264|7@1+ (0.0075,0) [0|0.9525] "m"  RDR05
 SG_ DET_RANGE_VELOCITY_027_Rx : 272|15@1+ (0.0078125,-128) [-128|127.9921875] "m/s"  RDR05
 SG_ DET_RANGE_VELOCITY_ERR_027_Rx : 288|8@1+ (0.003,0) [0|0.765] "m/s"  RDR05
 SG_ DET_AZIMUTH_027_Rx : 312|13@1+ (0.0004,-1.5708) [-1.5708|1.5708] "rad"  RDR05
 SG_ DET_AZIMUTH_ERR_027_Rx : 329|7@1+ (0.00087267,0) [0|0.11082909] "rad"  RDR05
 SG_ DET_ELEVATION_027_Rx : 296|8@1+ (0.00275,-0.34925) [-0.34925|0.34925] "rad"  RDR05
 SG_ DET_ELEVATION_ERR_027_Rx : 304|6@1+ (0.00174533,0) [0|0.10995579] "rad"  RDR05
 SG_ DET_RCS_027_Rx : 352|8@1+ (0.5,-64) [-64|63.5] "dBsm"  RDR05
 SG_ DET_BI_STATIC_FLAG_027_Rx : 328|1@1+ (1,0) [0|1] ""  RDR05
 SG_ DET_SUPER_RES_TARGET_027_Rx : 311|1@1+ (1,0) [0|1] ""  RDR05
 SG_ DET_SNR_027_Rx : 344|8@1+ (0.35156,0) [0|89.6478] "dB"  RDR05
 SG_ DET_EXISTENCE_PROB_027_Rx : 336|6@1+ (1.588,0) [0|100] "%"  RDR05
 SG_ DET_HVC_FLAG_027_Rx : 310|1@1+ (1,0) [0|1] ""  RDR05
 SG_ DET_CONFD_AZIMUTH_027_Rx : 342|2@1+ (1,0) [0|3] ""  RDR05
 SG_ DET_CONFD_ELEVATION_027_Rx : 325|2@1+ (1,0) [0|3] ""  RDR05
 SG_ DET_PROB_1STAZHYPO_027_Rx : 327|1@1+ (1,0) [0|1] ""  RDR05
 SG_ DET_IDM_027_Rx : 287|1@1+ (1,0) [0|1] ""  RDR05
 SG_ DET_MTD_027_Rx : 271|1@1+ (1,0) [0|1] ""  RDR05
 SG_ DET_BELOW_RAIN_THOLD_027_Rx : 263|1@1+ (1,0) [0|1] ""  RDR05
 SG_ DET_RANGE_028_Rx : 360|15@1+ (0.015625,0) [0|500] "m"  RDR05
 SG_ DET_RANGE_ERR_028_Rx : 376|7@1+ (0.0075,0) [0|0.9525] "m"  RDR05
 SG_ DET_RANGE_VELOCITY_028_Rx : 384|15@1+ (0.0078125,-128) [-128|127.9921875] "m/s"  RDR05
 SG_ DET_RANGE_VELOCITY_ERR_028_Rx : 400|8@1+ (0.003,0) [0|0.765] "m/s"  RDR05
 SG_ DET_AZIMUTH_028_Rx : 424|13@1+ (0.0004,-1.5708) [-1.5708|1.5708] "rad"  RDR05
 SG_ DET_AZIMUTH_ERR_028_Rx : 441|7@1+ (0.00087267,0) [0|0.11082909] "rad"  RDR05
 SG_ DET_ELEVATION_028_Rx : 408|8@1+ (0.00275,-0.34925) [-0.34925|0.34925] "rad"  RDR05
 SG_ DET_ELEVATION_ERR_028_Rx : 416|6@1+ (0.00174533,0) [0|0.10995579] "rad"  RDR05
 SG_ DET_RCS_028_Rx : 464|8@1+ (0.5,-64) [-64|63.5] "dBsm"  RDR05
 SG_ DET_BI_STATIC_FLAG_028_Rx : 440|1@1+ (1,0) [0|1] ""  RDR05
 SG_ DET_SUPER_RES_TARGET_028_Rx : 423|1@1+ (1,0) [0|1] ""  RDR05
 SG_ DET_SNR_028_Rx : 456|8@1+ (0.35156,0) [0|89.6478] "dB"  RDR05
 SG_ DET_EXISTENCE_PROB_028_Rx : 448|6@1+ (1.588,0) [0|100] "%"  RDR05
 SG_ DET_HVC_FLAG_028_Rx : 422|1@1+ (1,0) [0|1] ""  RDR05
 SG_ DET_CONFD_AZIMUTH_028_Rx : 454|2@1+ (1,0) [0|3] ""  RDR05
 SG_ DET_CONFD_ELEVATION_028_Rx : 437|2@1+ (1,0) [0|3] ""  RDR05
 SG_ DET_MH_SCAN_INDEX_4LSB_025_028_R : 476|4@1+ (1,0) [0|15] ""  RDR05
 SG_ DET_MH_CYCLE_COUNTER_025_028_Rx : 16|8@1+ (1,0) [0|255] ""  RDR05
 SG_ DET_MH_CRC16_025_028_Rx : 0|16@1+ (1,0) [0|65535] ""  RDR05
 SG_ DET_PROB_1STAZHYPO_028_Rx : 439|1@1+ (1,0) [0|1] ""  RDR05
 SG_ DET_IDM_028_Rx : 399|1@1+ (1,0) [0|1] ""  RDR05
 SG_ DET_MTD_028_Rx : 383|1@1+ (1,0) [0|1] ""  RDR05
 SG_ DET_BELOW_RAIN_THOLD_028_Rx : 375|1@1+ (1,0) [0|1] ""  RDR05

BO_ 263 RDR_FUSION_DET_029_032: 64 RDR_Fusion_Partner
 SG_ DET_RANGE_029_Rx : 24|15@1+ (0.015625,0) [0|500] "m"  RDR05
 SG_ DET_RANGE_ERR_029_Rx : 40|7@1+ (0.0075,0) [0|0.9525] "m"  RDR05
 SG_ DET_RANGE_VELOCITY_029_Rx : 48|15@1+ (0.0078125,-128) [-128|127.9921875] "m/s"  RDR05
 SG_ DET_RANGE_VELOCITY_ERR_029_Rx : 64|8@1+ (0.003,0) [0|0.765] "m/s"  RDR05
 SG_ DET_AZIMUTH_029_Rx : 88|13@1+ (0.0004,-1.5708) [-1.5708|1.5708] "rad"  RDR05
 SG_ DET_AZIMUTH_ERR_029_Rx : 105|7@1+ (0.00087267,0) [0|0.11082909] "rad"  RDR05
 SG_ DET_ELEVATION_029_Rx : 72|8@1+ (0.00275,-0.34925) [-0.34925|0.34925] "rad"  RDR05
 SG_ DET_ELEVATION_ERR_029_Rx : 80|6@1+ (0.00174533,0) [0|0.10995579] "rad"  RDR05
 SG_ DET_RCS_029_Rx : 128|8@1+ (0.5,-64) [-64|63.5] "dBsm"  RDR05
 SG_ DET_BI_STATIC_FLAG_029_Rx : 104|1@1+ (1,0) [0|1] ""  RDR05
 SG_ DET_SUPER_RES_TARGET_029_Rx : 87|1@1+ (1,0) [0|1] ""  RDR05
 SG_ DET_SNR_029_Rx : 120|8@1+ (0.35156,0) [0|89.6478] "dB"  RDR05
 SG_ DET_EXISTENCE_PROB_029_Rx : 112|6@1+ (1.588,0) [0|100] "%"  RDR05
 SG_ DET_HVC_FLAG_029_Rx : 86|1@1+ (1,0) [0|1] ""  RDR05
 SG_ DET_CONFD_AZIMUTH_029_Rx : 118|2@1+ (1,0) [0|3] ""  RDR05
 SG_ DET_CONFD_ELEVATION_029_Rx : 101|2@1+ (1,0) [0|3] ""  RDR05
 SG_ DET_PROB_1STAZHYPO_029_Rx : 103|1@1+ (1,0) [0|1] ""  RDR05
 SG_ DET_IDM_029_Rx : 63|1@1+ (1,0) [0|1] ""  RDR05
 SG_ DET_MTD_029_Rx : 47|1@1+ (1,0) [0|1] ""  RDR05
 SG_ DET_BELOW_RAIN_THOLD_029_Rx : 39|1@1+ (1,0) [0|1] ""  RDR05
 SG_ DET_RANGE_030_Rx : 136|15@1+ (0.015625,0) [0|500] "m"  RDR05
 SG_ DET_RANGE_ERR_030_Rx : 152|7@1+ (0.0075,0) [0|0.9525] "m"  RDR05
 SG_ DET_RANGE_VELOCITY_030_Rx : 160|15@1+ (0.0078125,-128) [-128|127.9921875] "m/s"  RDR05
 SG_ DET_RANGE_VELOCITY_ERR_030_Rx : 176|8@1+ (0.003,0) [0|0.765] "m/s"  RDR05
 SG_ DET_AZIMUTH_030_Rx : 200|13@1+ (0.0004,-1.5708) [-1.5708|1.5708] "rad"  RDR05
 SG_ DET_AZIMUTH_ERR_030_Rx : 217|7@1+ (0.00087267,0) [0|0.11082909] "rad"  RDR05
 SG_ DET_ELEVATION_030_Rx : 184|8@1+ (0.00275,-0.34925) [-0.34925|0.34925] "rad"  RDR05
 SG_ DET_ELEVATION_ERR_030_Rx : 192|6@1+ (0.00174533,0) [0|0.10995579] "rad"  RDR05
 SG_ DET_RCS_030_Rx : 240|8@1+ (0.5,-64) [-64|63.5] "dBsm"  RDR05
 SG_ DET_BI_STATIC_FLAG_030_Rx : 216|1@1+ (1,0) [0|1] ""  RDR05
 SG_ DET_SUPER_RES_TARGET_030_Rx : 199|1@1+ (1,0) [0|1] ""  RDR05
 SG_ DET_SNR_030_Rx : 232|8@1+ (0.35156,0) [0|89.6478] "dB"  RDR05
 SG_ DET_EXISTENCE_PROB_030_Rx : 224|6@1+ (1.588,0) [0|100] "%"  RDR05
 SG_ DET_HVC_FLAG_030_Rx : 198|1@1+ (1,0) [0|1] ""  RDR05
 SG_ DET_CONFD_AZIMUTH_030_Rx : 230|2@1+ (1,0) [0|3] ""  RDR05
 SG_ DET_CONFD_ELEVATION_030_Rx : 213|2@1+ (1,0) [0|3] ""  RDR05
 SG_ DET_PROB_1STAZHYPO_030_Rx : 215|1@1+ (1,0) [0|1] ""  RDR05
 SG_ DET_IDM_030_Rx : 175|1@1+ (1,0) [0|1] ""  RDR05
 SG_ DET_MTD_030_Rx : 159|1@1+ (1,0) [0|1] ""  RDR05
 SG_ DET_BELOW_RAIN_THOLD_030_Rx : 151|1@1+ (1,0) [0|1] ""  RDR05
 SG_ DET_RANGE_031_Rx : 248|15@1+ (0.015625,0) [0|500] "m"  RDR05
 SG_ DET_RANGE_ERR_031_Rx : 264|7@1+ (0.0075,0) [0|0.9525] "m"  RDR05
 SG_ DET_RANGE_VELOCITY_031_Rx : 272|15@1+ (0.0078125,-128) [-128|127.9921875] "m/s"  RDR05
 SG_ DET_RANGE_VELOCITY_ERR_031_Rx : 288|8@1+ (0.003,0) [0|0.765] "m/s"  RDR05
 SG_ DET_AZIMUTH_031_Rx : 312|13@1+ (0.0004,-1.5708) [-1.5708|1.5708] "rad"  RDR05
 SG_ DET_AZIMUTH_ERR_031_Rx : 329|7@1+ (0.00087267,0) [0|0.11082909] "rad"  RDR05
 SG_ DET_ELEVATION_031_Rx : 296|8@1+ (0.00275,-0.34925) [-0.34925|0.34925] "rad"  RDR05
 SG_ DET_ELEVATION_ERR_031_Rx : 304|6@1+ (0.00174533,0) [0|0.10995579] "rad"  RDR05
 SG_ DET_RCS_031_Rx : 352|8@1+ (0.5,-64) [-64|63.5] "dBsm"  RDR05
 SG_ DET_BI_STATIC_FLAG_031_Rx : 328|1@1+ (1,0) [0|1] ""  RDR05
 SG_ DET_SUPER_RES_TARGET_031_Rx : 311|1@1+ (1,0) [0|1] ""  RDR05
 SG_ DET_SNR_031_Rx : 344|8@1+ (0.35156,0) [0|89.6478] "dB"  RDR05
 SG_ DET_EXISTENCE_PROB_031_Rx : 336|6@1+ (1.588,0) [0|100] "%"  RDR05
 SG_ DET_HVC_FLAG_031_Rx : 310|1@1+ (1,0) [0|1] ""  RDR05
 SG_ DET_CONFD_AZIMUTH_031_Rx : 342|2@1+ (1,0) [0|3] ""  RDR05
 SG_ DET_CONFD_ELEVATION_031_Rx : 325|2@1+ (1,0) [0|3] ""  RDR05
 SG_ DET_PROB_1STAZHYPO_031_Rx : 327|1@1+ (1,0) [0|1] ""  RDR05
 SG_ DET_IDM_031_Rx : 287|1@1+ (1,0) [0|1] ""  RDR05
 SG_ DET_MTD_031_Rx : 271|1@1+ (1,0) [0|1] ""  RDR05
 SG_ DET_BELOW_RAIN_THOLD_031_Rx : 263|1@1+ (1,0) [0|1] ""  RDR05
 SG_ DET_RANGE_032_Rx : 360|15@1+ (0.015625,0) [0|500] "m"  RDR05
 SG_ DET_RANGE_ERR_032_Rx : 376|7@1+ (0.0075,0) [0|0.9525] "m"  RDR05
 SG_ DET_RANGE_VELOCITY_032_Rx : 384|15@1+ (0.0078125,-128) [-128|127.9921875] "m/s"  RDR05
 SG_ DET_RANGE_VELOCITY_ERR_032_Rx : 400|8@1+ (0.003,0) [0|0.765] "m/s"  RDR05
 SG_ DET_AZIMUTH_032_Rx : 424|13@1+ (0.0004,-1.5708) [-1.5708|1.5708] "rad"  RDR05
 SG_ DET_AZIMUTH_ERR_032_Rx : 441|7@1+ (0.00087267,0) [0|0.11082909] "rad"  RDR05
 SG_ DET_ELEVATION_032_Rx : 408|8@1+ (0.00275,-0.34925) [-0.34925|0.34925] "rad"  RDR05
 SG_ DET_ELEVATION_ERR_032_Rx : 416|6@1+ (0.00174533,0) [0|0.10995579] "rad"  RDR05
 SG_ DET_RCS_032_Rx : 464|8@1+ (0.5,-64) [-64|63.5] "dBsm"  RDR05
 SG_ DET_BI_STATIC_FLAG_032_Rx : 440|1@1+ (1,0) [0|1] ""  RDR05
 SG_ DET_SUPER_RES_TARGET_032_Rx : 423|1@1+ (1,0) [0|1] ""  RDR05
 SG_ DET_SNR_032_Rx : 456|8@1+ (0.35156,0) [0|89.6478] "dB"  RDR05
 SG_ DET_EXISTENCE_PROB_032_Rx : 448|6@1+ (1.588,0) [0|100] "%"  RDR05
 SG_ DET_HVC_FLAG_032_Rx : 422|1@1+ (1,0) [0|1] ""  RDR05
 SG_ DET_CONFD_AZIMUTH_032_Rx : 454|2@1+ (1,0) [0|3] ""  RDR05
 SG_ DET_CONFD_ELEVATION_032_Rx : 437|2@1+ (1,0) [0|3] ""  RDR05
 SG_ DET_MH_SCAN_INDEX_4LSB_029_032_R : 476|4@1+ (1,0) [0|15] ""  RDR05
 SG_ DET_MH_CYCLE_COUNTER_029_032_Rx : 16|8@1+ (1,0) [0|255] ""  RDR05
 SG_ DET_MH_CRC16_029_032_Rx : 0|16@1+ (1,0) [0|65535] ""  RDR05
 SG_ DET_PROB_1STAZHYPO_032_Rx : 439|1@1+ (1,0) [0|1] ""  RDR05
 SG_ DET_IDM_032_Rx : 399|1@1+ (1,0) [0|1] ""  RDR05
 SG_ DET_MTD_032_Rx : 383|1@1+ (1,0) [0|1] ""  RDR05
 SG_ DET_BELOW_RAIN_THOLD_032_Rx : 375|1@1+ (1,0) [0|1] ""  RDR05

BO_ 264 RDR_FUSION_DET_033_036: 64 RDR_Fusion_Partner
 SG_ DET_RANGE_033_Rx : 24|15@1+ (0.015625,0) [0|500] "m"  RDR05
 SG_ DET_RANGE_ERR_033_Rx : 40|7@1+ (0.0075,0) [0|0.9525] "m"  RDR05
 SG_ DET_RANGE_VELOCITY_033_Rx : 48|15@1+ (0.0078125,-128) [-128|127.9921875] "m/s"  RDR05
 SG_ DET_RANGE_VELOCITY_ERR_033_Rx : 64|8@1+ (0.003,0) [0|0.765] "m/s"  RDR05
 SG_ DET_AZIMUTH_033_Rx : 88|13@1+ (0.0004,-1.5708) [-1.5708|1.5708] "rad"  RDR05
 SG_ DET_AZIMUTH_ERR_033_Rx : 105|7@1+ (0.00087267,0) [0|0.11082909] "rad"  RDR05
 SG_ DET_ELEVATION_033_Rx : 72|8@1+ (0.00275,-0.34925) [-0.34925|0.34925] "rad"  RDR05
 SG_ DET_ELEVATION_ERR_033_Rx : 80|6@1+ (0.00174533,0) [0|0.10995579] "rad"  RDR05
 SG_ DET_RCS_033_Rx : 128|8@1+ (0.5,-64) [-64|63.5] "dBsm"  RDR05
 SG_ DET_BI_STATIC_FLAG_033_Rx : 104|1@1+ (1,0) [0|1] ""  RDR05
 SG_ DET_SUPER_RES_TARGET_033_Rx : 87|1@1+ (1,0) [0|1] ""  RDR05
 SG_ DET_SNR_033_Rx : 120|8@1+ (0.35156,0) [0|89.6478] "dB"  RDR05
 SG_ DET_EXISTENCE_PROB_033_Rx : 112|6@1+ (1.588,0) [0|100] "%"  RDR05
 SG_ DET_HVC_FLAG_033_Rx : 86|1@1+ (1,0) [0|1] ""  RDR05
 SG_ DET_CONFD_AZIMUTH_033_Rx : 118|2@1+ (1,0) [0|3] ""  RDR05
 SG_ DET_CONFD_ELEVATION_033_Rx : 101|2@1+ (1,0) [0|3] ""  RDR05
 SG_ DET_PROB_1STAZHYPO_033_Rx : 103|1@1+ (1,0) [0|1] ""  RDR05
 SG_ DET_IDM_033_Rx : 63|1@1+ (1,0) [0|1] ""  RDR05
 SG_ DET_MTD_033_Rx : 47|1@1+ (1,0) [0|1] ""  RDR05
 SG_ DET_BELOW_RAIN_THOLD_033_Rx : 39|1@1+ (1,0) [0|1] ""  RDR05
 SG_ DET_RANGE_034_Rx : 136|15@1+ (0.015625,0) [0|500] "m"  RDR05
 SG_ DET_RANGE_ERR_034_Rx : 152|7@1+ (0.0075,0) [0|0.9525] "m"  RDR05
 SG_ DET_RANGE_VELOCITY_034_Rx : 160|15@1+ (0.0078125,-128) [-128|127.9921875] "m/s"  RDR05
 SG_ DET_RANGE_VELOCITY_ERR_034_Rx : 176|8@1+ (0.003,0) [0|0.765] "m/s"  RDR05
 SG_ DET_AZIMUTH_034_Rx : 200|13@1+ (0.0004,-1.5708) [-1.5708|1.5708] "rad"  RDR05
 SG_ DET_AZIMUTH_ERR_034_Rx : 217|7@1+ (0.00087267,0) [0|0.11082909] "rad"  RDR05
 SG_ DET_ELEVATION_034_Rx : 184|8@1+ (0.00275,-0.34925) [-0.34925|0.34925] "rad"  RDR05
 SG_ DET_ELEVATION_ERR_034_Rx : 192|6@1+ (0.00174533,0) [0|0.10995579] "rad"  RDR05
 SG_ DET_RCS_034_Rx : 240|8@1+ (0.5,-64) [-64|63.5] "dBsm"  RDR05
 SG_ DET_BI_STATIC_FLAG_034_Rx : 216|1@1+ (1,0) [0|1] ""  RDR05
 SG_ DET_SUPER_RES_TARGET_034_Rx : 199|1@1+ (1,0) [0|1] ""  RDR05
 SG_ DET_SNR_034_Rx : 232|8@1+ (0.35156,0) [0|89.6478] "dB"  RDR05
 SG_ DET_EXISTENCE_PROB_034_Rx : 224|6@1+ (1.588,0) [0|100] "%"  RDR05
 SG_ DET_HVC_FLAG_034_Rx : 198|1@1+ (1,0) [0|1] ""  RDR05
 SG_ DET_CONFD_AZIMUTH_034_Rx : 230|2@1+ (1,0) [0|3] ""  RDR05
 SG_ DET_CONFD_ELEVATION_034_Rx : 213|2@1+ (1,0) [0|3] ""  RDR05
 SG_ DET_PROB_1STAZHYPO_034_Rx : 215|1@1+ (1,0) [0|1] ""  RDR05
 SG_ DET_IDM_034_Rx : 175|1@1+ (1,0) [0|1] ""  RDR05
 SG_ DET_MTD_034_Rx : 159|1@1+ (1,0) [0|1] ""  RDR05
 SG_ DET_BELOW_RAIN_THOLD_034_Rx : 151|1@1+ (1,0) [0|1] ""  RDR05
 SG_ DET_RANGE_035_Rx : 248|15@1+ (0.015625,0) [0|500] "m"  RDR05
 SG_ DET_RANGE_ERR_035_Rx : 264|7@1+ (0.0075,0) [0|0.9525] "m"  RDR05
 SG_ DET_RANGE_VELOCITY_035_Rx : 272|15@1+ (0.0078125,-128) [-128|127.9921875] "m/s"  RDR05
 SG_ DET_RANGE_VELOCITY_ERR_035_Rx : 288|8@1+ (0.003,0) [0|0.765] "m/s"  RDR05
 SG_ DET_AZIMUTH_035_Rx : 312|13@1+ (0.0004,-1.5708) [-1.5708|1.5708] "rad"  RDR05
 SG_ DET_AZIMUTH_ERR_035_Rx : 329|7@1+ (0.00087267,0) [0|0.11082909] "rad"  RDR05
 SG_ DET_ELEVATION_035_Rx : 296|8@1+ (0.00275,-0.34925) [-0.34925|0.34925] "rad"  RDR05
 SG_ DET_ELEVATION_ERR_035_Rx : 304|6@1+ (0.00174533,0) [0|0.10995579] "rad"  RDR05
 SG_ DET_RCS_035_Rx : 352|8@1+ (0.5,-64) [-64|63.5] "dBsm"  RDR05
 SG_ DET_BI_STATIC_FLAG_035_Rx : 328|1@1+ (1,0) [0|1] ""  RDR05
 SG_ DET_SUPER_RES_TARGET_035_Rx : 311|1@1+ (1,0) [0|1] ""  RDR05
 SG_ DET_SNR_035_Rx : 344|8@1+ (0.35156,0) [0|89.6478] "dB"  RDR05
 SG_ DET_EXISTENCE_PROB_035_Rx : 336|6@1+ (1.588,0) [0|100] "%"  RDR05
 SG_ DET_HVC_FLAG_035_Rx : 310|1@1+ (1,0) [0|1] ""  RDR05
 SG_ DET_CONFD_AZIMUTH_035_Rx : 342|2@1+ (1,0) [0|3] ""  RDR05
 SG_ DET_CONFD_ELEVATION_035_Rx : 325|2@1+ (1,0) [0|3] ""  RDR05
 SG_ DET_PROB_1STAZHYPO_035_Rx : 327|1@1+ (1,0) [0|1] ""  RDR05
 SG_ DET_IDM_035_Rx : 287|1@1+ (1,0) [0|1] ""  RDR05
 SG_ DET_MTD_035_Rx : 271|1@1+ (1,0) [0|1] ""  RDR05
 SG_ DET_BELOW_RAIN_THOLD_035_Rx : 263|1@1+ (1,0) [0|1] ""  RDR05
 SG_ DET_RANGE_036_Rx : 360|15@1+ (0.015625,0) [0|500] "m"  RDR05
 SG_ DET_RANGE_ERR_036_Rx : 376|7@1+ (0.0075,0) [0|0.9525] "m"  RDR05
 SG_ DET_RANGE_VELOCITY_036_Rx : 384|15@1+ (0.0078125,-128) [-128|127.9921875] "m/s"  RDR05
 SG_ DET_RANGE_VELOCITY_ERR_036_Rx : 400|8@1+ (0.003,0) [0|0.765] "m/s"  RDR05
 SG_ DET_AZIMUTH_036_Rx : 424|13@1+ (0.0004,-1.5708) [-1.5708|1.5708] "rad"  RDR05
 SG_ DET_AZIMUTH_ERR_036_Rx : 441|7@1+ (0.00087267,0) [0|0.11082909] "rad"  RDR05
 SG_ DET_ELEVATION_036_Rx : 408|8@1+ (0.00275,-0.34925) [-0.34925|0.34925] "rad"  RDR05
 SG_ DET_ELEVATION_ERR_036_Rx : 416|6@1+ (0.00174533,0) [0|0.10995579] "rad"  RDR05
 SG_ DET_RCS_036_Rx : 464|8@1+ (0.5,-64) [-64|63.5] "dBsm"  RDR05
 SG_ DET_BI_STATIC_FLAG_036_Rx : 440|1@1+ (1,0) [0|1] ""  RDR05
 SG_ DET_SUPER_RES_TARGET_036_Rx : 423|1@1+ (1,0) [0|1] ""  RDR05
 SG_ DET_SNR_036_Rx : 456|8@1+ (0.35156,0) [0|89.6478] "dB"  RDR05
 SG_ DET_EXISTENCE_PROB_036_Rx : 448|6@1+ (1.588,0) [0|100] "%"  RDR05
 SG_ DET_HVC_FLAG_036_Rx : 422|1@1+ (1,0) [0|1] ""  RDR05
 SG_ DET_CONFD_AZIMUTH_036_Rx : 454|2@1+ (1,0) [0|3] ""  RDR05
 SG_ DET_CONFD_ELEVATION_036_Rx : 437|2@1+ (1,0) [0|3] ""  RDR05
 SG_ DET_MH_SCAN_INDEX_4LSB_033_036_R : 476|4@1+ (1,0) [0|15] ""  RDR05
 SG_ DET_MH_CYCLE_COUNTER_033_036_Rx : 16|8@1+ (1,0) [0|255] ""  RDR05
 SG_ DET_MH_CRC16_033_036_Rx : 0|16@1+ (1,0) [0|65535] ""  RDR05
 SG_ DET_PROB_1STAZHYPO_036_Rx : 439|1@1+ (1,0) [0|1] ""  RDR05
 SG_ DET_IDM_036_Rx : 399|1@1+ (1,0) [0|1] ""  RDR05
 SG_ DET_MTD_036_Rx : 383|1@1+ (1,0) [0|1] ""  RDR05
 SG_ DET_BELOW_RAIN_THOLD_036_Rx : 375|1@1+ (1,0) [0|1] ""  RDR05

BO_ 265 RDR_FUSION_DET_037_040: 64 RDR_Fusion_Partner
 SG_ DET_RANGE_037_Rx : 24|15@1+ (0.015625,0) [0|500] "m"  RDR05
 SG_ DET_RANGE_ERR_037_Rx : 40|7@1+ (0.0075,0) [0|0.9525] "m"  RDR05
 SG_ DET_RANGE_VELOCITY_037_Rx : 48|15@1+ (0.0078125,-128) [-128|127.9921875] "m/s"  RDR05
 SG_ DET_RANGE_VELOCITY_ERR_037_Rx : 64|8@1+ (0.003,0) [0|0.765] "m/s"  RDR05
 SG_ DET_AZIMUTH_037_Rx : 88|13@1+ (0.0004,-1.5708) [-1.5708|1.5708] "rad"  RDR05
 SG_ DET_AZIMUTH_ERR_037_Rx : 105|7@1+ (0.00087267,0) [0|0.11082909] "rad"  RDR05
 SG_ DET_ELEVATION_037_Rx : 72|8@1+ (0.00275,-0.34925) [-0.34925|0.34925] "rad"  RDR05
 SG_ DET_ELEVATION_ERR_037_Rx : 80|6@1+ (0.00174533,0) [0|0.10995579] "rad"  RDR05
 SG_ DET_RCS_037_Rx : 128|8@1+ (0.5,-64) [-64|63.5] "dBsm"  RDR05
 SG_ DET_BI_STATIC_FLAG_037_Rx : 104|1@1+ (1,0) [0|1] ""  RDR05
 SG_ DET_SUPER_RES_TARGET_037_Rx : 87|1@1+ (1,0) [0|1] ""  RDR05
 SG_ DET_SNR_037_Rx : 120|8@1+ (0.35156,0) [0|89.6478] "dB"  RDR05
 SG_ DET_EXISTENCE_PROB_037_Rx : 112|6@1+ (1.588,0) [0|100] "%"  RDR05
 SG_ DET_HVC_FLAG_037_Rx : 86|1@1+ (1,0) [0|1] ""  RDR05
 SG_ DET_CONFD_AZIMUTH_037_Rx : 118|2@1+ (1,0) [0|3] ""  RDR05
 SG_ DET_CONFD_ELEVATION_037_Rx : 101|2@1+ (1,0) [0|3] ""  RDR05
 SG_ DET_PROB_1STAZHYPO_037_Rx : 103|1@1+ (1,0) [0|1] ""  RDR05
 SG_ DET_IDM_037_Rx : 63|1@1+ (1,0) [0|1] ""  RDR05
 SG_ DET_MTD_037_Rx : 47|1@1+ (1,0) [0|1] ""  RDR05
 SG_ DET_BELOW_RAIN_THOLD_037_Rx : 39|1@1+ (1,0) [0|1] ""  RDR05
 SG_ DET_RANGE_038_Rx : 136|15@1+ (0.015625,0) [0|500] "m"  RDR05
 SG_ DET_RANGE_ERR_038_Rx : 152|7@1+ (0.0075,0) [0|0.9525] "m"  RDR05
 SG_ DET_RANGE_VELOCITY_038_Rx : 160|15@1+ (0.0078125,-128) [-128|127.9921875] "m/s"  RDR05
 SG_ DET_RANGE_VELOCITY_ERR_038_Rx : 176|8@1+ (0.003,0) [0|0.765] "m/s"  RDR05
 SG_ DET_AZIMUTH_038_Rx : 200|13@1+ (0.0004,-1.5708) [-1.5708|1.5708] "rad"  RDR05
 SG_ DET_AZIMUTH_ERR_038_Rx : 217|7@1+ (0.00087267,0) [0|0.11082909] "rad"  RDR05
 SG_ DET_ELEVATION_038_Rx : 184|8@1+ (0.00275,-0.34925) [-0.34925|0.34925] "rad"  RDR05
 SG_ DET_ELEVATION_ERR_038_Rx : 192|6@1+ (0.00174533,0) [0|0.10995579] "rad"  RDR05
 SG_ DET_RCS_038_Rx : 240|8@1+ (0.5,-64) [-64|63.5] "dBsm"  RDR05
 SG_ DET_BI_STATIC_FLAG_038_Rx : 216|1@1+ (1,0) [0|1] ""  RDR05
 SG_ DET_SUPER_RES_TARGET_038_Rx : 199|1@1+ (1,0) [0|1] ""  RDR05
 SG_ DET_SNR_038_Rx : 232|8@1+ (0.35156,0) [0|89.6478] "dB"  RDR05
 SG_ DET_EXISTENCE_PROB_038_Rx : 224|6@1+ (1.588,0) [0|100] "%"  RDR05
 SG_ DET_HVC_FLAG_038_Rx : 198|1@1+ (1,0) [0|1] ""  RDR05
 SG_ DET_CONFD_AZIMUTH_038_Rx : 230|2@1+ (1,0) [0|3] ""  RDR05
 SG_ DET_CONFD_ELEVATION_038_Rx : 213|2@1+ (1,0) [0|3] ""  RDR05
 SG_ DET_PROB_1STAZHYPO_038_Rx : 215|1@1+ (1,0) [0|1] ""  RDR05
 SG_ DET_IDM_038_Rx : 175|1@1+ (1,0) [0|1] ""  RDR05
 SG_ DET_MTD_038_Rx : 159|1@1+ (1,0) [0|1] ""  RDR05
 SG_ DET_BELOW_RAIN_THOLD_038_Rx : 151|1@1+ (1,0) [0|1] ""  RDR05
 SG_ DET_RANGE_039_Rx : 248|15@1+ (0.015625,0) [0|500] "m"  RDR05
 SG_ DET_RANGE_ERR_039_Rx : 264|7@1+ (0.0075,0) [0|0.9525] "m"  RDR05
 SG_ DET_RANGE_VELOCITY_039_Rx : 272|15@1+ (0.0078125,-128) [-128|127.9921875] "m/s"  RDR05
 SG_ DET_RANGE_VELOCITY_ERR_039_Rx : 288|8@1+ (0.003,0) [0|0.765] "m/s"  RDR05
 SG_ DET_AZIMUTH_039_Rx : 312|13@1+ (0.0004,-1.5708) [-1.5708|1.5708] "rad"  RDR05
 SG_ DET_AZIMUTH_ERR_039_Rx : 329|7@1+ (0.00087267,0) [0|0.11082909] "rad"  RDR05
 SG_ DET_ELEVATION_039_Rx : 296|8@1+ (0.00275,-0.34925) [-0.34925|0.34925] "rad"  RDR05
 SG_ DET_ELEVATION_ERR_039_Rx : 304|6@1+ (0.00174533,0) [0|0.10995579] "rad"  RDR05
 SG_ DET_RCS_039_Rx : 352|8@1+ (0.5,-64) [-64|63.5] "dBsm"  RDR05
 SG_ DET_BI_STATIC_FLAG_039_Rx : 328|1@1+ (1,0) [0|1] ""  RDR05
 SG_ DET_SUPER_RES_TARGET_039_Rx : 311|1@1+ (1,0) [0|1] ""  RDR05
 SG_ DET_SNR_039_Rx : 344|8@1+ (0.35156,0) [0|89.6478] "dB"  RDR05
 SG_ DET_EXISTENCE_PROB_039_Rx : 336|6@1+ (1.588,0) [0|100] "%"  RDR05
 SG_ DET_HVC_FLAG_039_Rx : 310|1@1+ (1,0) [0|1] ""  RDR05
 SG_ DET_CONFD_AZIMUTH_039_Rx : 342|2@1+ (1,0) [0|3] ""  RDR05
 SG_ DET_CONFD_ELEVATION_039_Rx : 325|2@1+ (1,0) [0|3] ""  RDR05
 SG_ DET_PROB_1STAZHYPO_039_Rx : 327|1@1+ (1,0) [0|1] ""  RDR05
 SG_ DET_IDM_039_Rx : 287|1@1+ (1,0) [0|1] ""  RDR05
 SG_ DET_MTD_039_Rx : 271|1@1+ (1,0) [0|1] ""  RDR05
 SG_ DET_BELOW_RAIN_THOLD_039_Rx : 263|1@1+ (1,0) [0|1] ""  RDR05
 SG_ DET_RANGE_040_Rx : 360|15@1+ (0.015625,0) [0|500] "m"  RDR05
 SG_ DET_RANGE_ERR_040_Rx : 376|7@1+ (0.0075,0) [0|0.9525] "m"  RDR05
 SG_ DET_RANGE_VELOCITY_040_Rx : 384|15@1+ (0.0078125,-128) [-128|127.9921875] "m/s"  RDR05
 SG_ DET_RANGE_VELOCITY_ERR_040_Rx : 400|8@1+ (0.003,0) [0|0.765] "m/s"  RDR05
 SG_ DET_AZIMUTH_040_Rx : 424|13@1+ (0.0004,-1.5708) [-1.5708|1.5708] "rad"  RDR05
 SG_ DET_AZIMUTH_ERR_040_Rx : 441|7@1+ (0.00087267,0) [0|0.11082909] "rad"  RDR05
 SG_ DET_ELEVATION_040_Rx : 408|8@1+ (0.00275,-0.34925) [-0.34925|0.34925] "rad"  RDR05
 SG_ DET_ELEVATION_ERR_040_Rx : 416|6@1+ (0.00174533,0) [0|0.10995579] "rad"  RDR05
 SG_ DET_RCS_040_Rx : 464|8@1+ (0.5,-64) [-64|63.5] "dBsm"  RDR05
 SG_ DET_BI_STATIC_FLAG_040_Rx : 440|1@1+ (1,0) [0|1] ""  RDR05
 SG_ DET_SUPER_RES_TARGET_040_Rx : 423|1@1+ (1,0) [0|1] ""  RDR05
 SG_ DET_SNR_040_Rx : 456|8@1+ (0.35156,0) [0|89.6478] "dB"  RDR05
 SG_ DET_EXISTENCE_PROB_040_Rx : 448|6@1+ (1.588,0) [0|100] "%"  RDR05
 SG_ DET_HVC_FLAG_040_Rx : 422|1@1+ (1,0) [0|1] ""  RDR05
 SG_ DET_CONFD_AZIMUTH_040_Rx : 454|2@1+ (1,0) [0|3] ""  RDR05
 SG_ DET_CONFD_ELEVATION_040_Rx : 437|2@1+ (1,0) [0|3] ""  RDR05
 SG_ DET_MH_SCAN_INDEX_4LSB_037_040_R : 476|4@1+ (1,0) [0|15] ""  RDR05
 SG_ DET_MH_CYCLE_COUNTER_037_040_Rx : 16|8@1+ (1,0) [0|255] ""  RDR05
 SG_ DET_MH_CRC16_037_040_Rx : 0|16@1+ (1,0) [0|65535] ""  RDR05
 SG_ DET_PROB_1STAZHYPO_040_Rx : 439|1@1+ (1,0) [0|1] ""  RDR05
 SG_ DET_IDM_040_Rx : 399|1@1+ (1,0) [0|1] ""  RDR05
 SG_ DET_MTD_040_Rx : 383|1@1+ (1,0) [0|1] ""  RDR05
 SG_ DET_BELOW_RAIN_THOLD_040_Rx : 375|1@1+ (1,0) [0|1] ""  RDR05

BO_ 266 RDR_FUSION_DET_041_044: 64 RDR_Fusion_Partner
 SG_ DET_RANGE_041_Rx : 24|15@1+ (0.015625,0) [0|500] "m"  RDR05
 SG_ DET_RANGE_ERR_041_Rx : 40|7@1+ (0.0075,0) [0|0.9525] "m"  RDR05
 SG_ DET_RANGE_VELOCITY_041_Rx : 48|15@1+ (0.0078125,-128) [-128|127.9921875] "m/s"  RDR05
 SG_ DET_RANGE_VELOCITY_ERR_041_Rx : 64|8@1+ (0.003,0) [0|0.765] "m/s"  RDR05
 SG_ DET_AZIMUTH_041_Rx : 88|13@1+ (0.0004,-1.5708) [-1.5708|1.5708] "rad"  RDR05
 SG_ DET_AZIMUTH_ERR_041_Rx : 105|7@1+ (0.00087267,0) [0|0.11082909] "rad"  RDR05
 SG_ DET_ELEVATION_041_Rx : 72|8@1+ (0.00275,-0.34925) [-0.34925|0.34925] "rad"  RDR05
 SG_ DET_ELEVATION_ERR_041_Rx : 80|6@1+ (0.00174533,0) [0|0.10995579] "rad"  RDR05
 SG_ DET_RCS_041_Rx : 128|8@1+ (0.5,-64) [-64|63.5] "dBsm"  RDR05
 SG_ DET_BI_STATIC_FLAG_041_Rx : 104|1@1+ (1,0) [0|1] ""  RDR05
 SG_ DET_SUPER_RES_TARGET_041_Rx : 87|1@1+ (1,0) [0|1] ""  RDR05
 SG_ DET_SNR_041_Rx : 120|8@1+ (0.35156,0) [0|89.6478] "dB"  RDR05
 SG_ DET_EXISTENCE_PROB_041_Rx : 112|6@1+ (1.588,0) [0|100] "%"  RDR05
 SG_ DET_HVC_FLAG_041_Rx : 86|1@1+ (1,0) [0|1] ""  RDR05
 SG_ DET_CONFD_AZIMUTH_041_Rx : 118|2@1+ (1,0) [0|3] ""  RDR05
 SG_ DET_CONFD_ELEVATION_041_Rx : 101|2@1+ (1,0) [0|3] ""  RDR05
 SG_ DET_PROB_1STAZHYPO_041_Rx : 103|1@1+ (1,0) [0|1] ""  RDR05
 SG_ DET_IDM_041_Rx : 63|1@1+ (1,0) [0|1] ""  RDR05
 SG_ DET_MTD_041_Rx : 47|1@1+ (1,0) [0|1] ""  RDR05
 SG_ DET_BELOW_RAIN_THOLD_041_Rx : 39|1@1+ (1,0) [0|1] ""  RDR05
 SG_ DET_RANGE_042_Rx : 136|15@1+ (0.015625,0) [0|500] "m"  RDR05
 SG_ DET_RANGE_ERR_042_Rx : 152|7@1+ (0.0075,0) [0|0.9525] "m"  RDR05
 SG_ DET_RANGE_VELOCITY_042_Rx : 160|15@1+ (0.0078125,-128) [-128|127.9921875] "m/s"  RDR05
 SG_ DET_RANGE_VELOCITY_ERR_042_Rx : 176|8@1+ (0.003,0) [0|0.765] "m/s"  RDR05
 SG_ DET_AZIMUTH_042_Rx : 200|13@1+ (0.0004,-1.5708) [-1.5708|1.5708] "rad"  RDR05
 SG_ DET_AZIMUTH_ERR_042_Rx : 217|7@1+ (0.00087267,0) [0|0.11082909] "rad"  RDR05
 SG_ DET_ELEVATION_042_Rx : 184|8@1+ (0.00275,-0.34925) [-0.34925|0.34925] "rad"  RDR05
 SG_ DET_ELEVATION_ERR_042_Rx : 192|6@1+ (0.00174533,0) [0|0.10995579] "rad"  RDR05
 SG_ DET_RCS_042_Rx : 240|8@1+ (0.5,-64) [-64|63.5] "dBsm"  RDR05
 SG_ DET_BI_STATIC_FLAG_042_Rx : 216|1@1+ (1,0) [0|1] ""  RDR05
 SG_ DET_SUPER_RES_TARGET_042_Rx : 199|1@1+ (1,0) [0|1] ""  RDR05
 SG_ DET_SNR_042_Rx : 232|8@1+ (0.35156,0) [0|89.6478] "dB"  RDR05
 SG_ DET_EXISTENCE_PROB_042_Rx : 224|6@1+ (1.588,0) [0|100] "%"  RDR05
 SG_ DET_HVC_FLAG_042_Rx : 198|1@1+ (1,0) [0|1] ""  RDR05
 SG_ DET_CONFD_AZIMUTH_042_Rx : 230|2@1+ (1,0) [0|3] ""  RDR05
 SG_ DET_CONFD_ELEVATION_042_Rx : 213|2@1+ (1,0) [0|3] ""  RDR05
 SG_ DET_PROB_1STAZHYPO_042_Rx : 215|1@1+ (1,0) [0|1] ""  RDR05
 SG_ DET_IDM_042_Rx : 175|1@1+ (1,0) [0|1] ""  RDR05
 SG_ DET_MTD_042_Rx : 159|1@1+ (1,0) [0|1] ""  RDR05
 SG_ DET_BELOW_RAIN_THOLD_042_Rx : 151|1@1+ (1,0) [0|1] ""  RDR05
 SG_ DET_RANGE_043_Rx : 248|15@1+ (0.015625,0) [0|500] "m"  RDR05
 SG_ DET_RANGE_ERR_043_Rx : 264|7@1+ (0.0075,0) [0|0.9525] "m"  RDR05
 SG_ DET_RANGE_VELOCITY_043_Rx : 272|15@1+ (0.0078125,-128) [-128|127.9921875] "m/s"  RDR05
 SG_ DET_RANGE_VELOCITY_ERR_043_Rx : 288|8@1+ (0.003,0) [0|0.765] "m/s"  RDR05
 SG_ DET_AZIMUTH_043_Rx : 312|13@1+ (0.0004,-1.5708) [-1.5708|1.5708] "rad"  RDR05
 SG_ DET_AZIMUTH_ERR_043_Rx : 329|7@1+ (0.00087267,0) [0|0.11082909] "rad"  RDR05
 SG_ DET_ELEVATION_043_Rx : 296|8@1+ (0.00275,-0.34925) [-0.34925|0.34925] "rad"  RDR05
 SG_ DET_ELEVATION_ERR_043_Rx : 304|6@1+ (0.00174533,0) [0|0.10995579] "rad"  RDR05
 SG_ DET_RCS_043_Rx : 352|8@1+ (0.5,-64) [-64|63.5] "dBsm"  RDR05
 SG_ DET_BI_STATIC_FLAG_043_Rx : 328|1@1+ (1,0) [0|1] ""  RDR05
 SG_ DET_SUPER_RES_TARGET_043_Rx : 311|1@1+ (1,0) [0|1] ""  RDR05
 SG_ DET_SNR_043_Rx : 344|8@1+ (0.35156,0) [0|89.6478] "dB"  RDR05
 SG_ DET_EXISTENCE_PROB_043_Rx : 336|6@1+ (1.588,0) [0|100] "%"  RDR05
 SG_ DET_HVC_FLAG_043_Rx : 310|1@1+ (1,0) [0|1] ""  RDR05
 SG_ DET_CONFD_AZIMUTH_043_Rx : 342|2@1+ (1,0) [0|3] ""  RDR05
 SG_ DET_CONFD_ELEVATION_043_Rx : 325|2@1+ (1,0) [0|3] ""  RDR05
 SG_ DET_PROB_1STAZHYPO_043_Rx : 327|1@1+ (1,0) [0|1] ""  RDR05
 SG_ DET_IDM_043_Rx : 287|1@1+ (1,0) [0|1] ""  RDR05
 SG_ DET_MTD_043_Rx : 271|1@1+ (1,0) [0|1] ""  RDR05
 SG_ DET_BELOW_RAIN_THOLD_043_Rx : 263|1@1+ (1,0) [0|1] ""  RDR05
 SG_ DET_RANGE_044_Rx : 360|15@1+ (0.015625,0) [0|500] "m"  RDR05
 SG_ DET_RANGE_ERR_044_Rx : 376|7@1+ (0.0075,0) [0|0.9525] "m"  RDR05
 SG_ DET_RANGE_VELOCITY_044_Rx : 384|15@1+ (0.0078125,-128) [-128|127.9921875] "m/s"  RDR05
 SG_ DET_RANGE_VELOCITY_ERR_044_Rx : 400|8@1+ (0.003,0) [0|0.765] "m/s"  RDR05
 SG_ DET_AZIMUTH_044_Rx : 424|13@1+ (0.0004,-1.5708) [-1.5708|1.5708] "rad"  RDR05
 SG_ DET_AZIMUTH_ERR_044_Rx : 441|7@1+ (0.00087267,0) [0|0.11082909] "rad"  RDR05
 SG_ DET_ELEVATION_044_Rx : 408|8@1+ (0.00275,-0.34925) [-0.34925|0.34925] "rad"  RDR05
 SG_ DET_ELEVATION_ERR_044_Rx : 416|6@1+ (0.00174533,0) [0|0.10995579] "rad"  RDR05
 SG_ DET_RCS_044_Rx : 464|8@1+ (0.5,-64) [-64|63.5] "dBsm"  RDR05
 SG_ DET_BI_STATIC_FLAG_044_Rx : 440|1@1+ (1,0) [0|1] ""  RDR05
 SG_ DET_SUPER_RES_TARGET_044_Rx : 423|1@1+ (1,0) [0|1] ""  RDR05
 SG_ DET_SNR_044_Rx : 456|8@1+ (0.35156,0) [0|89.6478] "dB"  RDR05
 SG_ DET_EXISTENCE_PROB_044_Rx : 448|6@1+ (1.588,0) [0|100] "%"  RDR05
 SG_ DET_HVC_FLAG_044_Rx : 422|1@1+ (1,0) [0|1] ""  RDR05
 SG_ DET_CONFD_AZIMUTH_044_Rx : 454|2@1+ (1,0) [0|3] ""  RDR05
 SG_ DET_CONFD_ELEVATION_044_Rx : 437|2@1+ (1,0) [0|3] ""  RDR05
 SG_ DET_MH_SCAN_INDEX_4LSB_041_044_R : 476|4@1+ (1,0) [0|15] ""  RDR05
 SG_ DET_MH_CYCLE_COUNTER_041_044_Rx : 16|8@1+ (1,0) [0|255] ""  RDR05
 SG_ DET_MH_CRC16_041_044_Rx : 0|16@1+ (1,0) [0|65535] ""  RDR05
 SG_ DET_PROB_1STAZHYPO_044_Rx : 439|1@1+ (1,0) [0|1] ""  RDR05
 SG_ DET_IDM_044_Rx : 399|1@1+ (1,0) [0|1] ""  RDR05
 SG_ DET_MTD_044_Rx : 383|1@1+ (1,0) [0|1] ""  RDR05
 SG_ DET_BELOW_RAIN_THOLD_044_Rx : 375|1@1+ (1,0) [0|1] ""  RDR05

BO_ 267 RDR_FUSION_DET_045_048: 64 RDR_Fusion_Partner
 SG_ DET_RANGE_045_Rx : 24|15@1+ (0.015625,0) [0|500] "m"  RDR05
 SG_ DET_RANGE_ERR_045_Rx : 40|7@1+ (0.0075,0) [0|0.9525] "m"  RDR05
 SG_ DET_RANGE_VELOCITY_045_Rx : 48|15@1+ (0.0078125,-128) [-128|127.9921875] "m/s"  RDR05
 SG_ DET_RANGE_VELOCITY_ERR_045_Rx : 64|8@1+ (0.003,0) [0|0.765] "m/s"  RDR05
 SG_ DET_AZIMUTH_045_Rx : 88|13@1+ (0.0004,-1.5708) [-1.5708|1.5708] "rad"  RDR05
 SG_ DET_AZIMUTH_ERR_045_Rx : 105|7@1+ (0.00087267,0) [0|0.11082909] "rad"  RDR05
 SG_ DET_ELEVATION_045_Rx : 72|8@1+ (0.00275,-0.34925) [-0.34925|0.34925] "rad"  RDR05
 SG_ DET_ELEVATION_ERR_045_Rx : 80|6@1+ (0.00174533,0) [0|0.10995579] "rad"  RDR05
 SG_ DET_RCS_045_Rx : 128|8@1+ (0.5,-64) [-64|63.5] "dBsm"  RDR05
 SG_ DET_BI_STATIC_FLAG_045_Rx : 104|1@1+ (1,0) [0|1] ""  RDR05
 SG_ DET_SUPER_RES_TARGET_045_Rx : 87|1@1+ (1,0) [0|1] ""  RDR05
 SG_ DET_SNR_045_Rx : 120|8@1+ (0.35156,0) [0|89.6478] "dB"  RDR05
 SG_ DET_EXISTENCE_PROB_045_Rx : 112|6@1+ (1.588,0) [0|100] "%"  RDR05
 SG_ DET_HVC_FLAG_045_Rx : 86|1@1+ (1,0) [0|1] ""  RDR05
 SG_ DET_CONFD_AZIMUTH_045_Rx : 118|2@1+ (1,0) [0|3] ""  RDR05
 SG_ DET_CONFD_ELEVATION_045_Rx : 101|2@1+ (1,0) [0|3] ""  RDR05
 SG_ DET_PROB_1STAZHYPO_045_Rx : 103|1@1+ (1,0) [0|1] ""  RDR05
 SG_ DET_IDM_045_Rx : 63|1@1+ (1,0) [0|1] ""  RDR05
 SG_ DET_MTD_045_Rx : 47|1@1+ (1,0) [0|1] ""  RDR05
 SG_ DET_BELOW_RAIN_THOLD_045_Rx : 39|1@1+ (1,0) [0|1] ""  RDR05
 SG_ DET_RANGE_046_Rx : 136|15@1+ (0.015625,0) [0|500] "m"  RDR05
 SG_ DET_RANGE_ERR_046_Rx : 152|7@1+ (0.0075,0) [0|0.9525] "m"  RDR05
 SG_ DET_RANGE_VELOCITY_046_Rx : 160|15@1+ (0.0078125,-128) [-128|127.9921875] "m/s"  RDR05
 SG_ DET_RANGE_VELOCITY_ERR_046_Rx : 176|8@1+ (0.003,0) [0|0.765] "m/s"  RDR05
 SG_ DET_AZIMUTH_046_Rx : 200|13@1+ (0.0004,-1.5708) [-1.5708|1.5708] "rad"  RDR05
 SG_ DET_AZIMUTH_ERR_046_Rx : 217|7@1+ (0.00087267,0) [0|0.11082909] "rad"  RDR05
 SG_ DET_ELEVATION_046_Rx : 184|8@1+ (0.00275,-0.34925) [-0.34925|0.34925] "rad"  RDR05
 SG_ DET_ELEVATION_ERR_046_Rx : 192|6@1+ (0.00174533,0) [0|0.10995579] "rad"  RDR05
 SG_ DET_RCS_046_Rx : 240|8@1+ (0.5,-64) [-64|63.5] "dBsm"  RDR05
 SG_ DET_BI_STATIC_FLAG_046_Rx : 216|1@1+ (1,0) [0|1] ""  RDR05
 SG_ DET_SUPER_RES_TARGET_046_Rx : 199|1@1+ (1,0) [0|1] ""  RDR05
 SG_ DET_SNR_046_Rx : 232|8@1+ (0.35156,0) [0|89.6478] "dB"  RDR05
 SG_ DET_EXISTENCE_PROB_046_Rx : 224|6@1+ (1.588,0) [0|100] "%"  RDR05
 SG_ DET_HVC_FLAG_046_Rx : 198|1@1+ (1,0) [0|1] ""  RDR05
 SG_ DET_CONFD_AZIMUTH_046_Rx : 230|2@1+ (1,0) [0|3] ""  RDR05
 SG_ DET_CONFD_ELEVATION_046_Rx : 213|2@1+ (1,0) [0|3] ""  RDR05
 SG_ DET_PROB_1STAZHYPO_046_Rx : 215|1@1+ (1,0) [0|1] ""  RDR05
 SG_ DET_IDM_046_Rx : 175|1@1+ (1,0) [0|1] ""  RDR05
 SG_ DET_MTD_046_Rx : 159|1@1+ (1,0) [0|1] ""  RDR05
 SG_ DET_BELOW_RAIN_THOLD_046_Rx : 151|1@1+ (1,0) [0|1] ""  RDR05
 SG_ DET_RANGE_047_Rx : 248|15@1+ (0.015625,0) [0|500] "m"  RDR05
 SG_ DET_RANGE_ERR_047_Rx : 264|7@1+ (0.0075,0) [0|0.9525] "m"  RDR05
 SG_ DET_RANGE_VELOCITY_047_Rx : 272|15@1+ (0.0078125,-128) [-128|127.9921875] "m/s"  RDR05
 SG_ DET_RANGE_VELOCITY_ERR_047_Rx : 288|8@1+ (0.003,0) [0|0.765] "m/s"  RDR05
 SG_ DET_AZIMUTH_047_Rx : 312|13@1+ (0.0004,-1.5708) [-1.5708|1.5708] "rad"  RDR05
 SG_ DET_AZIMUTH_ERR_047_Rx : 329|7@1+ (0.00087267,0) [0|0.11082909] "rad"  RDR05
 SG_ DET_ELEVATION_047_Rx : 296|8@1+ (0.00275,-0.34925) [-0.34925|0.34925] "rad"  RDR05
 SG_ DET_ELEVATION_ERR_047_Rx : 304|6@1+ (0.00174533,0) [0|0.10995579] "rad"  RDR05
 SG_ DET_RCS_047_Rx : 352|8@1+ (0.5,-64) [-64|63.5] "dBsm"  RDR05
 SG_ DET_BI_STATIC_FLAG_047_Rx : 328|1@1+ (1,0) [0|1] ""  RDR05
 SG_ DET_SUPER_RES_TARGET_047_Rx : 311|1@1+ (1,0) [0|1] ""  RDR05
 SG_ DET_SNR_047_Rx : 344|8@1+ (0.35156,0) [0|89.6478] "dB"  RDR05
 SG_ DET_EXISTENCE_PROB_047_Rx : 336|6@1+ (1.588,0) [0|100] "%"  RDR05
 SG_ DET_HVC_FLAG_047_Rx : 310|1@1+ (1,0) [0|1] ""  RDR05
 SG_ DET_CONFD_AZIMUTH_047_Rx : 342|2@1+ (1,0) [0|3] ""  RDR05
 SG_ DET_CONFD_ELEVATION_047_Rx : 325|2@1+ (1,0) [0|3] ""  RDR05
 SG_ DET_PROB_1STAZHYPO_047_Rx : 327|1@1+ (1,0) [0|1] ""  RDR05
 SG_ DET_IDM_047_Rx : 287|1@1+ (1,0) [0|1] ""  RDR05
 SG_ DET_MTD_047_Rx : 271|1@1+ (1,0) [0|1] ""  RDR05
 SG_ DET_BELOW_RAIN_THOLD_047_Rx : 263|1@1+ (1,0) [0|1] ""  RDR05
 SG_ DET_RANGE_048_Rx : 360|15@1+ (0.015625,0) [0|500] "m"  RDR05
 SG_ DET_RANGE_ERR_048_Rx : 376|7@1+ (0.0075,0) [0|0.9525] "m"  RDR05
 SG_ DET_RANGE_VELOCITY_048_Rx : 384|15@1+ (0.0078125,-128) [-128|127.9921875] "m/s"  RDR05
 SG_ DET_RANGE_VELOCITY_ERR_048_Rx : 400|8@1+ (0.003,0) [0|0.765] "m/s"  RDR05
 SG_ DET_AZIMUTH_048_Rx : 424|13@1+ (0.0004,-1.5708) [-1.5708|1.5708] "rad"  RDR05
 SG_ DET_AZIMUTH_ERR_048_Rx : 441|7@1+ (0.00087267,0) [0|0.11082909] "rad"  RDR05
 SG_ DET_ELEVATION_048_Rx : 408|8@1+ (0.00275,-0.34925) [-0.34925|0.34925] "rad"  RDR05
 SG_ DET_ELEVATION_ERR_048_Rx : 416|6@1+ (0.00174533,0) [0|0.10995579] "rad"  RDR05
 SG_ DET_RCS_048_Rx : 464|8@1+ (0.5,-64) [-64|63.5] "dBsm"  RDR05
 SG_ DET_BI_STATIC_FLAG_048_Rx : 440|1@1+ (1,0) [0|1] ""  RDR05
 SG_ DET_SUPER_RES_TARGET_048_Rx : 423|1@1+ (1,0) [0|1] ""  RDR05
 SG_ DET_SNR_048_Rx : 456|8@1+ (0.35156,0) [0|89.6478] "dB"  RDR05
 SG_ DET_EXISTENCE_PROB_048_Rx : 448|6@1+ (1.588,0) [0|100] "%"  RDR05
 SG_ DET_HVC_FLAG_048_Rx : 422|1@1+ (1,0) [0|1] ""  RDR05
 SG_ DET_CONFD_AZIMUTH_048_Rx : 454|2@1+ (1,0) [0|3] ""  RDR05
 SG_ DET_CONFD_ELEVATION_048_Rx : 437|2@1+ (1,0) [0|3] ""  RDR05
 SG_ DET_MH_SCAN_INDEX_4LSB_045_048_R : 476|4@1+ (1,0) [0|15] ""  RDR05
 SG_ DET_MH_CYCLE_COUNTER_045_048_Rx : 16|8@1+ (1,0) [0|255] ""  RDR05
 SG_ DET_MH_CRC16_045_048_Rx : 0|16@1+ (1,0) [0|65535] ""  RDR05
 SG_ DET_PROB_1STAZHYPO_048_Rx : 439|1@1+ (1,0) [0|1] ""  RDR05
 SG_ DET_IDM_048_Rx : 399|1@1+ (1,0) [0|1] ""  RDR05
 SG_ DET_MTD_048_Rx : 383|1@1+ (1,0) [0|1] ""  RDR05
 SG_ DET_BELOW_RAIN_THOLD_048_Rx : 375|1@1+ (1,0) [0|1] ""  RDR05

BA_DEF_ BO_  "VFrameFormat" ENUM  "StandardCAN","ExtendedCAN","reserved","reserved","reserved","reserved","reserved","reserved","reserved","reserved","reserved","reserved","reserved","reserved","StandardCAN_FD","ExtendedCAN_FD";
BA_DEF_ BO_  "CanTpBs" INT 0 255;
BA_DEF_ BO_  "DiagRequest" ENUM  "No","Yes";
BA_DEF_ BO_  "DiagResponse" ENUM  "No","Yes";
BA_DEF_ BO_  "EventRateOfChange" INT 10 10000;
BA_DEF_ BO_  "GenMsgCycleTime" INT 0 100000;
BA_DEF_ BO_  "GenMsgILSupport" ENUM  "No","Yes";
BA_DEF_ BO_  "GenMsgNrOfRepetition" INT 0 100;
BA_DEF_ BO_  "GenMsgSendType" ENUM  "FixedPeriodic","Event","EnabledPeriodic","NotUsed","NotUsed","EventPeriodic","NotUsed","NotUsed","NoMsgSendType";
BA_DEF_ BO_  "NetworkInitialization" ENUM  "No","Yes";
BA_DEF_ BO_  "NmAsrMessage" ENUM  "No","Yes";
BA_DEF_ BO_  "NmMessage" ENUM  "No","Yes";
BA_DEF_ BO_  "SCP_AuthInfoTxLength" INT 0 512;
BA_DEF_ BO_  "SCP_FreshnessValueLength" INT 0 512;
BA_DEF_ BO_  "SCP_FreshnessValueTxLength" INT 0 512;
BA_DEF_ BO_  "TpTxIndex" INT 0 255;
BA_DEF_ SG_  "GenSigCmt" STRING ;
BA_DEF_ SG_  "GenSigCycleTime" INT 0 0;
BA_DEF_ SG_  "GenSigSendType" ENUM  "Cyclic","OnWrite","vector_leerstring","OnChange","vector_leerstring","IfActive","vector_leerstring","NoSigSendType";
BA_DEF_ SG_  "GenSigStartValue" INT 0 1000000000;
BA_DEF_ SG_  "GenSigTimeoutTime" INT 0 0;
BA_DEF_ SG_  "GenSigVtEn" STRING ;
BA_DEF_ SG_  "GenSigVtName" STRING ;
BA_DEF_ SG_  "InvalidValue" STRING ;
BA_DEF_ SG_  "SystemSignalLongSymbol" STRING ;
BA_DEF_DEF_  "VFrameFormat" "StandardCAN_FD";
BA_DEF_DEF_  "CanTpBs" 255;
BA_DEF_DEF_  "DiagRequest" "No";
BA_DEF_DEF_  "DiagResponse" "No";
BA_DEF_DEF_  "EventRateOfChange" 10000;
BA_DEF_DEF_  "GenMsgCycleTime" 0;
BA_DEF_DEF_  "GenMsgILSupport" "Yes";
BA_DEF_DEF_  "GenMsgNrOfRepetition" 0;
BA_DEF_DEF_  "GenMsgSendType" "NoMsgSendType";
BA_DEF_DEF_  "NetworkInitialization" "Yes";
BA_DEF_DEF_  "NmAsrMessage" "No";
BA_DEF_DEF_  "NmMessage" "No";
BA_DEF_DEF_  "SCP_AuthInfoTxLength" 28;
BA_DEF_DEF_  "SCP_FreshnessValueLength" 48;
BA_DEF_DEF_  "SCP_FreshnessValueTxLength" 4;
BA_DEF_DEF_  "TpTxIndex" 0;
BA_DEF_DEF_  "GenSigCmt" "";
BA_DEF_DEF_  "GenSigCycleTime" 0;
BA_DEF_DEF_  "GenSigSendType" "NoSigSendType";
BA_DEF_DEF_  "GenSigStartValue" 0;
BA_DEF_DEF_  "GenSigTimeoutTime" 0;
BA_DEF_DEF_  "GenSigVtEn" "";
BA_DEF_DEF_  "GenSigVtName" "";
BA_DEF_DEF_  "InvalidValue" "";
BA_DEF_DEF_  "SystemSignalLongSymbol" "";
BA_ "GenMsgSendType" BO_ 2565668606 0;
BA_ "GenMsgCycleTime" BO_ 2565668606 1000;
BA_ "VFrameFormat" BO_ 2565668606 3;
BA_ "GenMsgSendType" BO_ 2565603070 0;
BA_ "GenMsgCycleTime" BO_ 2565603070 1000;
BA_ "VFrameFormat" BO_ 2565603070 3;
BA_ "GenMsgSendType" BO_ 2566834942 0;
BA_ "GenMsgCycleTime" BO_ 2566834942 1000;
BA_ "VFrameFormat" BO_ 2566834942 3;
BA_ "VFrameFormat" BO_ 2564486577 15;
BA_ "VFrameFormat" BO_ 2564486321 15;
BA_ "VFrameFormat" BO_ 2564485553 15;
BA_ "VFrameFormat" BO_ 2364671664 3;
BA_ "VFrameFormat" BO_ 2364671680 1;
BA_ "SystemSignalLongSymbol" SG_ 2364671680 BlindSpotWarnigRelevantObjD_0000 "BlindSpotWarnigRelevantObjDetect_Tx";
BA_ "SystemSignalLongSymbol" SG_ 2364671680 BlindSpotCollisionWarningLevel_T "BlindSpotCollisionWarningLevel_Tx";
BA_ "SystemSignalLongSymbol" SG_ 2364671680 BendOffPrbablityofMstImport_0000 "BendOffPrbablityofMstImportatObj_Tx";
BA_ "SystemSignalLongSymbol" SG_ 256 DET_MH_SCAN_INDEX_4LSB_001_004_R "DET_MH_SCAN_INDEX_4LSB_001_004_Rx";
BA_ "SystemSignalLongSymbol" SG_ 257 DET_MH_SCAN_INDEX_4LSB_005_008_R "DET_MH_SCAN_INDEX_4LSB_005_008_Rx";
BA_ "SystemSignalLongSymbol" SG_ 258 DET_MH_SCAN_INDEX_4LSB_009_012_R "DET_MH_SCAN_INDEX_4LSB_009_012_Rx";
BA_ "SystemSignalLongSymbol" SG_ 259 DET_MH_SCAN_INDEX_4LSB_013_016_R "DET_MH_SCAN_INDEX_4LSB_013_016_Rx";
BA_ "SystemSignalLongSymbol" SG_ 260 DET_MH_SCAN_INDEX_4LSB_017_020_R "DET_MH_SCAN_INDEX_4LSB_017_020_Rx";
BA_ "SystemSignalLongSymbol" SG_ 261 DET_MH_SCAN_INDEX_4LSB_021_024_R "DET_MH_SCAN_INDEX_4LSB_021_024_Rx";
BA_ "SystemSignalLongSymbol" SG_ 262 DET_MH_SCAN_INDEX_4LSB_025_028_R "DET_MH_SCAN_INDEX_4LSB_025_028_Rx";
BA_ "SystemSignalLongSymbol" SG_ 263 DET_MH_SCAN_INDEX_4LSB_029_032_R "DET_MH_SCAN_INDEX_4LSB_029_032_Rx";
BA_ "SystemSignalLongSymbol" SG_ 264 DET_MH_SCAN_INDEX_4LSB_033_036_R "DET_MH_SCAN_INDEX_4LSB_033_036_Rx";
BA_ "SystemSignalLongSymbol" SG_ 265 DET_MH_SCAN_INDEX_4LSB_037_040_R "DET_MH_SCAN_INDEX_4LSB_037_040_Rx";
BA_ "SystemSignalLongSymbol" SG_ 266 DET_MH_SCAN_INDEX_4LSB_041_044_R "DET_MH_SCAN_INDEX_4LSB_041_044_Rx";
BA_ "SystemSignalLongSymbol" SG_ 267 DET_MH_SCAN_INDEX_4LSB_045_048_R "DET_MH_SCAN_INDEX_4LSB_045_048_Rx";
SIG_GROUP_ 1600 TrackerObject049 1 : OBJ_ALIVE_TIME_049 OBJ_ACCELERATION_LONG_ERR_049 OBJ_ACCELERATION_LAT_ERR_049 OBJ_VELOCITY_LONG_ERR_049 OBJ_VELOCITY_LAT_ERR_049 OBJ_POS_LONG_ERR_049 OBJ_POS_LAT_ERR_049 OBJ_TRACK_MOTION_MODEL_049 OBJ_DIMENSION_WIDTH_049 OBJ_DIMENSION_LENGTH_049 OBJ_EXISTENCE_PROB_049 OBJ_YAW_ANGLE_049 OBJ_YAW_ANGLE_ERR_049 OBJ_ID_049 OBJ_MOVEMENT_STATUS_049 OBJ_MEASUREMENT_STATUS_049 OBJ_POS_LONG_049 OBJ_POS_LAT_049 OBJ_VELOCITY_LONG_049 OBJ_VELOCITY_LAT_049 OBJ_ACCELERATION_LONG_049 OBJ_ACCELERATION_LAT_049 OBJ_VEH_TRACK_FLAG_049 OBJ_MH_CYCLE_COUNTER_049 OBJ_MH_CRC16_049 OBJ_TIMESTAMP_OFFSET_049 OBJ_DIMENSION_WIDTH_ERR_049 OBJ_DIMENSION_LENGTH_ERR_049 OBJ_CLS_TYPE1_049 OBJ_CLS_TYPE1_PROB_049 OBJ_CLS_TYPE2_049 OBJ_CLS_TYPE2_PROB_049 OBJ_CLS_TYPE3_049 OBJ_CLS_TYPE3_PROB_049 OBJ_CLS_TYPE4_049 OBJ_CLS_TYPE4_PROB_049 OBJ_CLS_TYPE5_049 OBJ_CLS_TYPE5_PROB_049 OBJ_CLS_TYPE6_049 OBJ_CLS_TYPE6_PROB_049 OBJ_RCS_049 OBJ_REF_PT_LONG_OFFSET_049 OBJ_REF_PT_LAT_OFFSET_049 OBJ_YAW_RATE_049 OBJ_YAW_RATE_ERR_049 OBJ_GROUP_ID_049 OBJ_POS_ERR_CRR_COEF_049 OBJ_VELOCITY_ERR_CRR_COEF_049 OBJ_ACCEL_ERR_CRR_COEF_049;
SIG_GROUP_ 1601 TrackerObject050 1 : OBJ_ALIVE_TIME_050 OBJ_ACCELERATION_LONG_ERR_050 OBJ_ACCELERATION_LAT_ERR_050 OBJ_VELOCITY_LONG_ERR_050 OBJ_VELOCITY_LAT_ERR_050 OBJ_POS_LONG_ERR_050 OBJ_POS_LAT_ERR_050 OBJ_TRACK_MOTION_MODEL_050 OBJ_DIMENSION_WIDTH_050 OBJ_DIMENSION_LENGTH_050 OBJ_EXISTENCE_PROB_050 OBJ_YAW_ANGLE_050 OBJ_YAW_ANGLE_ERR_050 OBJ_ID_050 OBJ_MOVEMENT_STATUS_050 OBJ_MEASUREMENT_STATUS_050 OBJ_POS_LONG_050 OBJ_POS_LAT_050 OBJ_VELOCITY_LONG_050 OBJ_VELOCITY_LAT_050 OBJ_ACCELERATION_LONG_050 OBJ_ACCELERATION_LAT_050 OBJ_VEH_TRACK_FLAG_050 OBJ_MH_CYCLE_COUNTER_050 OBJ_MH_CRC16_050 OBJ_TIMESTAMP_OFFSET_050 OBJ_DIMENSION_WIDTH_ERR_050 OBJ_DIMENSION_LENGTH_ERR_050 OBJ_CLS_TYPE1_050 OBJ_CLS_TYPE1_PROB_050 OBJ_CLS_TYPE2_050 OBJ_CLS_TYPE2_PROB_050 OBJ_CLS_TYPE3_050 OBJ_CLS_TYPE3_PROB_050 OBJ_CLS_TYPE4_050 OBJ_CLS_TYPE4_PROB_050 OBJ_CLS_TYPE5_050 OBJ_CLS_TYPE5_PROB_050 OBJ_CLS_TYPE6_050 OBJ_CLS_TYPE6_PROB_050 OBJ_RCS_050 OBJ_REF_PT_LONG_OFFSET_050 OBJ_REF_PT_LAT_OFFSET_050 OBJ_YAW_RATE_050 OBJ_YAW_RATE_ERR_050 OBJ_GROUP_ID_050 OBJ_POS_ERR_CRR_COEF_050 OBJ_VELOCITY_ERR_CRR_COEF_050 OBJ_ACCEL_ERR_CRR_COEF_050;
SIG_GROUP_ 1602 TrackerObject051 1 : OBJ_ALIVE_TIME_051 OBJ_ACCELERATION_LONG_ERR_051 OBJ_ACCELERATION_LAT_ERR_051 OBJ_VELOCITY_LONG_ERR_051 OBJ_VELOCITY_LAT_ERR_051 OBJ_POS_LONG_ERR_051 OBJ_POS_LAT_ERR_051 OBJ_TRACK_MOTION_MODEL_051 OBJ_DIMENSION_WIDTH_051 OBJ_DIMENSION_LENGTH_051 OBJ_EXISTENCE_PROB_051 OBJ_YAW_ANGLE_051 OBJ_YAW_ANGLE_ERR_051 OBJ_ID_051 OBJ_MOVEMENT_STATUS_051 OBJ_MEASUREMENT_STATUS_051 OBJ_POS_LONG_051 OBJ_POS_LAT_051 OBJ_VELOCITY_LONG_051 OBJ_VELOCITY_LAT_051 OBJ_ACCELERATION_LONG_051 OBJ_ACCELERATION_LAT_051 OBJ_VEH_TRACK_FLAG_051 OBJ_MH_CYCLE_COUNTER_051 OBJ_MH_CRC16_051 OBJ_TIMESTAMP_OFFSET_051 OBJ_DIMENSION_WIDTH_ERR_051 OBJ_DIMENSION_LENGTH_ERR_051 OBJ_CLS_TYPE1_051 OBJ_CLS_TYPE1_PROB_051 OBJ_CLS_TYPE2_051 OBJ_CLS_TYPE2_PROB_051 OBJ_CLS_TYPE3_051 OBJ_CLS_TYPE3_PROB_051 OBJ_CLS_TYPE4_051 OBJ_CLS_TYPE4_PROB_051 OBJ_CLS_TYPE5_051 OBJ_CLS_TYPE5_PROB_051 OBJ_CLS_TYPE6_051 OBJ_CLS_TYPE6_PROB_051 OBJ_RCS_051 OBJ_REF_PT_LONG_OFFSET_051 OBJ_REF_PT_LAT_OFFSET_051 OBJ_YAW_RATE_051 OBJ_YAW_RATE_ERR_051 OBJ_GROUP_ID_051 OBJ_POS_ERR_CRR_COEF_051 OBJ_VELOCITY_ERR_CRR_COEF_051 OBJ_ACCEL_ERR_CRR_COEF_051;
SIG_GROUP_ 1603 TrackerObject052 1 : OBJ_ALIVE_TIME_052 OBJ_ACCELERATION_LONG_ERR_052 OBJ_ACCELERATION_LAT_ERR_052 OBJ_VELOCITY_LONG_ERR_052 OBJ_VELOCITY_LAT_ERR_052 OBJ_POS_LONG_ERR_052 OBJ_POS_LAT_ERR_052 OBJ_TRACK_MOTION_MODEL_052 OBJ_DIMENSION_WIDTH_052 OBJ_DIMENSION_LENGTH_052 OBJ_EXISTENCE_PROB_052 OBJ_YAW_ANGLE_052 OBJ_YAW_ANGLE_ERR_052 OBJ_ID_052 OBJ_MOVEMENT_STATUS_052 OBJ_MEASUREMENT_STATUS_052 OBJ_POS_LONG_052 OBJ_POS_LAT_052 OBJ_VELOCITY_LONG_052 OBJ_VELOCITY_LAT_052 OBJ_ACCELERATION_LONG_052 OBJ_ACCELERATION_LAT_052 OBJ_VEH_TRACK_FLAG_052 OBJ_MH_CYCLE_COUNTER_052 OBJ_MH_CRC16_052 OBJ_TIMESTAMP_OFFSET_052 OBJ_DIMENSION_WIDTH_ERR_052 OBJ_DIMENSION_LENGTH_ERR_052 OBJ_CLS_TYPE1_052 OBJ_CLS_TYPE1_PROB_052 OBJ_CLS_TYPE2_052 OBJ_CLS_TYPE2_PROB_052 OBJ_CLS_TYPE3_052 OBJ_CLS_TYPE3_PROB_052 OBJ_CLS_TYPE4_052 OBJ_CLS_TYPE4_PROB_052 OBJ_CLS_TYPE5_052 OBJ_CLS_TYPE5_PROB_052 OBJ_CLS_TYPE6_052 OBJ_CLS_TYPE6_PROB_052 OBJ_RCS_052 OBJ_REF_PT_LONG_OFFSET_052 OBJ_REF_PT_LAT_OFFSET_052 OBJ_YAW_RATE_052 OBJ_YAW_RATE_ERR_052 OBJ_GROUP_ID_052 OBJ_POS_ERR_CRR_COEF_052 OBJ_VELOCITY_ERR_CRR_COEF_052 OBJ_ACCEL_ERR_CRR_COEF_052;
SIG_GROUP_ 1604 TrackerObject053 1 : OBJ_ALIVE_TIME_053 OBJ_ACCELERATION_LONG_ERR_053 OBJ_ACCELERATION_LAT_ERR_053 OBJ_VELOCITY_LONG_ERR_053 OBJ_VELOCITY_LAT_ERR_053 OBJ_POS_LONG_ERR_053 OBJ_POS_LAT_ERR_053 OBJ_TRACK_MOTION_MODEL_053 OBJ_DIMENSION_WIDTH_053 OBJ_DIMENSION_LENGTH_053 OBJ_EXISTENCE_PROB_053 OBJ_YAW_ANGLE_053 OBJ_YAW_ANGLE_ERR_053 OBJ_ID_053 OBJ_MOVEMENT_STATUS_053 OBJ_MEASUREMENT_STATUS_053 OBJ_POS_LONG_053 OBJ_POS_LAT_053 OBJ_VELOCITY_LONG_053 OBJ_VELOCITY_LAT_053 OBJ_ACCELERATION_LONG_053 OBJ_ACCELERATION_LAT_053 OBJ_VEH_TRACK_FLAG_053 OBJ_MH_CYCLE_COUNTER_053 OBJ_MH_CRC16_053 OBJ_TIMESTAMP_OFFSET_053 OBJ_DIMENSION_WIDTH_ERR_053 OBJ_DIMENSION_LENGTH_ERR_053 OBJ_CLS_TYPE1_053 OBJ_CLS_TYPE1_PROB_053 OBJ_CLS_TYPE2_053 OBJ_CLS_TYPE2_PROB_053 OBJ_CLS_TYPE3_053 OBJ_CLS_TYPE3_PROB_053 OBJ_CLS_TYPE4_053 OBJ_CLS_TYPE4_PROB_053 OBJ_CLS_TYPE5_053 OBJ_CLS_TYPE5_PROB_053 OBJ_CLS_TYPE6_053 OBJ_CLS_TYPE6_PROB_053 OBJ_RCS_053 OBJ_REF_PT_LONG_OFFSET_053 OBJ_REF_PT_LAT_OFFSET_053 OBJ_YAW_RATE_053 OBJ_YAW_RATE_ERR_053 OBJ_GROUP_ID_053 OBJ_POS_ERR_CRR_COEF_053 OBJ_VELOCITY_ERR_CRR_COEF_053 OBJ_ACCEL_ERR_CRR_COEF_053;
SIG_GROUP_ 1605 TrackerObject054 1 : OBJ_ALIVE_TIME_054 OBJ_ACCELERATION_LONG_ERR_054 OBJ_ACCELERATION_LAT_ERR_054 OBJ_VELOCITY_LONG_ERR_054 OBJ_VELOCITY_LAT_ERR_054 OBJ_POS_LONG_ERR_054 OBJ_POS_LAT_ERR_054 OBJ_TRACK_MOTION_MODEL_054 OBJ_DIMENSION_WIDTH_054 OBJ_DIMENSION_LENGTH_054 OBJ_EXISTENCE_PROB_054 OBJ_YAW_ANGLE_054 OBJ_YAW_ANGLE_ERR_054 OBJ_ID_054 OBJ_MOVEMENT_STATUS_054 OBJ_MEASUREMENT_STATUS_054 OBJ_POS_LONG_054 OBJ_POS_LAT_054 OBJ_VELOCITY_LONG_054 OBJ_VELOCITY_LAT_054 OBJ_ACCELERATION_LONG_054 OBJ_ACCELERATION_LAT_054 OBJ_VEH_TRACK_FLAG_054 OBJ_MH_CYCLE_COUNTER_054 OBJ_MH_CRC16_054 OBJ_TIMESTAMP_OFFSET_054 OBJ_DIMENSION_WIDTH_ERR_054 OBJ_DIMENSION_LENGTH_ERR_054 OBJ_CLS_TYPE1_054 OBJ_CLS_TYPE1_PROB_054 OBJ_CLS_TYPE2_054 OBJ_CLS_TYPE2_PROB_054 OBJ_CLS_TYPE3_054 OBJ_CLS_TYPE3_PROB_054 OBJ_CLS_TYPE4_054 OBJ_CLS_TYPE4_PROB_054 OBJ_CLS_TYPE5_054 OBJ_CLS_TYPE5_PROB_054 OBJ_CLS_TYPE6_054 OBJ_CLS_TYPE6_PROB_054 OBJ_RCS_054 OBJ_REF_PT_LONG_OFFSET_054 OBJ_REF_PT_LAT_OFFSET_054 OBJ_YAW_RATE_054 OBJ_YAW_RATE_ERR_054 OBJ_GROUP_ID_054 OBJ_POS_ERR_CRR_COEF_054 OBJ_VELOCITY_ERR_CRR_COEF_054 OBJ_ACCEL_ERR_CRR_COEF_054;
SIG_GROUP_ 1606 TrackerObject055 1 : OBJ_ALIVE_TIME_055 OBJ_ACCELERATION_LONG_ERR_055 OBJ_ACCELERATION_LAT_ERR_055 OBJ_VELOCITY_LONG_ERR_055 OBJ_VELOCITY_LAT_ERR_055 OBJ_POS_LONG_ERR_055 OBJ_POS_LAT_ERR_055 OBJ_TRACK_MOTION_MODEL_055 OBJ_DIMENSION_WIDTH_055 OBJ_DIMENSION_LENGTH_055 OBJ_EXISTENCE_PROB_055 OBJ_YAW_ANGLE_055 OBJ_YAW_ANGLE_ERR_055 OBJ_ID_055 OBJ_MOVEMENT_STATUS_055 OBJ_MEASUREMENT_STATUS_055 OBJ_POS_LONG_055 OBJ_POS_LAT_055 OBJ_VELOCITY_LONG_055 OBJ_VELOCITY_LAT_055 OBJ_ACCELERATION_LONG_055 OBJ_ACCELERATION_LAT_055 OBJ_VEH_TRACK_FLAG_055 OBJ_MH_CYCLE_COUNTER_055 OBJ_MH_CRC16_055 OBJ_TIMESTAMP_OFFSET_055 OBJ_DIMENSION_WIDTH_ERR_055 OBJ_DIMENSION_LENGTH_ERR_055 OBJ_CLS_TYPE1_055 OBJ_CLS_TYPE1_PROB_055 OBJ_CLS_TYPE2_055 OBJ_CLS_TYPE2_PROB_055 OBJ_CLS_TYPE3_055 OBJ_CLS_TYPE3_PROB_055 OBJ_CLS_TYPE4_055 OBJ_CLS_TYPE4_PROB_055 OBJ_CLS_TYPE5_055 OBJ_CLS_TYPE5_PROB_055 OBJ_CLS_TYPE6_055 OBJ_CLS_TYPE6_PROB_055 OBJ_RCS_055 OBJ_REF_PT_LONG_OFFSET_055 OBJ_REF_PT_LAT_OFFSET_055 OBJ_YAW_RATE_055 OBJ_YAW_RATE_ERR_055 OBJ_GROUP_ID_055 OBJ_POS_ERR_CRR_COEF_055 OBJ_VELOCITY_ERR_CRR_COEF_055 OBJ_ACCEL_ERR_CRR_COEF_055;
SIG_GROUP_ 1607 TrackerObject056 1 : OBJ_ALIVE_TIME_056 OBJ_ACCELERATION_LONG_ERR_056 OBJ_ACCELERATION_LAT_ERR_056 OBJ_VELOCITY_LONG_ERR_056 OBJ_VELOCITY_LAT_ERR_056 OBJ_POS_LONG_ERR_056 OBJ_POS_LAT_ERR_056 OBJ_TRACK_MOTION_MODEL_056 OBJ_DIMENSION_WIDTH_056 OBJ_DIMENSION_LENGTH_056 OBJ_EXISTENCE_PROB_056 OBJ_YAW_ANGLE_056 OBJ_YAW_ANGLE_ERR_056 OBJ_ID_056 OBJ_MOVEMENT_STATUS_056 OBJ_MEASUREMENT_STATUS_056 OBJ_POS_LONG_056 OBJ_POS_LAT_056 OBJ_VELOCITY_LONG_056 OBJ_VELOCITY_LAT_056 OBJ_ACCELERATION_LONG_056 OBJ_ACCELERATION_LAT_056 OBJ_VEH_TRACK_FLAG_056 OBJ_MH_CYCLE_COUNTER_056 OBJ_MH_CRC16_056 OBJ_TIMESTAMP_OFFSET_056 OBJ_DIMENSION_WIDTH_ERR_056 OBJ_DIMENSION_LENGTH_ERR_056 OBJ_CLS_TYPE1_056 OBJ_CLS_TYPE1_PROB_056 OBJ_CLS_TYPE2_056 OBJ_CLS_TYPE2_PROB_056 OBJ_CLS_TYPE3_056 OBJ_CLS_TYPE3_PROB_056 OBJ_CLS_TYPE4_056 OBJ_CLS_TYPE4_PROB_056 OBJ_CLS_TYPE5_056 OBJ_CLS_TYPE5_PROB_056 OBJ_CLS_TYPE6_056 OBJ_CLS_TYPE6_PROB_056 OBJ_RCS_056 OBJ_REF_PT_LONG_OFFSET_056 OBJ_REF_PT_LAT_OFFSET_056 OBJ_YAW_RATE_056 OBJ_YAW_RATE_ERR_056 OBJ_GROUP_ID_056 OBJ_POS_ERR_CRR_COEF_056 OBJ_VELOCITY_ERR_CRR_COEF_056 OBJ_ACCEL_ERR_CRR_COEF_056;
SIG_GROUP_ 1608 TrackerObject057 1 : OBJ_ALIVE_TIME_057 OBJ_ACCELERATION_LONG_ERR_057 OBJ_ACCELERATION_LAT_ERR_057 OBJ_VELOCITY_LONG_ERR_057 OBJ_VELOCITY_LAT_ERR_057 OBJ_POS_LONG_ERR_057 OBJ_POS_LAT_ERR_057 OBJ_TRACK_MOTION_MODEL_057 OBJ_DIMENSION_WIDTH_057 OBJ_DIMENSION_LENGTH_057 OBJ_EXISTENCE_PROB_057 OBJ_YAW_ANGLE_057 OBJ_YAW_ANGLE_ERR_057 OBJ_ID_057 OBJ_MOVEMENT_STATUS_057 OBJ_MEASUREMENT_STATUS_057 OBJ_POS_LONG_057 OBJ_POS_LAT_057 OBJ_VELOCITY_LONG_057 OBJ_VELOCITY_LAT_057 OBJ_ACCELERATION_LONG_057 OBJ_ACCELERATION_LAT_057 OBJ_VEH_TRACK_FLAG_057 OBJ_MH_CYCLE_COUNTER_057 OBJ_MH_CRC16_057 OBJ_TIMESTAMP_OFFSET_057 OBJ_DIMENSION_WIDTH_ERR_057 OBJ_DIMENSION_LENGTH_ERR_057 OBJ_CLS_TYPE1_057 OBJ_CLS_TYPE1_PROB_057 OBJ_CLS_TYPE2_057 OBJ_CLS_TYPE2_PROB_057 OBJ_CLS_TYPE3_057 OBJ_CLS_TYPE3_PROB_057 OBJ_CLS_TYPE4_057 OBJ_CLS_TYPE4_PROB_057 OBJ_CLS_TYPE5_057 OBJ_CLS_TYPE5_PROB_057 OBJ_CLS_TYPE6_057 OBJ_CLS_TYPE6_PROB_057 OBJ_RCS_057 OBJ_REF_PT_LONG_OFFSET_057 OBJ_REF_PT_LAT_OFFSET_057 OBJ_YAW_RATE_057 OBJ_YAW_RATE_ERR_057 OBJ_GROUP_ID_057 OBJ_POS_ERR_CRR_COEF_057 OBJ_VELOCITY_ERR_CRR_COEF_057 OBJ_ACCEL_ERR_CRR_COEF_057;
SIG_GROUP_ 1609 TrackerObject058 1 : OBJ_ALIVE_TIME_058 OBJ_ACCELERATION_LONG_ERR_058 OBJ_ACCELERATION_LAT_ERR_058 OBJ_VELOCITY_LONG_ERR_058 OBJ_VELOCITY_LAT_ERR_058 OBJ_POS_LONG_ERR_058 OBJ_POS_LAT_ERR_058 OBJ_TRACK_MOTION_MODEL_058 OBJ_DIMENSION_WIDTH_058 OBJ_DIMENSION_LENGTH_058 OBJ_EXISTENCE_PROB_058 OBJ_YAW_ANGLE_058 OBJ_YAW_ANGLE_ERR_058 OBJ_ID_058 OBJ_MOVEMENT_STATUS_058 OBJ_MEASUREMENT_STATUS_058 OBJ_POS_LONG_058 OBJ_POS_LAT_058 OBJ_VELOCITY_LONG_058 OBJ_VELOCITY_LAT_058 OBJ_ACCELERATION_LONG_058 OBJ_ACCELERATION_LAT_058 OBJ_VEH_TRACK_FLAG_058 OBJ_MH_CYCLE_COUNTER_058 OBJ_MH_CRC16_058 OBJ_TIMESTAMP_OFFSET_058 OBJ_DIMENSION_WIDTH_ERR_058 OBJ_DIMENSION_LENGTH_ERR_058 OBJ_CLS_TYPE1_058 OBJ_CLS_TYPE1_PROB_058 OBJ_CLS_TYPE2_058 OBJ_CLS_TYPE2_PROB_058 OBJ_CLS_TYPE3_058 OBJ_CLS_TYPE3_PROB_058 OBJ_CLS_TYPE4_058 OBJ_CLS_TYPE4_PROB_058 OBJ_CLS_TYPE5_058 OBJ_CLS_TYPE5_PROB_058 OBJ_CLS_TYPE6_058 OBJ_CLS_TYPE6_PROB_058 OBJ_RCS_058 OBJ_REF_PT_LONG_OFFSET_058 OBJ_REF_PT_LAT_OFFSET_058 OBJ_YAW_RATE_058 OBJ_YAW_RATE_ERR_058 OBJ_GROUP_ID_058 OBJ_POS_ERR_CRR_COEF_058 OBJ_VELOCITY_ERR_CRR_COEF_058 OBJ_ACCEL_ERR_CRR_COEF_058;
SIG_GROUP_ 1610 TrackerObject059 1 : OBJ_ALIVE_TIME_059 OBJ_ACCELERATION_LONG_ERR_059 OBJ_ACCELERATION_LAT_ERR_059 OBJ_VELOCITY_LONG_ERR_059 OBJ_VELOCITY_LAT_ERR_059 OBJ_POS_LONG_ERR_059 OBJ_POS_LAT_ERR_059 OBJ_TRACK_MOTION_MODEL_059 OBJ_DIMENSION_WIDTH_059 OBJ_DIMENSION_LENGTH_059 OBJ_EXISTENCE_PROB_059 OBJ_YAW_ANGLE_059 OBJ_YAW_ANGLE_ERR_059 OBJ_ID_059 OBJ_MOVEMENT_STATUS_059 OBJ_MEASUREMENT_STATUS_059 OBJ_POS_LONG_059 OBJ_POS_LAT_059 OBJ_VELOCITY_LONG_059 OBJ_VELOCITY_LAT_059 OBJ_ACCELERATION_LONG_059 OBJ_ACCELERATION_LAT_059 OBJ_VEH_TRACK_FLAG_059 OBJ_MH_CYCLE_COUNTER_059 OBJ_MH_CRC16_059 OBJ_TIMESTAMP_OFFSET_059 OBJ_DIMENSION_WIDTH_ERR_059 OBJ_DIMENSION_LENGTH_ERR_059 OBJ_CLS_TYPE1_059 OBJ_CLS_TYPE1_PROB_059 OBJ_CLS_TYPE2_059 OBJ_CLS_TYPE2_PROB_059 OBJ_CLS_TYPE3_059 OBJ_CLS_TYPE3_PROB_059 OBJ_CLS_TYPE4_059 OBJ_CLS_TYPE4_PROB_059 OBJ_CLS_TYPE5_059 OBJ_CLS_TYPE5_PROB_059 OBJ_CLS_TYPE6_059 OBJ_CLS_TYPE6_PROB_059 OBJ_RCS_059 OBJ_REF_PT_LONG_OFFSET_059 OBJ_REF_PT_LAT_OFFSET_059 OBJ_YAW_RATE_059 OBJ_YAW_RATE_ERR_059 OBJ_GROUP_ID_059 OBJ_POS_ERR_CRR_COEF_059 OBJ_VELOCITY_ERR_CRR_COEF_059 OBJ_ACCEL_ERR_CRR_COEF_059;
SIG_GROUP_ 1611 TrackerObject060 1 : OBJ_ALIVE_TIME_060 OBJ_ACCELERATION_LONG_ERR_060 OBJ_ACCELERATION_LAT_ERR_060 OBJ_VELOCITY_LONG_ERR_060 OBJ_VELOCITY_LAT_ERR_060 OBJ_POS_LONG_ERR_060 OBJ_POS_LAT_ERR_060 OBJ_TRACK_MOTION_MODEL_060 OBJ_DIMENSION_WIDTH_060 OBJ_DIMENSION_LENGTH_060 OBJ_EXISTENCE_PROB_060 OBJ_YAW_ANGLE_060 OBJ_YAW_ANGLE_ERR_060 OBJ_ID_060 OBJ_MOVEMENT_STATUS_060 OBJ_MEASUREMENT_STATUS_060 OBJ_POS_LONG_060 OBJ_POS_LAT_060 OBJ_VELOCITY_LONG_060 OBJ_VELOCITY_LAT_060 OBJ_ACCELERATION_LONG_060 OBJ_ACCELERATION_LAT_060 OBJ_VEH_TRACK_FLAG_060 OBJ_MH_CYCLE_COUNTER_060 OBJ_MH_CRC16_060 OBJ_TIMESTAMP_OFFSET_060 OBJ_DIMENSION_WIDTH_ERR_060 OBJ_DIMENSION_LENGTH_ERR_060 OBJ_CLS_TYPE1_060 OBJ_CLS_TYPE1_PROB_060 OBJ_CLS_TYPE2_060 OBJ_CLS_TYPE2_PROB_060 OBJ_CLS_TYPE3_060 OBJ_CLS_TYPE3_PROB_060 OBJ_CLS_TYPE4_060 OBJ_CLS_TYPE4_PROB_060 OBJ_CLS_TYPE5_060 OBJ_CLS_TYPE5_PROB_060 OBJ_CLS_TYPE6_060 OBJ_CLS_TYPE6_PROB_060 OBJ_RCS_060 OBJ_REF_PT_LONG_OFFSET_060 OBJ_REF_PT_LAT_OFFSET_060 OBJ_YAW_RATE_060 OBJ_YAW_RATE_ERR_060 OBJ_GROUP_ID_060 OBJ_POS_ERR_CRR_COEF_060 OBJ_VELOCITY_ERR_CRR_COEF_060 OBJ_ACCEL_ERR_CRR_COEF_060;
SIG_GROUP_ 1612 TrackerObject061 1 : OBJ_ALIVE_TIME_061 OBJ_ACCELERATION_LONG_ERR_061 OBJ_ACCELERATION_LAT_ERR_061 OBJ_VELOCITY_LONG_ERR_061 OBJ_VELOCITY_LAT_ERR_061 OBJ_POS_LONG_ERR_061 OBJ_POS_LAT_ERR_061 OBJ_TRACK_MOTION_MODEL_061 OBJ_DIMENSION_WIDTH_061 OBJ_DIMENSION_LENGTH_061 OBJ_EXISTENCE_PROB_061 OBJ_YAW_ANGLE_061 OBJ_YAW_ANGLE_ERR_061 OBJ_ID_061 OBJ_MOVEMENT_STATUS_061 OBJ_MEASUREMENT_STATUS_061 OBJ_POS_LONG_061 OBJ_POS_LAT_061 OBJ_VELOCITY_LONG_061 OBJ_VELOCITY_LAT_061 OBJ_ACCELERATION_LONG_061 OBJ_ACCELERATION_LAT_061 OBJ_VEH_TRACK_FLAG_061 OBJ_MH_CYCLE_COUNTER_061 OBJ_MH_CRC16_061 OBJ_TIMESTAMP_OFFSET_061 OBJ_DIMENSION_WIDTH_ERR_061 OBJ_DIMENSION_LENGTH_ERR_061 OBJ_CLS_TYPE1_061 OBJ_CLS_TYPE1_PROB_061 OBJ_CLS_TYPE2_061 OBJ_CLS_TYPE2_PROB_061 OBJ_CLS_TYPE3_061 OBJ_CLS_TYPE3_PROB_061 OBJ_CLS_TYPE4_061 OBJ_CLS_TYPE4_PROB_061 OBJ_CLS_TYPE5_061 OBJ_CLS_TYPE5_PROB_061 OBJ_CLS_TYPE6_061 OBJ_CLS_TYPE6_PROB_061 OBJ_RCS_061 OBJ_REF_PT_LONG_OFFSET_061 OBJ_REF_PT_LAT_OFFSET_061 OBJ_YAW_RATE_061 OBJ_YAW_RATE_ERR_061 OBJ_GROUP_ID_061 OBJ_POS_ERR_CRR_COEF_061 OBJ_VELOCITY_ERR_CRR_COEF_061 OBJ_ACCEL_ERR_CRR_COEF_061;
SIG_GROUP_ 1613 TrackerObject062 1 : OBJ_ALIVE_TIME_062 OBJ_ACCELERATION_LONG_ERR_062 OBJ_ACCELERATION_LAT_ERR_062 OBJ_VELOCITY_LONG_ERR_062 OBJ_VELOCITY_LAT_ERR_062 OBJ_POS_LONG_ERR_062 OBJ_POS_LAT_ERR_062 OBJ_TRACK_MOTION_MODEL_062 OBJ_DIMENSION_WIDTH_062 OBJ_DIMENSION_LENGTH_062 OBJ_EXISTENCE_PROB_062 OBJ_YAW_ANGLE_062 OBJ_YAW_ANGLE_ERR_062 OBJ_ID_062 OBJ_MOVEMENT_STATUS_062 OBJ_MEASUREMENT_STATUS_062 OBJ_POS_LONG_062 OBJ_POS_LAT_062 OBJ_VELOCITY_LONG_062 OBJ_VELOCITY_LAT_062 OBJ_ACCELERATION_LONG_062 OBJ_ACCELERATION_LAT_062 OBJ_VEH_TRACK_FLAG_062 OBJ_MH_CYCLE_COUNTER_062 OBJ_MH_CRC16_062 OBJ_TIMESTAMP_OFFSET_062 OBJ_DIMENSION_WIDTH_ERR_062 OBJ_DIMENSION_LENGTH_ERR_062 OBJ_CLS_TYPE1_062 OBJ_CLS_TYPE1_PROB_062 OBJ_CLS_TYPE2_062 OBJ_CLS_TYPE2_PROB_062 OBJ_CLS_TYPE3_062 OBJ_CLS_TYPE3_PROB_062 OBJ_CLS_TYPE4_062 OBJ_CLS_TYPE4_PROB_062 OBJ_CLS_TYPE5_062 OBJ_CLS_TYPE5_PROB_062 OBJ_CLS_TYPE6_062 OBJ_CLS_TYPE6_PROB_062 OBJ_RCS_062 OBJ_REF_PT_LONG_OFFSET_062 OBJ_REF_PT_LAT_OFFSET_062 OBJ_YAW_RATE_062 OBJ_YAW_RATE_ERR_062 OBJ_GROUP_ID_062 OBJ_POS_ERR_CRR_COEF_062 OBJ_VELOCITY_ERR_CRR_COEF_062 OBJ_ACCEL_ERR_CRR_COEF_062;
SIG_GROUP_ 1614 TrackerObject063 1 : OBJ_ALIVE_TIME_063 OBJ_ACCELERATION_LONG_ERR_063 OBJ_ACCELERATION_LAT_ERR_063 OBJ_VELOCITY_LONG_ERR_063 OBJ_VELOCITY_LAT_ERR_063 OBJ_POS_LONG_ERR_063 OBJ_POS_LAT_ERR_063 OBJ_TRACK_MOTION_MODEL_063 OBJ_DIMENSION_WIDTH_063 OBJ_DIMENSION_LENGTH_063 OBJ_EXISTENCE_PROB_063 OBJ_YAW_ANGLE_063 OBJ_YAW_ANGLE_ERR_063 OBJ_ID_063 OBJ_MOVEMENT_STATUS_063 OBJ_MEASUREMENT_STATUS_063 OBJ_POS_LONG_063 OBJ_POS_LAT_063 OBJ_VELOCITY_LONG_063 OBJ_VELOCITY_LAT_063 OBJ_ACCELERATION_LONG_063 OBJ_ACCELERATION_LAT_063 OBJ_VEH_TRACK_FLAG_063 OBJ_MH_CYCLE_COUNTER_063 OBJ_MH_CRC16_063 OBJ_TIMESTAMP_OFFSET_063 OBJ_DIMENSION_WIDTH_ERR_063 OBJ_DIMENSION_LENGTH_ERR_063 OBJ_CLS_TYPE1_063 OBJ_CLS_TYPE1_PROB_063 OBJ_CLS_TYPE2_063 OBJ_CLS_TYPE2_PROB_063 OBJ_CLS_TYPE3_063 OBJ_CLS_TYPE3_PROB_063 OBJ_CLS_TYPE4_063 OBJ_CLS_TYPE4_PROB_063 OBJ_CLS_TYPE5_063 OBJ_CLS_TYPE5_PROB_063 OBJ_CLS_TYPE6_063 OBJ_CLS_TYPE6_PROB_063 OBJ_RCS_063 OBJ_REF_PT_LONG_OFFSET_063 OBJ_REF_PT_LAT_OFFSET_063 OBJ_YAW_RATE_063 OBJ_YAW_RATE_ERR_063 OBJ_GROUP_ID_063 OBJ_POS_ERR_CRR_COEF_063 OBJ_VELOCITY_ERR_CRR_COEF_063 OBJ_ACCEL_ERR_CRR_COEF_063;
SIG_GROUP_ 1615 TrackerObject064 1 : OBJ_ALIVE_TIME_064 OBJ_ACCELERATION_LONG_ERR_064 OBJ_ACCELERATION_LAT_ERR_064 OBJ_VELOCITY_LONG_ERR_064 OBJ_VELOCITY_LAT_ERR_064 OBJ_POS_LONG_ERR_064 OBJ_POS_LAT_ERR_064 OBJ_TRACK_MOTION_MODEL_064 OBJ_DIMENSION_WIDTH_064 OBJ_DIMENSION_LENGTH_064 OBJ_EXISTENCE_PROB_064 OBJ_YAW_ANGLE_064 OBJ_YAW_ANGLE_ERR_064 OBJ_ID_064 OBJ_MOVEMENT_STATUS_064 OBJ_MEASUREMENT_STATUS_064 OBJ_POS_LONG_064 OBJ_POS_LAT_064 OBJ_VELOCITY_LONG_064 OBJ_VELOCITY_LAT_064 OBJ_ACCELERATION_LONG_064 OBJ_ACCELERATION_LAT_064 OBJ_VEH_TRACK_FLAG_064 OBJ_MH_CYCLE_COUNTER_064 OBJ_MH_CRC16_064 OBJ_TIMESTAMP_OFFSET_064 OBJ_DIMENSION_WIDTH_ERR_064 OBJ_DIMENSION_LENGTH_ERR_064 OBJ_CLS_TYPE1_064 OBJ_CLS_TYPE1_PROB_064 OBJ_CLS_TYPE2_064 OBJ_CLS_TYPE2_PROB_064 OBJ_CLS_TYPE3_064 OBJ_CLS_TYPE3_PROB_064 OBJ_CLS_TYPE4_064 OBJ_CLS_TYPE4_PROB_064 OBJ_CLS_TYPE5_064 OBJ_CLS_TYPE5_PROB_064 OBJ_CLS_TYPE6_064 OBJ_CLS_TYPE6_PROB_064 OBJ_RCS_064 OBJ_REF_PT_LONG_OFFSET_064 OBJ_REF_PT_LAT_OFFSET_064 OBJ_YAW_RATE_064 OBJ_YAW_RATE_ERR_064 OBJ_GROUP_ID_064 OBJ_POS_ERR_CRR_COEF_064 OBJ_VELOCITY_ERR_CRR_COEF_064 OBJ_ACCEL_ERR_CRR_COEF_064;
SIG_GROUP_ 161 TrackerHeader 1 : HED_TRKR_VEHICLE_IDX HED_MH_002_CYCLE_COUNTER HED_MH_002_CRC16 HED_TRKR_IDX HED_TRKR_TIME_PEAK HED_TRKR_TIME_INST HED_TRKR_OBJLST_TIME_STAMP_NS HED_TRKR_OBJLST_TIME_STAMP_SC HED_TRKR_VEH_COORD_TYPE HED_TRKR_NUM_OF_ACTIV_OBJS HED_TRKR_DATA_QUALIFIER;
SIG_GROUP_ 162 TrackerStatus 1 : STS_TRKR_PATCH_VERSION STS_TRKR_MINOR_VERSION STS_TRKR_MAJOR_VERSION STS_PERCEPTION_MODULE_ID STS_OBJ_DBC_BASE_VER_MINOR STS_OBJ_DBC_BASE_VER_MAJOR STS_MH_003_CRC16 STS_MH_003_CYCLE_COUNTER;
SIG_GROUP_ 128 Fusion_RadarHeader 1 : HED_RDR_HEADER_CMAC_Rx HED_RDR_HEADER_FV_Rx HED_Rain_Level_Rx HED_MH_CRC16_Rx HED_MH_CYCLE_COUNTER_Rx HED_Auth_CRC32_Rx HED_FOV_VER_MIN_Rx HED_FOV_HOR_MIN_Rx HED_DET_SPEED_RANGE_MIN_Rx HED_DET_RANGE_MIN_Rx HED_FOV_VER_MAX_Rx HED_FOV_HOR_MAX_Rx HED_DET_SPEED_RANGE_MAX_Rx HED_DET_RANGE_MAX_Rx HED_R_WRAPPING_Rx HED_V_WRAPPING_Rx HED_DATA_QUALIFIER_Rx HED_SCAN_INDEX_Rx HED_LOOK_ID_Rx HED_NUM_OF_VALID_DETECTIONS_Rx HED_ALIGN_HOR_REF_Rx HED_LOOK_INDEX_Rx HED_ALIGN_VER_REF_Rx HED_TRIGGER_TIME_Rx HED_TIME_SYNC_VALIDITY_FLAG_Rx HED_TIME_SYNC_SRC_MASTER_Rx HED_SENSOR_TIME_STAMP_NS_Rx HED_SENSOR_TIME_STAMP_SEC_Rx HED_DET_BI_STATIC_COUNT_Rx HED_DET_NUM_OF_2PASS_Rx HED_DET_NUM_OF_1PASS_Rx HED_NUM_OF_RESTBINS_USED_Rx HED_MAX_NUM_OF_DETECTIONS_Rx HED_OPERATION_MODE_Rx HED_PROCESSED_RANGE_Rx HED_SLOPE_CORR_EXECUTIONFLAG_Rx;
SIG_GROUP_ 131 Fusion_RadarStatus 1 : STS_DIST_FRNT_BMPR_TO_RR_AXL_Rx STS_VIN_Status_Rx STS_MH_001_CYCLE_COUNTER_Rx STS_MH_001_CRC16_Rx STS_SMC_PLATFROM_VERSION_Rx STS_SMC_SECTION_COMPTBLITY_Rx STS_SMC_CAL_VER_MINOR_Rx STS_SMC_CAL_VER_MAJOR_Rx STS_USC_SECTION_COMPTBLITY_Rx STS_USC_CAL_VER_MINOR_Rx STS_USC_CAL_VER_MAJOR_Rx STS_SENSOR_POSITION_Rx STS_SENSOR_HEIGHT_Rx STS_SENSOR_MOUNT_ORNT_ROLL_Rx STS_SENSOR_MOUNT_ORNT_PITCH_Rx STS_SENSOR_MOUNT_ORNT_YAW_Rx STS_SENSOR_MOUNT_POS_Z_Rx STS_SENSOR_MOUNT_POS_Y_Rx STS_SENSOR_MOUNT_POS_X_Rx STS_SENSOR_POLARITY_Rx STS_PBL_VERSION_FIELD4_Rx STS_PBL_VERSION_FIELD3_Rx STS_PBL_VERSION_FIELD2_Rx STS_PBL_VERSION_FIELD1_Rx STS_SW_VERSION_FIELD4_Rx STS_SW_VERSION_FIELD3_Rx STS_SW_VERSION_FIELD2_Rx STS_SW_VERSION_FIELD1_Rx STS_DET_DBC_BASE_VER_MAJOR_Rx STS_DET_DBC_BASE_VER_MINOR_Rx STS_SERIAL_NUM_JULIAN_DAY_Rx STS_SERIAL_NUM_JULIAN_YEAR_Rx STS_SERIAL_NUMBER_SEQUENCE_Rx STS_HARDWARE_VERSION_Rx STS_PCAN_PROTOCOL_VER_MAJOR_Rx STS_PLATFORM_VARIANT_Rx STS_PCAN_PROTOCOL_VER_MINOR_Rx STS_TIME_SINCE_POWER_ON_Rx STS_AF_TIME_INST_Rx STS_AF_TIME_PEAK_Rx STS_MAIN_CORE_TIME_INST_Rx STS_MAIN_CORE_TIME_PEAK_Rx STS_RDD_CORE_TIME_INST_Rx STS_RDD_CORE_TIME_PEAK_Rx STS_SP_CORE_TIME_INST_Rx STS_SP_CORE_TIME_PEAK_Rx;
SIG_GROUP_ 256 Fusion_Detections_001_004 1 : DET_PROB_1STAZHYPO_001_Rx DET_PROB_1STAZHYPO_002_Rx DET_PROB_1STAZHYPO_003_Rx DET_PROB_1STAZHYPO_004_Rx DET_IDM_001_Rx DET_IDM_002_Rx DET_IDM_003_Rx DET_IDM_004_Rx DET_MTD_004_Rx DET_MTD_003_Rx DET_MTD_002_Rx DET_MTD_001_Rx DET_BELOW_RAIN_THOLD_004_Rx DET_BELOW_RAIN_THOLD_003_Rx DET_BELOW_RAIN_THOLD_002_Rx DET_BELOW_RAIN_THOLD_001_Rx DET_MH_CRC16_001_004_Rx DET_MH_CYCLE_COUNTER_001_004_Rx DET_MH_SCAN_INDEX_4LSB_001_004_R DET_CONFD_ELEVATION_001_Rx DET_CONFD_AZIMUTH_001_Rx DET_HVC_FLAG_001_Rx DET_EXISTENCE_PROB_001_Rx DET_SNR_001_Rx DET_SUPER_RES_TARGET_001_Rx DET_BI_STATIC_FLAG_001_Rx DET_RCS_001_Rx DET_ELEVATION_ERR_001_Rx DET_ELEVATION_001_Rx DET_AZIMUTH_ERR_001_Rx DET_AZIMUTH_001_Rx DET_RANGE_VELOCITY_ERR_001_Rx DET_RANGE_VELOCITY_001_Rx DET_RANGE_ERR_001_Rx DET_RANGE_001_Rx DET_CONFD_ELEVATION_002_Rx DET_CONFD_AZIMUTH_002_Rx DET_HVC_FLAG_002_Rx DET_EXISTENCE_PROB_002_Rx DET_SNR_002_Rx DET_SUPER_RES_TARGET_002_Rx DET_BI_STATIC_FLAG_002_Rx DET_RCS_002_Rx DET_ELEVATION_ERR_002_Rx DET_ELEVATION_002_Rx DET_AZIMUTH_ERR_002_Rx DET_AZIMUTH_002_Rx DET_RANGE_VELOCITY_ERR_002_Rx DET_RANGE_VELOCITY_002_Rx DET_RANGE_ERR_002_Rx DET_RANGE_002_Rx DET_CONFD_ELEVATION_003_Rx DET_CONFD_AZIMUTH_003_Rx DET_HVC_FLAG_003_Rx DET_EXISTENCE_PROB_003_Rx DET_SNR_003_Rx DET_SUPER_RES_TARGET_003_Rx DET_BI_STATIC_FLAG_003_Rx DET_RCS_003_Rx DET_ELEVATION_ERR_003_Rx DET_ELEVATION_003_Rx DET_AZIMUTH_ERR_003_Rx DET_AZIMUTH_003_Rx DET_RANGE_VELOCITY_ERR_003_Rx DET_RANGE_VELOCITY_003_Rx DET_RANGE_ERR_003_Rx DET_RANGE_003_Rx DET_CONFD_ELEVATION_004_Rx DET_CONFD_AZIMUTH_004_Rx DET_HVC_FLAG_004_Rx DET_EXISTENCE_PROB_004_Rx DET_SNR_004_Rx DET_SUPER_RES_TARGET_004_Rx DET_BI_STATIC_FLAG_004_Rx DET_RCS_004_Rx DET_ELEVATION_ERR_004_Rx DET_ELEVATION_004_Rx DET_AZIMUTH_ERR_004_Rx DET_AZIMUTH_004_Rx DET_RANGE_VELOCITY_ERR_004_Rx DET_RANGE_VELOCITY_004_Rx DET_RANGE_ERR_004_Rx DET_RANGE_004_Rx;
SIG_GROUP_ 257 Fusion_Detections_005_008 1 : DET_PROB_1STAZHYPO_005_Rx DET_PROB_1STAZHYPO_006_Rx DET_PROB_1STAZHYPO_007_Rx DET_PROB_1STAZHYPO_008_Rx DET_IDM_005_Rx DET_IDM_006_Rx DET_IDM_007_Rx DET_IDM_008_Rx DET_MTD_008_Rx DET_MTD_007_Rx DET_MTD_006_Rx DET_MTD_005_Rx DET_BELOW_RAIN_THOLD_008_Rx DET_BELOW_RAIN_THOLD_007_Rx DET_BELOW_RAIN_THOLD_006_Rx DET_BELOW_RAIN_THOLD_005_Rx DET_MH_CRC16_005_008_Rx DET_MH_CYCLE_COUNTER_005_008_Rx DET_MH_SCAN_INDEX_4LSB_005_008_R DET_CONFD_ELEVATION_005_Rx DET_CONFD_AZIMUTH_005_Rx DET_HVC_FLAG_005_Rx DET_EXISTENCE_PROB_005_Rx DET_SNR_005_Rx DET_SUPER_RES_TARGET_005_Rx DET_BI_STATIC_FLAG_005_Rx DET_RCS_005_Rx DET_ELEVATION_ERR_005_Rx DET_ELEVATION_005_Rx DET_AZIMUTH_ERR_005_Rx DET_AZIMUTH_005_Rx DET_RANGE_VELOCITY_ERR_005_Rx DET_RANGE_VELOCITY_005_Rx DET_RANGE_ERR_005_Rx DET_RANGE_005_Rx DET_CONFD_ELEVATION_006_Rx DET_CONFD_AZIMUTH_006_Rx DET_HVC_FLAG_006_Rx DET_EXISTENCE_PROB_006_Rx DET_SNR_006_Rx DET_SUPER_RES_TARGET_006_Rx DET_BI_STATIC_FLAG_006_Rx DET_RCS_006_Rx DET_ELEVATION_ERR_006_Rx DET_ELEVATION_006_Rx DET_AZIMUTH_ERR_006_Rx DET_AZIMUTH_006_Rx DET_RANGE_VELOCITY_ERR_006_Rx DET_RANGE_VELOCITY_006_Rx DET_RANGE_ERR_006_Rx DET_RANGE_006_Rx DET_CONFD_ELEVATION_007_Rx DET_CONFD_AZIMUTH_007_Rx DET_HVC_FLAG_007_Rx DET_EXISTENCE_PROB_007_Rx DET_SNR_007_Rx DET_SUPER_RES_TARGET_007_Rx DET_BI_STATIC_FLAG_007_Rx DET_RCS_007_Rx DET_ELEVATION_ERR_007_Rx DET_ELEVATION_007_Rx DET_AZIMUTH_ERR_007_Rx DET_AZIMUTH_007_Rx DET_RANGE_VELOCITY_ERR_007_Rx DET_RANGE_VELOCITY_007_Rx DET_RANGE_ERR_007_Rx DET_RANGE_007_Rx DET_CONFD_ELEVATION_008_Rx DET_CONFD_AZIMUTH_008_Rx DET_HVC_FLAG_008_Rx DET_EXISTENCE_PROB_008_Rx DET_SNR_008_Rx DET_SUPER_RES_TARGET_008_Rx DET_BI_STATIC_FLAG_008_Rx DET_RCS_008_Rx DET_ELEVATION_ERR_008_Rx DET_ELEVATION_008_Rx DET_AZIMUTH_ERR_008_Rx DET_AZIMUTH_008_Rx DET_RANGE_VELOCITY_ERR_008_Rx DET_RANGE_VELOCITY_008_Rx DET_RANGE_ERR_008_Rx DET_RANGE_008_Rx;
SIG_GROUP_ 258 Fusion_Detections_009_012 1 : DET_PROB_1STAZHYPO_009_Rx DET_PROB_1STAZHYPO_010_Rx DET_PROB_1STAZHYPO_011_Rx DET_PROB_1STAZHYPO_012_Rx DET_IDM_009_Rx DET_IDM_010_Rx DET_IDM_011_Rx DET_IDM_012_Rx DET_MTD_012_Rx DET_MTD_011_Rx DET_MTD_010_Rx DET_MTD_009_Rx DET_BELOW_RAIN_THOLD_012_Rx DET_BELOW_RAIN_THOLD_011_Rx DET_BELOW_RAIN_THOLD_010_Rx DET_BELOW_RAIN_THOLD_009_Rx DET_MH_CRC16_009_012_Rx DET_MH_CYCLE_COUNTER_009_012_Rx DET_MH_SCAN_INDEX_4LSB_009_012_R DET_CONFD_ELEVATION_009_Rx DET_CONFD_AZIMUTH_009_Rx DET_HVC_FLAG_009_Rx DET_EXISTENCE_PROB_009_Rx DET_SNR_009_Rx DET_SUPER_RES_TARGET_009_Rx DET_BI_STATIC_FLAG_009_Rx DET_RCS_009_Rx DET_ELEVATION_ERR_009_Rx DET_ELEVATION_009_Rx DET_AZIMUTH_ERR_009_Rx DET_AZIMUTH_009_Rx DET_RANGE_VELOCITY_ERR_009_Rx DET_RANGE_VELOCITY_009_Rx DET_RANGE_ERR_009_Rx DET_RANGE_009_Rx DET_CONFD_ELEVATION_010_Rx DET_CONFD_AZIMUTH_010_Rx DET_HVC_FLAG_010_Rx DET_EXISTENCE_PROB_010_Rx DET_SNR_010_Rx DET_SUPER_RES_TARGET_010_Rx DET_BI_STATIC_FLAG_010_Rx DET_RCS_010_Rx DET_ELEVATION_ERR_010_Rx DET_ELEVATION_010_Rx DET_AZIMUTH_ERR_010_Rx DET_AZIMUTH_010_Rx DET_RANGE_VELOCITY_ERR_010_Rx DET_RANGE_VELOCITY_010_Rx DET_RANGE_ERR_010_Rx DET_RANGE_010_Rx DET_CONFD_ELEVATION_011_Rx DET_CONFD_AZIMUTH_011_Rx DET_HVC_FLAG_011_Rx DET_EXISTENCE_PROB_011_Rx DET_SNR_011_Rx DET_SUPER_RES_TARGET_011_Rx DET_BI_STATIC_FLAG_011_Rx DET_RCS_011_Rx DET_ELEVATION_ERR_011_Rx DET_ELEVATION_011_Rx DET_AZIMUTH_ERR_011_Rx DET_AZIMUTH_011_Rx DET_RANGE_VELOCITY_ERR_011_Rx DET_RANGE_VELOCITY_011_Rx DET_RANGE_ERR_011_Rx DET_RANGE_011_Rx DET_CONFD_ELEVATION_012_Rx DET_CONFD_AZIMUTH_012_Rx DET_HVC_FLAG_012_Rx DET_EXISTENCE_PROB_012_Rx DET_SNR_012_Rx DET_SUPER_RES_TARGET_012_Rx DET_BI_STATIC_FLAG_012_Rx DET_RCS_012_Rx DET_ELEVATION_ERR_012_Rx DET_ELEVATION_012_Rx DET_AZIMUTH_ERR_012_Rx DET_AZIMUTH_012_Rx DET_RANGE_VELOCITY_ERR_012_Rx DET_RANGE_VELOCITY_012_Rx DET_RANGE_ERR_012_Rx DET_RANGE_012_Rx;
SIG_GROUP_ 259 Fusion_Detections_013_016 1 : DET_PROB_1STAZHYPO_013_Rx DET_PROB_1STAZHYPO_014_Rx DET_PROB_1STAZHYPO_015_Rx DET_PROB_1STAZHYPO_016_Rx DET_IDM_013_Rx DET_IDM_014_Rx DET_IDM_015_Rx DET_IDM_016_Rx DET_MTD_016_Rx DET_MTD_015_Rx DET_MTD_014_Rx DET_MTD_013_Rx DET_BELOW_RAIN_THOLD_016_Rx DET_BELOW_RAIN_THOLD_015_Rx DET_BELOW_RAIN_THOLD_014_Rx DET_BELOW_RAIN_THOLD_013_Rx DET_MH_CRC16_013_016_Rx DET_MH_CYCLE_COUNTER_013_016_Rx DET_MH_SCAN_INDEX_4LSB_013_016_R DET_CONFD_ELEVATION_013_Rx DET_CONFD_AZIMUTH_013_Rx DET_HVC_FLAG_013_Rx DET_EXISTENCE_PROB_013_Rx DET_SNR_013_Rx DET_SUPER_RES_TARGET_013_Rx DET_BI_STATIC_FLAG_013_Rx DET_RCS_013_Rx DET_ELEVATION_ERR_013_Rx DET_ELEVATION_013_Rx DET_AZIMUTH_ERR_013_Rx DET_AZIMUTH_013_Rx DET_RANGE_VELOCITY_ERR_013_Rx DET_RANGE_VELOCITY_013_Rx DET_RANGE_ERR_013_Rx DET_RANGE_013_Rx DET_CONFD_ELEVATION_014_Rx DET_CONFD_AZIMUTH_014_Rx DET_HVC_FLAG_014_Rx DET_EXISTENCE_PROB_014_Rx DET_SNR_014_Rx DET_SUPER_RES_TARGET_014_Rx DET_BI_STATIC_FLAG_014_Rx DET_RCS_014_Rx DET_ELEVATION_ERR_014_Rx DET_ELEVATION_014_Rx DET_AZIMUTH_ERR_014_Rx DET_AZIMUTH_014_Rx DET_RANGE_VELOCITY_ERR_014_Rx DET_RANGE_VELOCITY_014_Rx DET_RANGE_ERR_014_Rx DET_RANGE_014_Rx DET_CONFD_ELEVATION_015_Rx DET_CONFD_AZIMUTH_015_Rx DET_HVC_FLAG_015_Rx DET_EXISTENCE_PROB_015_Rx DET_SNR_015_Rx DET_SUPER_RES_TARGET_015_Rx DET_BI_STATIC_FLAG_015_Rx DET_RCS_015_Rx DET_ELEVATION_ERR_015_Rx DET_ELEVATION_015_Rx DET_AZIMUTH_ERR_015_Rx DET_AZIMUTH_015_Rx DET_RANGE_VELOCITY_ERR_015_Rx DET_RANGE_VELOCITY_015_Rx DET_RANGE_ERR_015_Rx DET_RANGE_015_Rx DET_CONFD_ELEVATION_016_Rx DET_CONFD_AZIMUTH_016_Rx DET_HVC_FLAG_016_Rx DET_EXISTENCE_PROB_016_Rx DET_SNR_016_Rx DET_SUPER_RES_TARGET_016_Rx DET_BI_STATIC_FLAG_016_Rx DET_RCS_016_Rx DET_ELEVATION_ERR_016_Rx DET_ELEVATION_016_Rx DET_AZIMUTH_ERR_016_Rx DET_AZIMUTH_016_Rx DET_RANGE_VELOCITY_ERR_016_Rx DET_RANGE_VELOCITY_016_Rx DET_RANGE_ERR_016_Rx DET_RANGE_016_Rx;
SIG_GROUP_ 260 Fusion_Detections_017_020 1 : DET_PROB_1STAZHYPO_017_Rx DET_PROB_1STAZHYPO_018_Rx DET_PROB_1STAZHYPO_019_Rx DET_PROB_1STAZHYPO_020_Rx DET_IDM_017_Rx DET_IDM_018_Rx DET_IDM_019_Rx DET_IDM_020_Rx DET_MTD_020_Rx DET_MTD_019_Rx DET_MTD_018_Rx DET_MTD_017_Rx DET_BELOW_RAIN_THOLD_020_Rx DET_BELOW_RAIN_THOLD_019_Rx DET_BELOW_RAIN_THOLD_018_Rx DET_BELOW_RAIN_THOLD_017_Rx DET_MH_CRC16_017_020_Rx DET_MH_CYCLE_COUNTER_017_020_Rx DET_MH_SCAN_INDEX_4LSB_017_020_R DET_CONFD_ELEVATION_017_Rx DET_CONFD_AZIMUTH_017_Rx DET_HVC_FLAG_017_Rx DET_EXISTENCE_PROB_017_Rx DET_SNR_017_Rx DET_SUPER_RES_TARGET_017_Rx DET_BI_STATIC_FLAG_017_Rx DET_RCS_017_Rx DET_ELEVATION_ERR_017_Rx DET_ELEVATION_017_Rx DET_AZIMUTH_ERR_017_Rx DET_AZIMUTH_017_Rx DET_RANGE_VELOCITY_ERR_017_Rx DET_RANGE_VELOCITY_017_Rx DET_RANGE_ERR_017_Rx DET_RANGE_017_Rx DET_CONFD_ELEVATION_018_Rx DET_CONFD_AZIMUTH_018_Rx DET_HVC_FLAG_018_Rx DET_EXISTENCE_PROB_018_Rx DET_SNR_018_Rx DET_SUPER_RES_TARGET_018_Rx DET_BI_STATIC_FLAG_018_Rx DET_RCS_018_Rx DET_ELEVATION_ERR_018_Rx DET_ELEVATION_018_Rx DET_AZIMUTH_ERR_018_Rx DET_AZIMUTH_018_Rx DET_RANGE_VELOCITY_ERR_018_Rx DET_RANGE_VELOCITY_018_Rx DET_RANGE_ERR_018_Rx DET_RANGE_018_Rx DET_CONFD_ELEVATION_019_Rx DET_CONFD_AZIMUTH_019_Rx DET_HVC_FLAG_019_Rx DET_EXISTENCE_PROB_019_Rx DET_SNR_019_Rx DET_SUPER_RES_TARGET_019_Rx DET_BI_STATIC_FLAG_019_Rx DET_RCS_019_Rx DET_ELEVATION_ERR_019_Rx DET_ELEVATION_019_Rx DET_AZIMUTH_ERR_019_Rx DET_AZIMUTH_019_Rx DET_RANGE_VELOCITY_ERR_019_Rx DET_RANGE_VELOCITY_019_Rx DET_RANGE_ERR_019_Rx DET_RANGE_019_Rx DET_CONFD_ELEVATION_020_Rx DET_CONFD_AZIMUTH_020_Rx DET_HVC_FLAG_020_Rx DET_EXISTENCE_PROB_020_Rx DET_SNR_020_Rx DET_SUPER_RES_TARGET_020_Rx DET_BI_STATIC_FLAG_020_Rx DET_RCS_020_Rx DET_ELEVATION_ERR_020_Rx DET_ELEVATION_020_Rx DET_AZIMUTH_ERR_020_Rx DET_AZIMUTH_020_Rx DET_RANGE_VELOCITY_ERR_020_Rx DET_RANGE_VELOCITY_020_Rx DET_RANGE_ERR_020_Rx DET_RANGE_020_Rx;
SIG_GROUP_ 261 Fusion_Detections_021_024 1 : DET_PROB_1STAZHYPO_021_Rx DET_PROB_1STAZHYPO_022_Rx DET_PROB_1STAZHYPO_023_Rx DET_PROB_1STAZHYPO_024_Rx DET_IDM_021_Rx DET_IDM_022_Rx DET_IDM_023_Rx DET_IDM_024_Rx DET_MTD_024_Rx DET_MTD_023_Rx DET_MTD_022_Rx DET_MTD_021_Rx DET_BELOW_RAIN_THOLD_024_Rx DET_BELOW_RAIN_THOLD_023_Rx DET_BELOW_RAIN_THOLD_022_Rx DET_BELOW_RAIN_THOLD_021_Rx DET_MH_CRC16_021_024_Rx DET_MH_CYCLE_COUNTER_021_024_Rx DET_MH_SCAN_INDEX_4LSB_021_024_R DET_CONFD_ELEVATION_021_Rx DET_CONFD_AZIMUTH_021_Rx DET_HVC_FLAG_021_Rx DET_EXISTENCE_PROB_021_Rx DET_SNR_021_Rx DET_SUPER_RES_TARGET_021_Rx DET_BI_STATIC_FLAG_021_Rx DET_RCS_021_Rx DET_ELEVATION_ERR_021_Rx DET_ELEVATION_021_Rx DET_AZIMUTH_ERR_021_Rx DET_AZIMUTH_021_Rx DET_RANGE_VELOCITY_ERR_021_Rx DET_RANGE_VELOCITY_021_Rx DET_RANGE_ERR_021_Rx DET_RANGE_021_Rx DET_CONFD_ELEVATION_022_Rx DET_CONFD_AZIMUTH_022_Rx DET_HVC_FLAG_022_Rx DET_EXISTENCE_PROB_022_Rx DET_SNR_022_Rx DET_SUPER_RES_TARGET_022_Rx DET_BI_STATIC_FLAG_022_Rx DET_RCS_022_Rx DET_ELEVATION_ERR_022_Rx DET_ELEVATION_022_Rx DET_AZIMUTH_ERR_022_Rx DET_AZIMUTH_022_Rx DET_RANGE_VELOCITY_ERR_022_Rx DET_RANGE_VELOCITY_022_Rx DET_RANGE_ERR_022_Rx DET_RANGE_022_Rx DET_CONFD_ELEVATION_023_Rx DET_CONFD_AZIMUTH_023_Rx DET_HVC_FLAG_023_Rx DET_EXISTENCE_PROB_023_Rx DET_SNR_023_Rx DET_SUPER_RES_TARGET_023_Rx DET_BI_STATIC_FLAG_023_Rx DET_RCS_023_Rx DET_ELEVATION_ERR_023_Rx DET_ELEVATION_023_Rx DET_AZIMUTH_ERR_023_Rx DET_AZIMUTH_023_Rx DET_RANGE_VELOCITY_ERR_023_Rx DET_RANGE_VELOCITY_023_Rx DET_RANGE_ERR_023_Rx DET_RANGE_023_Rx DET_CONFD_ELEVATION_024_Rx DET_CONFD_AZIMUTH_024_Rx DET_HVC_FLAG_024_Rx DET_EXISTENCE_PROB_024_Rx DET_SNR_024_Rx DET_SUPER_RES_TARGET_024_Rx DET_BI_STATIC_FLAG_024_Rx DET_RCS_024_Rx DET_ELEVATION_ERR_024_Rx DET_ELEVATION_024_Rx DET_AZIMUTH_ERR_024_Rx DET_AZIMUTH_024_Rx DET_RANGE_VELOCITY_ERR_024_Rx DET_RANGE_VELOCITY_024_Rx DET_RANGE_ERR_024_Rx DET_RANGE_024_Rx;
SIG_GROUP_ 262 Fusion_Detections_025_028 1 : DET_PROB_1STAZHYPO_025_Rx DET_PROB_1STAZHYPO_026_Rx DET_PROB_1STAZHYPO_027_Rx DET_PROB_1STAZHYPO_028_Rx DET_IDM_025_Rx DET_IDM_026_Rx DET_IDM_027_Rx DET_IDM_028_Rx DET_MTD_028_Rx DET_MTD_027_Rx DET_MTD_026_Rx DET_MTD_025_Rx DET_BELOW_RAIN_THOLD_028_Rx DET_BELOW_RAIN_THOLD_027_Rx DET_BELOW_RAIN_THOLD_026_Rx DET_BELOW_RAIN_THOLD_025_Rx DET_MH_CRC16_025_028_Rx DET_MH_CYCLE_COUNTER_025_028_Rx DET_MH_SCAN_INDEX_4LSB_025_028_R DET_CONFD_ELEVATION_025_Rx DET_CONFD_AZIMUTH_025_Rx DET_HVC_FLAG_025_Rx DET_EXISTENCE_PROB_025_Rx DET_SNR_025_Rx DET_SUPER_RES_TARGET_025_Rx DET_BI_STATIC_FLAG_025_Rx DET_RCS_025_Rx DET_ELEVATION_ERR_025_Rx DET_ELEVATION_025_Rx DET_AZIMUTH_ERR_025_Rx DET_AZIMUTH_025_Rx DET_RANGE_VELOCITY_ERR_025_Rx DET_RANGE_VELOCITY_025_Rx DET_RANGE_ERR_025_Rx DET_RANGE_025_Rx DET_CONFD_ELEVATION_026_Rx DET_CONFD_AZIMUTH_026_Rx DET_HVC_FLAG_026_Rx DET_EXISTENCE_PROB_026_Rx DET_SNR_026_Rx DET_SUPER_RES_TARGET_026_Rx DET_BI_STATIC_FLAG_026_Rx DET_RCS_026_Rx DET_ELEVATION_ERR_026_Rx DET_ELEVATION_026_Rx DET_AZIMUTH_ERR_026_Rx DET_AZIMUTH_026_Rx DET_RANGE_VELOCITY_ERR_026_Rx DET_RANGE_VELOCITY_026_Rx DET_RANGE_ERR_026_Rx DET_RANGE_026_Rx DET_CONFD_ELEVATION_027_Rx DET_CONFD_AZIMUTH_027_Rx DET_HVC_FLAG_027_Rx DET_EXISTENCE_PROB_027_Rx DET_SNR_027_Rx DET_SUPER_RES_TARGET_027_Rx DET_BI_STATIC_FLAG_027_Rx DET_RCS_027_Rx DET_ELEVATION_ERR_027_Rx DET_ELEVATION_027_Rx DET_AZIMUTH_ERR_027_Rx DET_AZIMUTH_027_Rx DET_RANGE_VELOCITY_ERR_027_Rx DET_RANGE_VELOCITY_027_Rx DET_RANGE_ERR_027_Rx DET_RANGE_027_Rx DET_CONFD_ELEVATION_028_Rx DET_CONFD_AZIMUTH_028_Rx DET_HVC_FLAG_028_Rx DET_EXISTENCE_PROB_028_Rx DET_SNR_028_Rx DET_SUPER_RES_TARGET_028_Rx DET_BI_STATIC_FLAG_028_Rx DET_RCS_028_Rx DET_ELEVATION_ERR_028_Rx DET_ELEVATION_028_Rx DET_AZIMUTH_ERR_028_Rx DET_AZIMUTH_028_Rx DET_RANGE_VELOCITY_ERR_028_Rx DET_RANGE_VELOCITY_028_Rx DET_RANGE_ERR_028_Rx DET_RANGE_028_Rx;
SIG_GROUP_ 263 Fusion_Detections_029_032 1 : DET_PROB_1STAZHYPO_029_Rx DET_PROB_1STAZHYPO_030_Rx DET_PROB_1STAZHYPO_031_Rx DET_PROB_1STAZHYPO_032_Rx DET_IDM_029_Rx DET_IDM_030_Rx DET_IDM_031_Rx DET_IDM_032_Rx DET_MTD_032_Rx DET_MTD_031_Rx DET_MTD_030_Rx DET_MTD_029_Rx DET_BELOW_RAIN_THOLD_032_Rx DET_BELOW_RAIN_THOLD_031_Rx DET_BELOW_RAIN_THOLD_030_Rx DET_BELOW_RAIN_THOLD_029_Rx DET_MH_CRC16_029_032_Rx DET_MH_CYCLE_COUNTER_029_032_Rx DET_MH_SCAN_INDEX_4LSB_029_032_R DET_CONFD_ELEVATION_029_Rx DET_CONFD_AZIMUTH_029_Rx DET_HVC_FLAG_029_Rx DET_EXISTENCE_PROB_029_Rx DET_SNR_029_Rx DET_SUPER_RES_TARGET_029_Rx DET_BI_STATIC_FLAG_029_Rx DET_RCS_029_Rx DET_ELEVATION_ERR_029_Rx DET_ELEVATION_029_Rx DET_AZIMUTH_ERR_029_Rx DET_AZIMUTH_029_Rx DET_RANGE_VELOCITY_ERR_029_Rx DET_RANGE_VELOCITY_029_Rx DET_RANGE_ERR_029_Rx DET_RANGE_029_Rx DET_CONFD_ELEVATION_030_Rx DET_CONFD_AZIMUTH_030_Rx DET_HVC_FLAG_030_Rx DET_EXISTENCE_PROB_030_Rx DET_SNR_030_Rx DET_SUPER_RES_TARGET_030_Rx DET_BI_STATIC_FLAG_030_Rx DET_RCS_030_Rx DET_ELEVATION_ERR_030_Rx DET_ELEVATION_030_Rx DET_AZIMUTH_ERR_030_Rx DET_AZIMUTH_030_Rx DET_RANGE_VELOCITY_ERR_030_Rx DET_RANGE_VELOCITY_030_Rx DET_RANGE_ERR_030_Rx DET_RANGE_030_Rx DET_CONFD_ELEVATION_031_Rx DET_CONFD_AZIMUTH_031_Rx DET_HVC_FLAG_031_Rx DET_EXISTENCE_PROB_031_Rx DET_SNR_031_Rx DET_SUPER_RES_TARGET_031_Rx DET_BI_STATIC_FLAG_031_Rx DET_RCS_031_Rx DET_ELEVATION_ERR_031_Rx DET_ELEVATION_031_Rx DET_AZIMUTH_ERR_031_Rx DET_AZIMUTH_031_Rx DET_RANGE_VELOCITY_ERR_031_Rx DET_RANGE_VELOCITY_031_Rx DET_RANGE_ERR_031_Rx DET_RANGE_031_Rx DET_CONFD_ELEVATION_032_Rx DET_CONFD_AZIMUTH_032_Rx DET_HVC_FLAG_032_Rx DET_EXISTENCE_PROB_032_Rx DET_SNR_032_Rx DET_SUPER_RES_TARGET_032_Rx DET_BI_STATIC_FLAG_032_Rx DET_RCS_032_Rx DET_ELEVATION_ERR_032_Rx DET_ELEVATION_032_Rx DET_AZIMUTH_ERR_032_Rx DET_AZIMUTH_032_Rx DET_RANGE_VELOCITY_ERR_032_Rx DET_RANGE_VELOCITY_032_Rx DET_RANGE_ERR_032_Rx DET_RANGE_032_Rx;
SIG_GROUP_ 264 Fusion_Detections_033_036 1 : DET_PROB_1STAZHYPO_033_Rx DET_PROB_1STAZHYPO_034_Rx DET_PROB_1STAZHYPO_035_Rx DET_PROB_1STAZHYPO_036_Rx DET_IDM_033_Rx DET_IDM_034_Rx DET_IDM_035_Rx DET_IDM_036_Rx DET_MTD_036_Rx DET_MTD_035_Rx DET_MTD_034_Rx DET_MTD_033_Rx DET_BELOW_RAIN_THOLD_036_Rx DET_BELOW_RAIN_THOLD_035_Rx DET_BELOW_RAIN_THOLD_034_Rx DET_BELOW_RAIN_THOLD_033_Rx DET_MH_CRC16_033_036_Rx DET_MH_CYCLE_COUNTER_033_036_Rx DET_MH_SCAN_INDEX_4LSB_033_036_R DET_CONFD_ELEVATION_033_Rx DET_CONFD_AZIMUTH_033_Rx DET_HVC_FLAG_033_Rx DET_EXISTENCE_PROB_033_Rx DET_SNR_033_Rx DET_SUPER_RES_TARGET_033_Rx DET_BI_STATIC_FLAG_033_Rx DET_RCS_033_Rx DET_ELEVATION_ERR_033_Rx DET_ELEVATION_033_Rx DET_AZIMUTH_ERR_033_Rx DET_AZIMUTH_033_Rx DET_RANGE_VELOCITY_ERR_033_Rx DET_RANGE_VELOCITY_033_Rx DET_RANGE_ERR_033_Rx DET_RANGE_033_Rx DET_CONFD_ELEVATION_034_Rx DET_CONFD_AZIMUTH_034_Rx DET_HVC_FLAG_034_Rx DET_EXISTENCE_PROB_034_Rx DET_SNR_034_Rx DET_SUPER_RES_TARGET_034_Rx DET_BI_STATIC_FLAG_034_Rx DET_RCS_034_Rx DET_ELEVATION_ERR_034_Rx DET_ELEVATION_034_Rx DET_AZIMUTH_ERR_034_Rx DET_AZIMUTH_034_Rx DET_RANGE_VELOCITY_ERR_034_Rx DET_RANGE_VELOCITY_034_Rx DET_RANGE_ERR_034_Rx DET_RANGE_034_Rx DET_CONFD_ELEVATION_035_Rx DET_CONFD_AZIMUTH_035_Rx DET_HVC_FLAG_035_Rx DET_EXISTENCE_PROB_035_Rx DET_SNR_035_Rx DET_SUPER_RES_TARGET_035_Rx DET_BI_STATIC_FLAG_035_Rx DET_RCS_035_Rx DET_ELEVATION_ERR_035_Rx DET_ELEVATION_035_Rx DET_AZIMUTH_ERR_035_Rx DET_AZIMUTH_035_Rx DET_RANGE_VELOCITY_ERR_035_Rx DET_RANGE_VELOCITY_035_Rx DET_RANGE_ERR_035_Rx DET_RANGE_035_Rx DET_CONFD_ELEVATION_036_Rx DET_CONFD_AZIMUTH_036_Rx DET_HVC_FLAG_036_Rx DET_EXISTENCE_PROB_036_Rx DET_SNR_036_Rx DET_SUPER_RES_TARGET_036_Rx DET_BI_STATIC_FLAG_036_Rx DET_RCS_036_Rx DET_ELEVATION_ERR_036_Rx DET_ELEVATION_036_Rx DET_AZIMUTH_ERR_036_Rx DET_AZIMUTH_036_Rx DET_RANGE_VELOCITY_ERR_036_Rx DET_RANGE_VELOCITY_036_Rx DET_RANGE_ERR_036_Rx DET_RANGE_036_Rx;
SIG_GROUP_ 265 Fusion_Detections_037_040 1 : DET_PROB_1STAZHYPO_037_Rx DET_PROB_1STAZHYPO_038_Rx DET_PROB_1STAZHYPO_039_Rx DET_PROB_1STAZHYPO_040_Rx DET_IDM_037_Rx DET_IDM_038_Rx DET_IDM_039_Rx DET_IDM_040_Rx DET_MTD_040_Rx DET_MTD_039_Rx DET_MTD_038_Rx DET_MTD_037_Rx DET_BELOW_RAIN_THOLD_040_Rx DET_BELOW_RAIN_THOLD_039_Rx DET_BELOW_RAIN_THOLD_038_Rx DET_BELOW_RAIN_THOLD_037_Rx DET_MH_CRC16_037_040_Rx DET_MH_CYCLE_COUNTER_037_040_Rx DET_MH_SCAN_INDEX_4LSB_037_040_R DET_CONFD_ELEVATION_037_Rx DET_CONFD_AZIMUTH_037_Rx DET_HVC_FLAG_037_Rx DET_EXISTENCE_PROB_037_Rx DET_SNR_037_Rx DET_SUPER_RES_TARGET_037_Rx DET_BI_STATIC_FLAG_037_Rx DET_RCS_037_Rx DET_ELEVATION_ERR_037_Rx DET_ELEVATION_037_Rx DET_AZIMUTH_ERR_037_Rx DET_AZIMUTH_037_Rx DET_RANGE_VELOCITY_ERR_037_Rx DET_RANGE_VELOCITY_037_Rx DET_RANGE_ERR_037_Rx DET_RANGE_037_Rx DET_CONFD_ELEVATION_038_Rx DET_CONFD_AZIMUTH_038_Rx DET_HVC_FLAG_038_Rx DET_EXISTENCE_PROB_038_Rx DET_SNR_038_Rx DET_SUPER_RES_TARGET_038_Rx DET_BI_STATIC_FLAG_038_Rx DET_RCS_038_Rx DET_ELEVATION_ERR_038_Rx DET_ELEVATION_038_Rx DET_AZIMUTH_ERR_038_Rx DET_AZIMUTH_038_Rx DET_RANGE_VELOCITY_ERR_038_Rx DET_RANGE_VELOCITY_038_Rx DET_RANGE_ERR_038_Rx DET_RANGE_038_Rx DET_CONFD_ELEVATION_039_Rx DET_CONFD_AZIMUTH_039_Rx DET_HVC_FLAG_039_Rx DET_EXISTENCE_PROB_039_Rx DET_SNR_039_Rx DET_SUPER_RES_TARGET_039_Rx DET_BI_STATIC_FLAG_039_Rx DET_RCS_039_Rx DET_ELEVATION_ERR_039_Rx DET_ELEVATION_039_Rx DET_AZIMUTH_ERR_039_Rx DET_AZIMUTH_039_Rx DET_RANGE_VELOCITY_ERR_039_Rx DET_RANGE_VELOCITY_039_Rx DET_RANGE_ERR_039_Rx DET_RANGE_039_Rx DET_CONFD_ELEVATION_040_Rx DET_CONFD_AZIMUTH_040_Rx DET_HVC_FLAG_040_Rx DET_EXISTENCE_PROB_040_Rx DET_SNR_040_Rx DET_SUPER_RES_TARGET_040_Rx DET_BI_STATIC_FLAG_040_Rx DET_RCS_040_Rx DET_ELEVATION_ERR_040_Rx DET_ELEVATION_040_Rx DET_AZIMUTH_ERR_040_Rx DET_AZIMUTH_040_Rx DET_RANGE_VELOCITY_ERR_040_Rx DET_RANGE_VELOCITY_040_Rx DET_RANGE_ERR_040_Rx DET_RANGE_040_Rx;
SIG_GROUP_ 266 Fusion_Detections_041_044 1 : DET_PROB_1STAZHYPO_041_Rx DET_PROB_1STAZHYPO_042_Rx DET_PROB_1STAZHYPO_043_Rx DET_PROB_1STAZHYPO_044_Rx DET_IDM_041_Rx DET_IDM_042_Rx DET_IDM_043_Rx DET_IDM_044_Rx DET_MTD_044_Rx DET_MTD_043_Rx DET_MTD_042_Rx DET_MTD_041_Rx DET_BELOW_RAIN_THOLD_044_Rx DET_BELOW_RAIN_THOLD_043_Rx DET_BELOW_RAIN_THOLD_042_Rx DET_BELOW_RAIN_THOLD_041_Rx DET_MH_CRC16_041_044_Rx DET_MH_CYCLE_COUNTER_041_044_Rx DET_MH_SCAN_INDEX_4LSB_041_044_R DET_CONFD_ELEVATION_041_Rx DET_CONFD_AZIMUTH_041_Rx DET_HVC_FLAG_041_Rx DET_EXISTENCE_PROB_041_Rx DET_SNR_041_Rx DET_SUPER_RES_TARGET_041_Rx DET_BI_STATIC_FLAG_041_Rx DET_RCS_041_Rx DET_ELEVATION_ERR_041_Rx DET_ELEVATION_041_Rx DET_AZIMUTH_ERR_041_Rx DET_AZIMUTH_041_Rx DET_RANGE_VELOCITY_ERR_041_Rx DET_RANGE_VELOCITY_041_Rx DET_RANGE_ERR_041_Rx DET_RANGE_041_Rx DET_CONFD_ELEVATION_042_Rx DET_CONFD_AZIMUTH_042_Rx DET_HVC_FLAG_042_Rx DET_EXISTENCE_PROB_042_Rx DET_SNR_042_Rx DET_SUPER_RES_TARGET_042_Rx DET_BI_STATIC_FLAG_042_Rx DET_RCS_042_Rx DET_ELEVATION_ERR_042_Rx DET_ELEVATION_042_Rx DET_AZIMUTH_ERR_042_Rx DET_AZIMUTH_042_Rx DET_RANGE_VELOCITY_ERR_042_Rx DET_RANGE_VELOCITY_042_Rx DET_RANGE_ERR_042_Rx DET_RANGE_042_Rx DET_CONFD_ELEVATION_043_Rx DET_CONFD_AZIMUTH_043_Rx DET_HVC_FLAG_043_Rx DET_EXISTENCE_PROB_043_Rx DET_SNR_043_Rx DET_SUPER_RES_TARGET_043_Rx DET_BI_STATIC_FLAG_043_Rx DET_RCS_043_Rx DET_ELEVATION_ERR_043_Rx DET_ELEVATION_043_Rx DET_AZIMUTH_ERR_043_Rx DET_AZIMUTH_043_Rx DET_RANGE_VELOCITY_ERR_043_Rx DET_RANGE_VELOCITY_043_Rx DET_RANGE_ERR_043_Rx DET_RANGE_043_Rx DET_CONFD_ELEVATION_044_Rx DET_CONFD_AZIMUTH_044_Rx DET_HVC_FLAG_044_Rx DET_EXISTENCE_PROB_044_Rx DET_SNR_044_Rx DET_SUPER_RES_TARGET_044_Rx DET_BI_STATIC_FLAG_044_Rx DET_RCS_044_Rx DET_ELEVATION_ERR_044_Rx DET_ELEVATION_044_Rx DET_AZIMUTH_ERR_044_Rx DET_AZIMUTH_044_Rx DET_RANGE_VELOCITY_ERR_044_Rx DET_RANGE_VELOCITY_044_Rx DET_RANGE_ERR_044_Rx DET_RANGE_044_Rx;
SIG_GROUP_ 267 Fusion_Detections_045_048 1 : DET_PROB_1STAZHYPO_045_Rx DET_PROB_1STAZHYPO_046_Rx DET_PROB_1STAZHYPO_047_Rx DET_PROB_1STAZHYPO_048_Rx DET_IDM_045_Rx DET_IDM_046_Rx DET_IDM_047_Rx DET_IDM_048_Rx DET_MTD_048_Rx DET_MTD_047_Rx DET_MTD_046_Rx DET_MTD_045_Rx DET_BELOW_RAIN_THOLD_048_Rx DET_BELOW_RAIN_THOLD_047_Rx DET_BELOW_RAIN_THOLD_046_Rx DET_BELOW_RAIN_THOLD_045_Rx DET_MH_CRC16_045_048_Rx DET_MH_CYCLE_COUNTER_045_048_Rx DET_MH_SCAN_INDEX_4LSB_045_048_R DET_CONFD_ELEVATION_045_Rx DET_CONFD_AZIMUTH_045_Rx DET_HVC_FLAG_045_Rx DET_EXISTENCE_PROB_045_Rx DET_SNR_045_Rx DET_SUPER_RES_TARGET_045_Rx DET_BI_STATIC_FLAG_045_Rx DET_RCS_045_Rx DET_ELEVATION_ERR_045_Rx DET_ELEVATION_045_Rx DET_AZIMUTH_ERR_045_Rx DET_AZIMUTH_045_Rx DET_RANGE_VELOCITY_ERR_045_Rx DET_RANGE_VELOCITY_045_Rx DET_RANGE_ERR_045_Rx DET_RANGE_045_Rx DET_CONFD_ELEVATION_046_Rx DET_CONFD_AZIMUTH_046_Rx DET_HVC_FLAG_046_Rx DET_EXISTENCE_PROB_046_Rx DET_SNR_046_Rx DET_SUPER_RES_TARGET_046_Rx DET_BI_STATIC_FLAG_046_Rx DET_RCS_046_Rx DET_ELEVATION_ERR_046_Rx DET_ELEVATION_046_Rx DET_AZIMUTH_ERR_046_Rx DET_AZIMUTH_046_Rx DET_RANGE_VELOCITY_ERR_046_Rx DET_RANGE_VELOCITY_046_Rx DET_RANGE_ERR_046_Rx DET_RANGE_046_Rx DET_CONFD_ELEVATION_047_Rx DET_CONFD_AZIMUTH_047_Rx DET_HVC_FLAG_047_Rx DET_EXISTENCE_PROB_047_Rx DET_SNR_047_Rx DET_SUPER_RES_TARGET_047_Rx DET_BI_STATIC_FLAG_047_Rx DET_RCS_047_Rx DET_ELEVATION_ERR_047_Rx DET_ELEVATION_047_Rx DET_AZIMUTH_ERR_047_Rx DET_AZIMUTH_047_Rx DET_RANGE_VELOCITY_ERR_047_Rx DET_RANGE_VELOCITY_047_Rx DET_RANGE_ERR_047_Rx DET_RANGE_047_Rx DET_CONFD_ELEVATION_048_Rx DET_CONFD_AZIMUTH_048_Rx DET_HVC_FLAG_048_Rx DET_EXISTENCE_PROB_048_Rx DET_SNR_048_Rx DET_SUPER_RES_TARGET_048_Rx DET_BI_STATIC_FLAG_048_Rx DET_RCS_048_Rx DET_ELEVATION_ERR_048_Rx DET_ELEVATION_048_Rx DET_AZIMUTH_ERR_048_Rx DET_AZIMUTH_048_Rx DET_RANGE_VELOCITY_ERR_048_Rx DET_RANGE_VELOCITY_048_Rx DET_RANGE_ERR_048_Rx DET_RANGE_048_Rx;
